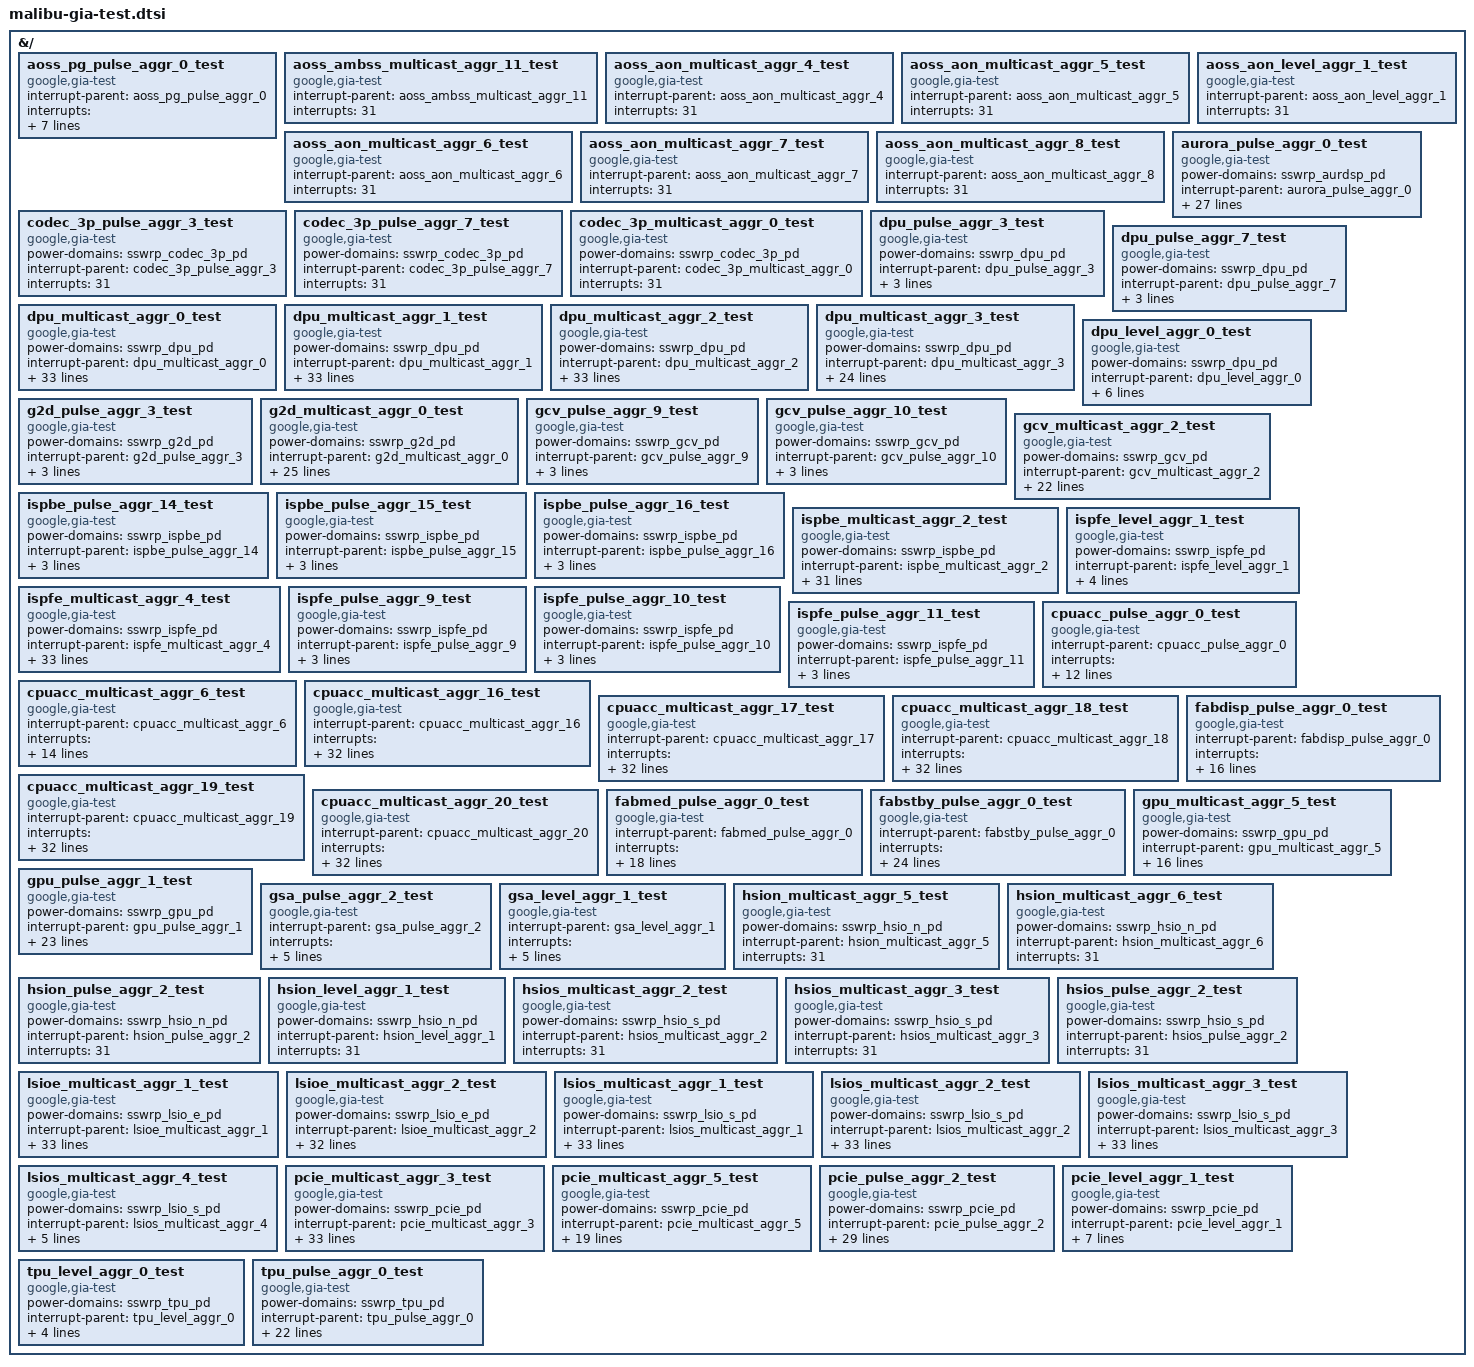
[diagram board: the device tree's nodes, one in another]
// SPDX-License-Identifier: GPL-2.0-only OR BSD-3-Clause
/*
 * !!!!!!!!!!!!!!!!!!!!!!!!!!!!!!!!!!!!!!!!!!!!!!!!!
 * !!!!! THIS IS A GENERATED FILE, DO NOT EDIT !!!!!
 * !!!!!!!!!!!!!!!!!!!!!!!!!!!!!!!!!!!!!!!!!!!!!!!!!
 *
 * This file provides test nodes for use with the GIA test driver
 * Generate using scripts/irqchip/gen-test-gia-dt-nodes.py
 *
 * Copyright 2024-2025 Google LLC
 */

#include <dt-bindings/interrupt-controller/mbu-gic.h>
#include <dt-bindings/interrupt-controller/irq-gia-google-mbu.h>

&{/} {
	aoss_pg_pulse_aggr_0_test: aoss_pg_pulse_aggr_0_test {
		compatible = "google,gia-test";
		interrupt-parent = <&aoss_pg_pulse_aggr_0>;
		interrupts =
			<AOSS_GIA_PULSE_AGGR_0_AUX_PARTITION_TBU_WRAPPER_TBU_RAS_FHI>,
			<AOSS_GIA_PULSE_AGGR_1_AUX_PARTITION_TBU_WRAPPER_TBU_RAS_ERI>,
			<AOSS_GIA_PULSE_AGGR_2_AUX_PARTITION_TBU_WRAPPER_TBU_RAS_CRI>,
			<AOSS_GIA_PULSE_AGGR_3_AUX_PARTITION_TBU_WRAPPER_TBU_PMU_IRPT>,
			<AOSS_GIA_PULSE_AGGR_4_AUX_GSPAN_AXI4_INIT_DNSTRM_ICD_ERR_DSCGT>,
			<AOSS_GIA_PULSE_AGGR_5_AUX_GSPAN_AXI4_INIT_PCIET_ICD_ERR_DSCGT>,
			<AOSS_GIA_PULSE_AGGR_6_AUX_GSPAN_ATB_INIT_INST_ICD_ERR_DSCGT>;
		interrupt-names =
			"AOSS_GIA_PULSE_AGGR_0_AUX_PARTITION_TBU_WRAPPER_TBU_RAS_FHI",
			"AOSS_GIA_PULSE_AGGR_1_AUX_PARTITION_TBU_WRAPPER_TBU_RAS_ERI",
			"AOSS_GIA_PULSE_AGGR_2_AUX_PARTITION_TBU_WRAPPER_TBU_RAS_CRI",
			"AOSS_GIA_PULSE_AGGR_3_AUX_PARTITION_TBU_WRAPPER_TBU_PMU_IRPT",
			"AOSS_GIA_PULSE_AGGR_4_AUX_GSPAN_AXI4_INIT_DNSTRM_ICD_ERR_DSCGT",
			"AOSS_GIA_PULSE_AGGR_5_AUX_GSPAN_AXI4_INIT_PCIET_ICD_ERR_DSCGT",
			"AOSS_GIA_PULSE_AGGR_6_AUX_GSPAN_ATB_INIT_INST_ICD_ERR_DSCGT";
	};

	aoss_ambss_multicast_aggr_11_test: aoss_ambss_multicast_aggr_11_test {
		compatible = "google,gia-test";
		interrupt-parent = <&aoss_ambss_multicast_aggr_11>;
		interrupts =
			<31>;
		interrupt-names =
			"TEST_LINE_31";
	};

	aoss_aon_multicast_aggr_4_test: aoss_aon_multicast_aggr_4_test {
		compatible = "google,gia-test";
		interrupt-parent = <&aoss_aon_multicast_aggr_4>;
		interrupts =
			<31>;
		interrupt-names =
			"TEST_LINE_31";
	};

	aoss_aon_multicast_aggr_5_test: aoss_aon_multicast_aggr_5_test {
		compatible = "google,gia-test";
		interrupt-parent = <&aoss_aon_multicast_aggr_5>;
		interrupts =
			<31>;
		interrupt-names =
			"TEST_LINE_31";
	};

	aoss_aon_multicast_aggr_6_test: aoss_aon_multicast_aggr_6_test {
		compatible = "google,gia-test";
		interrupt-parent = <&aoss_aon_multicast_aggr_6>;
		interrupts =
			<31>;
		interrupt-names =
			"TEST_LINE_31";
	};

	aoss_aon_multicast_aggr_7_test: aoss_aon_multicast_aggr_7_test {
		compatible = "google,gia-test";
		interrupt-parent = <&aoss_aon_multicast_aggr_7>;
		interrupts =
			<31>;
		interrupt-names =
			"TEST_LINE_31";
	};

	aoss_aon_multicast_aggr_8_test: aoss_aon_multicast_aggr_8_test {
		compatible = "google,gia-test";
		interrupt-parent = <&aoss_aon_multicast_aggr_8>;
		interrupts =
			<31>;
		interrupt-names =
			"TEST_LINE_31";
	};

	aoss_aon_level_aggr_1_test: aoss_aon_level_aggr_1_test {
		compatible = "google,gia-test";
		interrupt-parent = <&aoss_aon_level_aggr_1>;
		interrupts =
			<31>;
		interrupt-names =
			"TEST_LINE_31";
	};

	aurora_pulse_aggr_0_test: aurora_pulse_aggr_0_test {
		compatible = "google,gia-test";
		power-domains = <&sswrp_aurdsp_pd>;
		interrupt-parent = <&aurora_pulse_aggr_0>;
		interrupts =
			<AURORA_GIA_PULSE_AGGR_0_AUX_GSPAN_CORE_0_ICD_ERR_DSCGT>,
			<AURORA_GIA_PULSE_AGGR_0_AUX_GSPAN_CORE_1_ICD_ERR_DSCGT>,
			<AURORA_GIA_PULSE_AGGR_0_AUX_GSPAN_TCU_MCU_ICD_ERR_DSCGT>,
			<AURORA_GIA_PULSE_AGGR_0_AUX_GSPAN_ATB_ICD_ERR_DSCGT>,
			<AURORA_GIA_PULSE_AGGR_0_AUX_CTRL_NOC_XBA00_ERR_IRQ>,
			<AURORA_GIA_PULSE_AGGR_0_AUX_SMMU_TBU0_RAS_FHI>,
			<AURORA_GIA_PULSE_AGGR_0_AUX_SMMU_TBU0_RAS_ERI>,
			<AURORA_GIA_PULSE_AGGR_0_AUX_SMMU_TBU0_RAS_CRI>,
			<AURORA_GIA_PULSE_AGGR_0_AUX_SMMU_TBU0_PMU_IRPT>,
			<AURORA_GIA_PULSE_AGGR_0_AUX_SMMU_TBU1_RAS_FHI>,
			<AURORA_GIA_PULSE_AGGR_0_AUX_SMMU_TBU1_RAS_ERI>,
			<AURORA_GIA_PULSE_AGGR_0_AUX_SMMU_TBU1_RAS_CRI>,
			<AURORA_GIA_PULSE_AGGR_0_AUX_SMMU_TBU1_PMU_IRPT>,
			<AURORA_GIA_PULSE_AGGR_0_AUX_SMMU_TBU2_RAS_FHI>,
			<AURORA_GIA_PULSE_AGGR_0_AUX_SMMU_TBU2_RAS_ERI>,
			<AURORA_GIA_PULSE_AGGR_0_AUX_SMMU_TBU2_RAS_CRI>,
			<AURORA_GIA_PULSE_AGGR_0_AUX_SMMU_TBU2_PMU_IRPT>,
			<AURORA_GIA_PULSE_AGGR_0_AUX_SMMU_TCU_RAS_FHI>,
			<AURORA_GIA_PULSE_AGGR_0_AUX_SMMU_TCU_RAS_ERI>,
			<AURORA_GIA_PULSE_AGGR_0_AUX_SMMU_TCU_RAS_CRI>,
			<AURORA_GIA_PULSE_AGGR_0_AUX_SMMU_TCU_PMU_IRPT>,
			<AURORA_GIA_PULSE_AGGR_0_AUX_SMMU_TCU_PRI_Q_IRPT_NS>,
			<AURORA_GIA_PULSE_AGGR_0_AUX_SMMU_TCU_GLOBAL_IRPT_NS>,
			<AURORA_GIA_PULSE_AGGR_0_AUX_SMMU_TCU_CMD_SYNC_IRPT_NS>,
			<AURORA_GIA_PULSE_AGGR_0_AUX_SMMU_TCU_EVENT_Q_IRPT_NS>,
			<31>;
		interrupt-names =
			"AURORA_GIA_PULSE_AGGR_0_AUX_GSPAN_CORE_0_ICD_ERR_DSCGT",
			"AURORA_GIA_PULSE_AGGR_0_AUX_GSPAN_CORE_1_ICD_ERR_DSCGT",
			"AURORA_GIA_PULSE_AGGR_0_AUX_GSPAN_TCU_MCU_ICD_ERR_DSCGT",
			"AURORA_GIA_PULSE_AGGR_0_AUX_GSPAN_ATB_ICD_ERR_DSCGT",
			"AURORA_GIA_PULSE_AGGR_0_AUX_CTRL_NOC_XBA00_ERR_IRQ",
			"AURORA_GIA_PULSE_AGGR_0_AUX_SMMU_TBU0_RAS_FHI",
			"AURORA_GIA_PULSE_AGGR_0_AUX_SMMU_TBU0_RAS_ERI",
			"AURORA_GIA_PULSE_AGGR_0_AUX_SMMU_TBU0_RAS_CRI",
			"AURORA_GIA_PULSE_AGGR_0_AUX_SMMU_TBU0_PMU_IRPT",
			"AURORA_GIA_PULSE_AGGR_0_AUX_SMMU_TBU1_RAS_FHI",
			"AURORA_GIA_PULSE_AGGR_0_AUX_SMMU_TBU1_RAS_ERI",
			"AURORA_GIA_PULSE_AGGR_0_AUX_SMMU_TBU1_RAS_CRI",
			"AURORA_GIA_PULSE_AGGR_0_AUX_SMMU_TBU1_PMU_IRPT",
			"AURORA_GIA_PULSE_AGGR_0_AUX_SMMU_TBU2_RAS_FHI",
			"AURORA_GIA_PULSE_AGGR_0_AUX_SMMU_TBU2_RAS_ERI",
			"AURORA_GIA_PULSE_AGGR_0_AUX_SMMU_TBU2_RAS_CRI",
			"AURORA_GIA_PULSE_AGGR_0_AUX_SMMU_TBU2_PMU_IRPT",
			"AURORA_GIA_PULSE_AGGR_0_AUX_SMMU_TCU_RAS_FHI",
			"AURORA_GIA_PULSE_AGGR_0_AUX_SMMU_TCU_RAS_ERI",
			"AURORA_GIA_PULSE_AGGR_0_AUX_SMMU_TCU_RAS_CRI",
			"AURORA_GIA_PULSE_AGGR_0_AUX_SMMU_TCU_PMU_IRPT",
			"AURORA_GIA_PULSE_AGGR_0_AUX_SMMU_TCU_PRI_Q_IRPT_NS",
			"AURORA_GIA_PULSE_AGGR_0_AUX_SMMU_TCU_GLOBAL_IRPT_NS",
			"AURORA_GIA_PULSE_AGGR_0_AUX_SMMU_TCU_CMD_SYNC_IRPT_NS",
			"AURORA_GIA_PULSE_AGGR_0_AUX_SMMU_TCU_EVENT_Q_IRPT_NS",
			"TEST_LINE_31";
	};

	codec_3p_pulse_aggr_3_test: codec_3p_pulse_aggr_3_test {
		compatible = "google,gia-test";
		power-domains = <&sswrp_codec_3p_pd>;
		interrupt-parent = <&codec_3p_pulse_aggr_3>;
		interrupts =
			<31>;
		interrupt-names =
			"TEST_LINE_31";
	};

	codec_3p_pulse_aggr_7_test: codec_3p_pulse_aggr_7_test {
		compatible = "google,gia-test";
		power-domains = <&sswrp_codec_3p_pd>;
		interrupt-parent = <&codec_3p_pulse_aggr_7>;
		interrupts =
			<31>;
		interrupt-names =
			"TEST_LINE_31";
	};

	codec_3p_multicast_aggr_0_test: codec_3p_multicast_aggr_0_test {
		compatible = "google,gia-test";
		power-domains = <&sswrp_codec_3p_pd>;
		interrupt-parent = <&codec_3p_multicast_aggr_0>;
		interrupts =
			<31>;
		interrupt-names =
			"TEST_LINE_31";
	};

	dpu_pulse_aggr_3_test: dpu_pulse_aggr_3_test {
		compatible = "google,gia-test";
		power-domains = <&sswrp_dpu_pd>;
		interrupt-parent = <&dpu_pulse_aggr_3>;
		interrupts =
			<DPU_GIA_PULSE_AGGR_3_AUX_CORE_CORE_TBU_WRAPPER_0_TBU_PMU_IRPT>,
			<31>;
		interrupt-names =
			"DPU_GIA_PULSE_AGGR_3_AUX_CORE_CORE_TBU_WRAPPER_0_TBU_PMU_IRPT",
			"TEST_LINE_31";
	};

	dpu_pulse_aggr_7_test: dpu_pulse_aggr_7_test {
		compatible = "google,gia-test";
		power-domains = <&sswrp_dpu_pd>;
		interrupt-parent = <&dpu_pulse_aggr_7>;
		interrupts =
			<DPU_GIA_PULSE_AGGR_7_AUX_CORE_CORE_TBU_WRAPPER_1_TBU_PMU_IRPT>,
			<31>;
		interrupt-names =
			"DPU_GIA_PULSE_AGGR_7_AUX_CORE_CORE_TBU_WRAPPER_1_TBU_PMU_IRPT",
			"TEST_LINE_31";
	};

	dpu_multicast_aggr_0_test: dpu_multicast_aggr_0_test {
		compatible = "google,gia-test";
		power-domains = <&sswrp_dpu_pd>;
		interrupt-parent = <&dpu_multicast_aggr_0>;
		interrupts =
			<DPU_GIA_MULTICAST_AGGR_0_FE_0_IRQ_DPU_FE_PVRIC_DECODE_ERROR_0>,
			<DPU_GIA_MULTICAST_AGGR_0_FE_0_IRQ_DPU_FE_PVRIC_DECODE_ERROR_1>,
			<DPU_GIA_MULTICAST_AGGR_0_FE_0_IRQ_DPU_FE_PVRIC_DECODE_ERROR_2>,
			<DPU_GIA_MULTICAST_AGGR_0_FE_0_IRQ_DPU_FE_PVRIC_DECODE_ERROR_3>,
			<DPU_GIA_MULTICAST_AGGR_0_FE_0_IRQ_DPU_FE_PVRIC_DECODE_ERROR_4>,
			<DPU_GIA_MULTICAST_AGGR_0_FE_0_IRQ_DPU_FE_PVRIC_DECODE_ERROR_5>,
			<DPU_GIA_MULTICAST_AGGR_0_FE_0_IRQ_DPU_FE_LAYER_FRM_DONE_0>,
			<DPU_GIA_MULTICAST_AGGR_0_FE_0_IRQ_DPU_FE_LAYER_FRM_DONE_1>,
			<DPU_GIA_MULTICAST_AGGR_0_FE_0_IRQ_DPU_FE_LAYER_FRM_DONE_2>,
			<DPU_GIA_MULTICAST_AGGR_0_FE_0_IRQ_DPU_FE_LAYER_FRM_DONE_3>,
			<DPU_GIA_MULTICAST_AGGR_0_FE_0_IRQ_DPU_FE_LAYER_FRM_DONE_4>,
			<DPU_GIA_MULTICAST_AGGR_0_FE_0_IRQ_DPU_FE_LAYER_FRM_DONE_5>,
			<DPU_GIA_MULTICAST_AGGR_0_FE_0_IRQ_DPU_FE_AXI_HANG_0>,
			<DPU_GIA_MULTICAST_AGGR_0_FE_0_IRQ_DPU_FE_AXI_HANG_1>,
			<DPU_GIA_MULTICAST_AGGR_0_FE_0_IRQ_DPU_FE_AXI_BUS_ERROR_0>,
			<DPU_GIA_MULTICAST_AGGR_0_FE_0_IRQ_DPU_FE_AXI_BUS_ERROR_1>,
			<DPU_GIA_MULTICAST_AGGR_0_FE_0_IRQ_FE_APB_HANG>,
			<DPU_GIA_MULTICAST_AGGR_0_FE_0_IRQ_FE_SW_RST_DONE>,
			<DPU_GIA_MULTICAST_AGGR_0_FE_1_IRQ_DPU_FE_PVRIC_DECODE_ERROR_0>,
			<DPU_GIA_MULTICAST_AGGR_0_FE_1_IRQ_DPU_FE_PVRIC_DECODE_ERROR_1>,
			<DPU_GIA_MULTICAST_AGGR_0_FE_1_IRQ_DPU_FE_PVRIC_DECODE_ERROR_2>,
			<DPU_GIA_MULTICAST_AGGR_0_FE_1_IRQ_DPU_FE_PVRIC_DECODE_ERROR_3>,
			<DPU_GIA_MULTICAST_AGGR_0_FE_1_IRQ_DPU_FE_PVRIC_DECODE_ERROR_4>,
			<DPU_GIA_MULTICAST_AGGR_0_FE_1_IRQ_DPU_FE_PVRIC_DECODE_ERROR_5>,
			<DPU_GIA_MULTICAST_AGGR_0_FE_1_IRQ_DPU_FE_LAYER_FRM_DONE_0>,
			<DPU_GIA_MULTICAST_AGGR_0_FE_1_IRQ_DPU_FE_LAYER_FRM_DONE_1>,
			<DPU_GIA_MULTICAST_AGGR_0_FE_1_IRQ_DPU_FE_LAYER_FRM_DONE_2>,
			<DPU_GIA_MULTICAST_AGGR_0_FE_1_IRQ_DPU_FE_LAYER_FRM_DONE_3>,
			<DPU_GIA_MULTICAST_AGGR_0_FE_1_IRQ_DPU_FE_LAYER_FRM_DONE_4>,
			<DPU_GIA_MULTICAST_AGGR_0_FE_1_IRQ_DPU_FE_LAYER_FRM_DONE_5>,
			<DPU_GIA_MULTICAST_AGGR_0_FE_1_IRQ_DPU_FE_AXI_HANG_0>,
			<DPU_GIA_MULTICAST_AGGR_0_FE_1_IRQ_DPU_FE_AXI_HANG_1>;
		interrupt-names =
			"DPU_GIA_MULTICAST_AGGR_0_FE_0_IRQ_DPU_FE_PVRIC_DECODE_ERROR_0",
			"DPU_GIA_MULTICAST_AGGR_0_FE_0_IRQ_DPU_FE_PVRIC_DECODE_ERROR_1",
			"DPU_GIA_MULTICAST_AGGR_0_FE_0_IRQ_DPU_FE_PVRIC_DECODE_ERROR_2",
			"DPU_GIA_MULTICAST_AGGR_0_FE_0_IRQ_DPU_FE_PVRIC_DECODE_ERROR_3",
			"DPU_GIA_MULTICAST_AGGR_0_FE_0_IRQ_DPU_FE_PVRIC_DECODE_ERROR_4",
			"DPU_GIA_MULTICAST_AGGR_0_FE_0_IRQ_DPU_FE_PVRIC_DECODE_ERROR_5",
			"DPU_GIA_MULTICAST_AGGR_0_FE_0_IRQ_DPU_FE_LAYER_FRM_DONE_0",
			"DPU_GIA_MULTICAST_AGGR_0_FE_0_IRQ_DPU_FE_LAYER_FRM_DONE_1",
			"DPU_GIA_MULTICAST_AGGR_0_FE_0_IRQ_DPU_FE_LAYER_FRM_DONE_2",
			"DPU_GIA_MULTICAST_AGGR_0_FE_0_IRQ_DPU_FE_LAYER_FRM_DONE_3",
			"DPU_GIA_MULTICAST_AGGR_0_FE_0_IRQ_DPU_FE_LAYER_FRM_DONE_4",
			"DPU_GIA_MULTICAST_AGGR_0_FE_0_IRQ_DPU_FE_LAYER_FRM_DONE_5",
			"DPU_GIA_MULTICAST_AGGR_0_FE_0_IRQ_DPU_FE_AXI_HANG_0",
			"DPU_GIA_MULTICAST_AGGR_0_FE_0_IRQ_DPU_FE_AXI_HANG_1",
			"DPU_GIA_MULTICAST_AGGR_0_FE_0_IRQ_DPU_FE_AXI_BUS_ERROR_0",
			"DPU_GIA_MULTICAST_AGGR_0_FE_0_IRQ_DPU_FE_AXI_BUS_ERROR_1",
			"DPU_GIA_MULTICAST_AGGR_0_FE_0_IRQ_FE_APB_HANG",
			"DPU_GIA_MULTICAST_AGGR_0_FE_0_IRQ_FE_SW_RST_DONE",
			"DPU_GIA_MULTICAST_AGGR_0_FE_1_IRQ_DPU_FE_PVRIC_DECODE_ERROR_0",
			"DPU_GIA_MULTICAST_AGGR_0_FE_1_IRQ_DPU_FE_PVRIC_DECODE_ERROR_1",
			"DPU_GIA_MULTICAST_AGGR_0_FE_1_IRQ_DPU_FE_PVRIC_DECODE_ERROR_2",
			"DPU_GIA_MULTICAST_AGGR_0_FE_1_IRQ_DPU_FE_PVRIC_DECODE_ERROR_3",
			"DPU_GIA_MULTICAST_AGGR_0_FE_1_IRQ_DPU_FE_PVRIC_DECODE_ERROR_4",
			"DPU_GIA_MULTICAST_AGGR_0_FE_1_IRQ_DPU_FE_PVRIC_DECODE_ERROR_5",
			"DPU_GIA_MULTICAST_AGGR_0_FE_1_IRQ_DPU_FE_LAYER_FRM_DONE_0",
			"DPU_GIA_MULTICAST_AGGR_0_FE_1_IRQ_DPU_FE_LAYER_FRM_DONE_1",
			"DPU_GIA_MULTICAST_AGGR_0_FE_1_IRQ_DPU_FE_LAYER_FRM_DONE_2",
			"DPU_GIA_MULTICAST_AGGR_0_FE_1_IRQ_DPU_FE_LAYER_FRM_DONE_3",
			"DPU_GIA_MULTICAST_AGGR_0_FE_1_IRQ_DPU_FE_LAYER_FRM_DONE_4",
			"DPU_GIA_MULTICAST_AGGR_0_FE_1_IRQ_DPU_FE_LAYER_FRM_DONE_5",
			"DPU_GIA_MULTICAST_AGGR_0_FE_1_IRQ_DPU_FE_AXI_HANG_0",
			"DPU_GIA_MULTICAST_AGGR_0_FE_1_IRQ_DPU_FE_AXI_HANG_1";
	};

	dpu_multicast_aggr_1_test: dpu_multicast_aggr_1_test {
		compatible = "google,gia-test";
		power-domains = <&sswrp_dpu_pd>;
		interrupt-parent = <&dpu_multicast_aggr_1>;
		interrupts =
			<DPU_GIA_MULTICAST_AGGR_1_FE_1_IRQ_DPU_FE_AXI_BUS_ERROR_0>,
			<DPU_GIA_MULTICAST_AGGR_1_FE_1_IRQ_DPU_FE_AXI_BUS_ERROR_1>,
			<DPU_GIA_MULTICAST_AGGR_1_FE_1_IRQ_FE_APB_HANG>,
			<DPU_GIA_MULTICAST_AGGR_1_FE_1_IRQ_FE_SW_RST_DONE>,
			<DPU_GIA_MULTICAST_AGGR_1_BE_IRQ_BE_OUTPATH0_FRM_START>,
			<DPU_GIA_MULTICAST_AGGR_1_BE_IRQ_BE_OUTPATH0_FRM_DONE>,
			<DPU_GIA_MULTICAST_AGGR_1_BE_IRQ_BE_OUTPATH0_UNDERRUN>,
			<DPU_GIA_MULTICAST_AGGR_1_BE_IRQ_BE_OUTPATH0_INTRA_FRM_INT>,
			<DPU_GIA_MULTICAST_AGGR_1_BE_IRQ_BE_OUTPATH0_INTRA_FRM_EXT>,
			<DPU_GIA_MULTICAST_AGGR_1_BE_IRQ_BE_OUTPATH0_LTM_FRM_START>,
			<DPU_GIA_MULTICAST_AGGR_1_BE_IRQ_BE_OUTPATH0_LTM_FRM_DONE>,
			<DPU_GIA_MULTICAST_AGGR_1_BE_IRQ_BE_OUTPATH0_DSC_ENC0_INTR>,
			<DPU_GIA_MULTICAST_AGGR_1_BE_IRQ_BE_OUTPATH0_DSC_ENC1_INTR>,
			<DPU_GIA_MULTICAST_AGGR_1_BE_IRQ_BE_OUTPATH0_VDC_INTR>,
			<DPU_GIA_MULTICAST_AGGR_1_BE_IRQ_BE_OUTPATH0_HIST_WB_DONE>,
			<DPU_GIA_MULTICAST_AGGR_1_BE_IRQ_BE_OUTPATH0_HISTRGB_WB_DONE>,
			<DPU_GIA_MULTICAST_AGGR_1_BE_IRQ_BE_OUTPATH1_FRM_START>,
			<DPU_GIA_MULTICAST_AGGR_1_BE_IRQ_BE_OUTPATH1_FRM_DONE>,
			<DPU_GIA_MULTICAST_AGGR_1_BE_IRQ_BE_OUTPATH1_UNDERRUN>,
			<DPU_GIA_MULTICAST_AGGR_1_BE_IRQ_BE_OUTPATH1_INTRA_FRM_INT>,
			<DPU_GIA_MULTICAST_AGGR_1_BE_IRQ_BE_OUTPATH1_INTRA_FRM_EXT>,
			<DPU_GIA_MULTICAST_AGGR_1_BE_IRQ_BE_OUTPATH1_DSC_ENC0_INTR>,
			<DPU_GIA_MULTICAST_AGGR_1_BE_IRQ_BE_OUTPATH1_DSC_ENC1_INTR>,
			<DPU_GIA_MULTICAST_AGGR_1_BE_IRQ_BE_OUTPATH1_HIST_WB_DONE>,
			<DPU_GIA_MULTICAST_AGGR_1_BE_IRQ_BE_OUTPATH2_FRM_START>,
			<DPU_GIA_MULTICAST_AGGR_1_BE_IRQ_BE_OUTPATH2_FRM_DONE>,
			<DPU_GIA_MULTICAST_AGGR_1_BE_IRQ_BE_OUTPATH2_UNDERRUN>,
			<DPU_GIA_MULTICAST_AGGR_1_BE_IRQ_BE_OUTPATH2_INTRA_FRM_INT>,
			<DPU_GIA_MULTICAST_AGGR_1_BE_IRQ_BE_OUTPATH2_DSC_ENC0_INTR>,
			<DPU_GIA_MULTICAST_AGGR_1_BE_IRQ_BE_OUTPATH2_DSC_ENC1_INTR>,
			<DPU_GIA_MULTICAST_AGGR_1_BE_IRQ_BE_OUTPATH3_FRM_START>,
			<DPU_GIA_MULTICAST_AGGR_1_BE_IRQ_BE_OUTPATH3_FRM_DONE>;
		interrupt-names =
			"DPU_GIA_MULTICAST_AGGR_1_FE_1_IRQ_DPU_FE_AXI_BUS_ERROR_0",
			"DPU_GIA_MULTICAST_AGGR_1_FE_1_IRQ_DPU_FE_AXI_BUS_ERROR_1",
			"DPU_GIA_MULTICAST_AGGR_1_FE_1_IRQ_FE_APB_HANG",
			"DPU_GIA_MULTICAST_AGGR_1_FE_1_IRQ_FE_SW_RST_DONE",
			"DPU_GIA_MULTICAST_AGGR_1_BE_IRQ_BE_OUTPATH0_FRM_START",
			"DPU_GIA_MULTICAST_AGGR_1_BE_IRQ_BE_OUTPATH0_FRM_DONE",
			"DPU_GIA_MULTICAST_AGGR_1_BE_IRQ_BE_OUTPATH0_UNDERRUN",
			"DPU_GIA_MULTICAST_AGGR_1_BE_IRQ_BE_OUTPATH0_INTRA_FRM_INT",
			"DPU_GIA_MULTICAST_AGGR_1_BE_IRQ_BE_OUTPATH0_INTRA_FRM_EXT",
			"DPU_GIA_MULTICAST_AGGR_1_BE_IRQ_BE_OUTPATH0_LTM_FRM_START",
			"DPU_GIA_MULTICAST_AGGR_1_BE_IRQ_BE_OUTPATH0_LTM_FRM_DONE",
			"DPU_GIA_MULTICAST_AGGR_1_BE_IRQ_BE_OUTPATH0_DSC_ENC0_INTR",
			"DPU_GIA_MULTICAST_AGGR_1_BE_IRQ_BE_OUTPATH0_DSC_ENC1_INTR",
			"DPU_GIA_MULTICAST_AGGR_1_BE_IRQ_BE_OUTPATH0_VDC_INTR",
			"DPU_GIA_MULTICAST_AGGR_1_BE_IRQ_BE_OUTPATH0_HIST_WB_DONE",
			"DPU_GIA_MULTICAST_AGGR_1_BE_IRQ_BE_OUTPATH0_HISTRGB_WB_DONE",
			"DPU_GIA_MULTICAST_AGGR_1_BE_IRQ_BE_OUTPATH1_FRM_START",
			"DPU_GIA_MULTICAST_AGGR_1_BE_IRQ_BE_OUTPATH1_FRM_DONE",
			"DPU_GIA_MULTICAST_AGGR_1_BE_IRQ_BE_OUTPATH1_UNDERRUN",
			"DPU_GIA_MULTICAST_AGGR_1_BE_IRQ_BE_OUTPATH1_INTRA_FRM_INT",
			"DPU_GIA_MULTICAST_AGGR_1_BE_IRQ_BE_OUTPATH1_INTRA_FRM_EXT",
			"DPU_GIA_MULTICAST_AGGR_1_BE_IRQ_BE_OUTPATH1_DSC_ENC0_INTR",
			"DPU_GIA_MULTICAST_AGGR_1_BE_IRQ_BE_OUTPATH1_DSC_ENC1_INTR",
			"DPU_GIA_MULTICAST_AGGR_1_BE_IRQ_BE_OUTPATH1_HIST_WB_DONE",
			"DPU_GIA_MULTICAST_AGGR_1_BE_IRQ_BE_OUTPATH2_FRM_START",
			"DPU_GIA_MULTICAST_AGGR_1_BE_IRQ_BE_OUTPATH2_FRM_DONE",
			"DPU_GIA_MULTICAST_AGGR_1_BE_IRQ_BE_OUTPATH2_UNDERRUN",
			"DPU_GIA_MULTICAST_AGGR_1_BE_IRQ_BE_OUTPATH2_INTRA_FRM_INT",
			"DPU_GIA_MULTICAST_AGGR_1_BE_IRQ_BE_OUTPATH2_DSC_ENC0_INTR",
			"DPU_GIA_MULTICAST_AGGR_1_BE_IRQ_BE_OUTPATH2_DSC_ENC1_INTR",
			"DPU_GIA_MULTICAST_AGGR_1_BE_IRQ_BE_OUTPATH3_FRM_START",
			"DPU_GIA_MULTICAST_AGGR_1_BE_IRQ_BE_OUTPATH3_FRM_DONE";
	};

	dpu_multicast_aggr_2_test: dpu_multicast_aggr_2_test {
		compatible = "google,gia-test";
		power-domains = <&sswrp_dpu_pd>;
		interrupt-parent = <&dpu_multicast_aggr_2>;
		interrupts =
			<DPU_GIA_MULTICAST_AGGR_2_BE_IRQ_BE_OUTPATH3_UNDERRUN>,
			<DPU_GIA_MULTICAST_AGGR_2_BE_IRQ_BE_OUTPATH3_INTRA_FRM_INT>,
			<DPU_GIA_MULTICAST_AGGR_2_BE_IRQ_BE_BLD_WB_FRM_DONE>,
			<DPU_GIA_MULTICAST_AGGR_2_BE_IRQ_BE_POST_WB0_FRM_DONE>,
			<DPU_GIA_MULTICAST_AGGR_2_BE_IRQ_BE_POST_WB1_FRM_DONE>,
			<DPU_GIA_MULTICAST_AGGR_2_BE_IRQ_DPU_BE_PANEL_CTL_PROTECTION_0>,
			<DPU_GIA_MULTICAST_AGGR_2_BE_IRQ_DPU_BE_PANEL_CTL_PROTECTION_1>,
			<DPU_GIA_MULTICAST_AGGR_2_BE_IRQ_DPU_BE_PANEL_CTL_PROTECTION_2>,
			<DPU_GIA_MULTICAST_AGGR_2_BE_IRQ_DPU_BE_PANEL_CTL_PROTECTION_3>,
			<DPU_GIA_MULTICAST_AGGR_2_BE_IRQ_DPU_BE_PANEL_CTL_PROTECTION_4>,
			<DPU_GIA_MULTICAST_AGGR_2_BE_IRQ_BE_OUTPATH0_PVRIC_DECODE_INTR>,
			<DPU_GIA_MULTICAST_AGGR_2_BE_IRQ_BE_OUTPATH1_PVRIC_DECODE_INTR>,
			<DPU_GIA_MULTICAST_AGGR_2_BE_IRQ_BE_APB_HANG>,
			<DPU_GIA_MULTICAST_AGGR_2_BE_IRQ_BE_SW_RST_DONE>,
			<DPU_GIA_MULTICAST_AGGR_2_BE_IRQ_BE_AXI_BUS_ERROR>,
			<DPU_GIA_MULTICAST_AGGR_2_BE_IRQ_BE_AXI_RD_BUS_HANG>,
			<DPU_GIA_MULTICAST_AGGR_2_BE_IRQ_BE_AXI_WR_BUS_HANG>,
			<DPU_GIA_MULTICAST_AGGR_2_BE_IRQ_BE_WB0_DATALOST_INTR>,
			<DPU_GIA_MULTICAST_AGGR_2_BE_IRQ_BE_WB1_DATALOST_INTR>,
			<DPU_GIA_MULTICAST_AGGR_2_PDMA_NS_AP_IRQ_0>,
			<DPU_GIA_MULTICAST_AGGR_2_PDMA_NS_AP_IRQ_1>,
			<DPU_GIA_MULTICAST_AGGR_2_PDMA_NS_AP_IRQ_2>,
			<DPU_GIA_MULTICAST_AGGR_2_PDMA_NS_AP_IRQ_3>,
			<DPU_GIA_MULTICAST_AGGR_2_AUX_CORE_CORE_GEM_0_IRQ>,
			<DPU_GIA_MULTICAST_AGGR_2_AUX_CORE_CORE_GEM_1_IRQ>,
			<DPU_GIA_MULTICAST_AGGR_2_AUX_CORE_CORE_GEM_2_IRQ>,
			<DPU_GIA_MULTICAST_AGGR_2_AUX_CORE_CORE_GEM_3_IRQ>,
			<DPU_GIA_MULTICAST_AGGR_2_AUX_CORE_CORE_GEM_4_IRQ>,
			<DPU_GIA_MULTICAST_AGGR_2_AUX_CORE_IRQ_DUMMY_GIA_LEAF_WRAPPER_PULSE_AGGR_INTR_0>,
			<DPU_GIA_MULTICAST_AGGR_2_AUX_CORE_IRQ_DUMMY_GIA_LEAF_WRAPPER_PULSE_AGGR_INTR_1>,
			<DPU_GIA_MULTICAST_AGGR_2_AUX_CORE_IRQ_DUMMY_GIA_LEAF_WRAPPER_PULSE_AGGR_INTR_2>,
			<DPU_GIA_MULTICAST_AGGR_2_AUX_CORE_IRQ_DUMMY_GIA_LEAF_WRAPPER_PULSE_AGGR_INTR_3>;
		interrupt-names =
			"DPU_GIA_MULTICAST_AGGR_2_BE_IRQ_BE_OUTPATH3_UNDERRUN",
			"DPU_GIA_MULTICAST_AGGR_2_BE_IRQ_BE_OUTPATH3_INTRA_FRM_INT",
			"DPU_GIA_MULTICAST_AGGR_2_BE_IRQ_BE_BLD_WB_FRM_DONE",
			"DPU_GIA_MULTICAST_AGGR_2_BE_IRQ_BE_POST_WB0_FRM_DONE",
			"DPU_GIA_MULTICAST_AGGR_2_BE_IRQ_BE_POST_WB1_FRM_DONE",
			"DPU_GIA_MULTICAST_AGGR_2_BE_IRQ_DPU_BE_PANEL_CTL_PROTECTION_0",
			"DPU_GIA_MULTICAST_AGGR_2_BE_IRQ_DPU_BE_PANEL_CTL_PROTECTION_1",
			"DPU_GIA_MULTICAST_AGGR_2_BE_IRQ_DPU_BE_PANEL_CTL_PROTECTION_2",
			"DPU_GIA_MULTICAST_AGGR_2_BE_IRQ_DPU_BE_PANEL_CTL_PROTECTION_3",
			"DPU_GIA_MULTICAST_AGGR_2_BE_IRQ_DPU_BE_PANEL_CTL_PROTECTION_4",
			"DPU_GIA_MULTICAST_AGGR_2_BE_IRQ_BE_OUTPATH0_PVRIC_DECODE_INTR",
			"DPU_GIA_MULTICAST_AGGR_2_BE_IRQ_BE_OUTPATH1_PVRIC_DECODE_INTR",
			"DPU_GIA_MULTICAST_AGGR_2_BE_IRQ_BE_APB_HANG",
			"DPU_GIA_MULTICAST_AGGR_2_BE_IRQ_BE_SW_RST_DONE",
			"DPU_GIA_MULTICAST_AGGR_2_BE_IRQ_BE_AXI_BUS_ERROR",
			"DPU_GIA_MULTICAST_AGGR_2_BE_IRQ_BE_AXI_RD_BUS_HANG",
			"DPU_GIA_MULTICAST_AGGR_2_BE_IRQ_BE_AXI_WR_BUS_HANG",
			"DPU_GIA_MULTICAST_AGGR_2_BE_IRQ_BE_WB0_DATALOST_INTR",
			"DPU_GIA_MULTICAST_AGGR_2_BE_IRQ_BE_WB1_DATALOST_INTR",
			"DPU_GIA_MULTICAST_AGGR_2_PDMA_NS_AP_IRQ_0",
			"DPU_GIA_MULTICAST_AGGR_2_PDMA_NS_AP_IRQ_1",
			"DPU_GIA_MULTICAST_AGGR_2_PDMA_NS_AP_IRQ_2",
			"DPU_GIA_MULTICAST_AGGR_2_PDMA_NS_AP_IRQ_3",
			"DPU_GIA_MULTICAST_AGGR_2_AUX_CORE_CORE_GEM_0_IRQ",
			"DPU_GIA_MULTICAST_AGGR_2_AUX_CORE_CORE_GEM_1_IRQ",
			"DPU_GIA_MULTICAST_AGGR_2_AUX_CORE_CORE_GEM_2_IRQ",
			"DPU_GIA_MULTICAST_AGGR_2_AUX_CORE_CORE_GEM_3_IRQ",
			"DPU_GIA_MULTICAST_AGGR_2_AUX_CORE_CORE_GEM_4_IRQ",
			"DPU_GIA_MULTICAST_AGGR_2_AUX_CORE_IRQ_DUMMY_GIA_LEAF_WRAPPER_PULSE_AGGR_INTR_0",
			"DPU_GIA_MULTICAST_AGGR_2_AUX_CORE_IRQ_DUMMY_GIA_LEAF_WRAPPER_PULSE_AGGR_INTR_1",
			"DPU_GIA_MULTICAST_AGGR_2_AUX_CORE_IRQ_DUMMY_GIA_LEAF_WRAPPER_PULSE_AGGR_INTR_2",
			"DPU_GIA_MULTICAST_AGGR_2_AUX_CORE_IRQ_DUMMY_GIA_LEAF_WRAPPER_PULSE_AGGR_INTR_3";
	};

	dpu_multicast_aggr_3_test: dpu_multicast_aggr_3_test {
		compatible = "google,gia-test";
		power-domains = <&sswrp_dpu_pd>;
		interrupt-parent = <&dpu_multicast_aggr_3>;
		interrupts =
			<DPU_GIA_MULTICAST_AGGR_3_AUX_CORE_CORE_RA_0_NS_INTR>,
			<DPU_GIA_MULTICAST_AGGR_3_AUX_CORE_CORE_RA_1_NS_INTR>,
			<DPU_GIA_MULTICAST_AGGR_3_AUX_CORE_CORE_RA_2_NS_INTR>,
			<DPU_GIA_MULTICAST_AGGR_3_AUX_CORE_CORE_RA_3_NS_INTR>,
			<DPU_GIA_MULTICAST_AGGR_3_AUX_CORE_CORE_RA_4_NS_INTR>,
			<DPU_GIA_MULTICAST_AGGR_3_AUX_CORE_CFGFAB_CFGFAB_RFW_CFGBRG_XFW_NS_INTR>,
			<DPU_GIA_MULTICAST_AGGR_3_AUX_AON_AON_CORE_AON_CORE_RFW_APBMULTI_XFW_NS_INTR>,
			<DPU_GIA_MULTICAST_AGGR_3_AUX_AON_AON_CORE_AON_CORE_RFW_LPCM_XFW_NS_INTR>,
			<DPU_GIA_MULTICAST_AGGR_3_AUX_CORE_CORE_TBU_WRAPPER_0_MFW_NS_IRQ>,
			<DPU_GIA_MULTICAST_AGGR_3_AUX_CORE_CORE_TBU_WRAPPER_1_MFW_NS_IRQ>,
			<DPU_GIA_MULTICAST_AGGR_3_AUX_CORE_CPDISPDPU_IFABRIC_DISP_XBA00_ERR_IRQ>,
			<DPU_GIA_MULTICAST_AGGR_3_DSI_SS_TOP_DSI0_IRQ>,
			<DPU_GIA_MULTICAST_AGGR_3_DSI_SS_TOP_DSI1_IRQ>,
			<DPU_GIA_MULTICAST_AGGR_3_AUX_CORE_IRQ_DUMMY_GIA_LEAF_WRAPPER_PULSE_AGGR_INTR_4>,
			<DPU_GIA_MULTICAST_AGGR_3_AUX_CORE_IRQ_DUMMY_GIA_LEAF_WRAPPER_PULSE_AGGR_INTR_5>,
			<DPU_GIA_MULTICAST_AGGR_3_AUX_CORE_IRQ_DUMMY_GIA_LEAF_WRAPPER_PULSE_AGGR_INTR_6>,
			<DPU_GIA_MULTICAST_AGGR_3_AUX_CORE_IRQ_DUMMY_GIA_LEAF_WRAPPER_PULSE_AGGR_INTR_7>,
			<DPU_GIA_MULTICAST_AGGR_3_AUX_CORE_IRQ_DUMMY_GIA_LEAF_WRAPPER_PULSE_AGGR_INTR_8>,
			<DPU_GIA_MULTICAST_AGGR_3_AUX_CORE_IRQ_DUMMY_GIA_LEAF_WRAPPER_PULSE_AGGR_INTR_9>,
			<DPU_GIA_MULTICAST_AGGR_3_AUX_CORE_IRQ_DUMMY_GIA_LEAF_WRAPPER_PULSE_AGGR_INTR_10>,
			<DPU_GIA_MULTICAST_AGGR_3_AUX_CORE_IRQ_DUMMY_GIA_LEAF_WRAPPER_PULSE_AGGR_INTR_11>,
			<DPU_GIA_MULTICAST_AGGR_3_AUX_CORE_IRQ_DUMMY_GIA_LEAF_WRAPPER_PULSE_AGGR_INTR_12>,
			<31>;
		interrupt-names =
			"DPU_GIA_MULTICAST_AGGR_3_AUX_CORE_CORE_RA_0_NS_INTR",
			"DPU_GIA_MULTICAST_AGGR_3_AUX_CORE_CORE_RA_1_NS_INTR",
			"DPU_GIA_MULTICAST_AGGR_3_AUX_CORE_CORE_RA_2_NS_INTR",
			"DPU_GIA_MULTICAST_AGGR_3_AUX_CORE_CORE_RA_3_NS_INTR",
			"DPU_GIA_MULTICAST_AGGR_3_AUX_CORE_CORE_RA_4_NS_INTR",
			"DPU_GIA_MULTICAST_AGGR_3_AUX_CORE_CFGFAB_CFGFAB_RFW_CFGBRG_XFW_NS_INTR",
			"DPU_GIA_MULTICAST_AGGR_3_AUX_AON_AON_CORE_AON_CORE_RFW_APBMULTI_XFW_NS_INTR",
			"DPU_GIA_MULTICAST_AGGR_3_AUX_AON_AON_CORE_AON_CORE_RFW_LPCM_XFW_NS_INTR",
			"DPU_GIA_MULTICAST_AGGR_3_AUX_CORE_CORE_TBU_WRAPPER_0_MFW_NS_IRQ",
			"DPU_GIA_MULTICAST_AGGR_3_AUX_CORE_CORE_TBU_WRAPPER_1_MFW_NS_IRQ",
			"DPU_GIA_MULTICAST_AGGR_3_AUX_CORE_CPDISPDPU_IFABRIC_DISP_XBA00_ERR_IRQ",
			"DPU_GIA_MULTICAST_AGGR_3_DSI_SS_TOP_DSI0_IRQ",
			"DPU_GIA_MULTICAST_AGGR_3_DSI_SS_TOP_DSI1_IRQ",
			"DPU_GIA_MULTICAST_AGGR_3_AUX_CORE_IRQ_DUMMY_GIA_LEAF_WRAPPER_PULSE_AGGR_INTR_4",
			"DPU_GIA_MULTICAST_AGGR_3_AUX_CORE_IRQ_DUMMY_GIA_LEAF_WRAPPER_PULSE_AGGR_INTR_5",
			"DPU_GIA_MULTICAST_AGGR_3_AUX_CORE_IRQ_DUMMY_GIA_LEAF_WRAPPER_PULSE_AGGR_INTR_6",
			"DPU_GIA_MULTICAST_AGGR_3_AUX_CORE_IRQ_DUMMY_GIA_LEAF_WRAPPER_PULSE_AGGR_INTR_7",
			"DPU_GIA_MULTICAST_AGGR_3_AUX_CORE_IRQ_DUMMY_GIA_LEAF_WRAPPER_PULSE_AGGR_INTR_8",
			"DPU_GIA_MULTICAST_AGGR_3_AUX_CORE_IRQ_DUMMY_GIA_LEAF_WRAPPER_PULSE_AGGR_INTR_9",
			"DPU_GIA_MULTICAST_AGGR_3_AUX_CORE_IRQ_DUMMY_GIA_LEAF_WRAPPER_PULSE_AGGR_INTR_10",
			"DPU_GIA_MULTICAST_AGGR_3_AUX_CORE_IRQ_DUMMY_GIA_LEAF_WRAPPER_PULSE_AGGR_INTR_11",
			"DPU_GIA_MULTICAST_AGGR_3_AUX_CORE_IRQ_DUMMY_GIA_LEAF_WRAPPER_PULSE_AGGR_INTR_12",
			"TEST_LINE_31";
	};

	dpu_level_aggr_0_test: dpu_level_aggr_0_test {
		compatible = "google,gia-test";
		power-domains = <&sswrp_dpu_pd>;
		interrupt-parent = <&dpu_level_aggr_0>;
		interrupts =
			<DPU_GIA_LEVEL_AGGR_0_AUX_AON_GIA_GIA_GIA_MULTICAST_AGGR_INTR_0>,
			<DPU_GIA_LEVEL_AGGR_0_AUX_AON_GIA_GIA_GIA_MULTICAST_AGGR_INTR_1>,
			<DPU_GIA_LEVEL_AGGR_0_AUX_AON_GIA_GIA_GIA_MULTICAST_AGGR_INTR_2>,
			<DPU_GIA_LEVEL_AGGR_0_AUX_AON_GIA_GIA_GIA_MULTICAST_AGGR_INTR_3>,
			<31>;
		interrupt-names =
			"DPU_GIA_LEVEL_AGGR_0_AUX_AON_GIA_GIA_GIA_MULTICAST_AGGR_INTR_0",
			"DPU_GIA_LEVEL_AGGR_0_AUX_AON_GIA_GIA_GIA_MULTICAST_AGGR_INTR_1",
			"DPU_GIA_LEVEL_AGGR_0_AUX_AON_GIA_GIA_GIA_MULTICAST_AGGR_INTR_2",
			"DPU_GIA_LEVEL_AGGR_0_AUX_AON_GIA_GIA_GIA_MULTICAST_AGGR_INTR_3",
			"TEST_LINE_31";
	};

	g2d_pulse_aggr_3_test: g2d_pulse_aggr_3_test {
		compatible = "google,gia-test";
		power-domains = <&sswrp_g2d_pd>;
		interrupt-parent = <&g2d_pulse_aggr_3>;
		interrupts =
			<G2D_GIA_PULSE_AGGR_3_AUX_CORE_CORE_TBU_WRAPPER_TBU_PMU_IRPT>,
			<31>;
		interrupt-names =
			"G2D_GIA_PULSE_AGGR_3_AUX_CORE_CORE_TBU_WRAPPER_TBU_PMU_IRPT",
			"TEST_LINE_31";
	};

	g2d_multicast_aggr_0_test: g2d_multicast_aggr_0_test {
		compatible = "google,gia-test";
		power-domains = <&sswrp_g2d_pd>;
		interrupt-parent = <&g2d_multicast_aggr_0>;
		interrupts =
			<G2D_GIA_MULTICAST_AGGR_0_IP_IRQ_PIPE0_PVRIC_ENCODE_ERROR>,
			<G2D_GIA_MULTICAST_AGGR_0_IP_IRQ_PIPE0_PVRIC_DECODE_ERROR>,
			<G2D_GIA_MULTICAST_AGGR_0_IP_IRQ_AXI_BUS_ERROR>,
			<G2D_GIA_MULTICAST_AGGR_0_IP_IRQ_AXI_WR_BUS_HANG>,
			<G2D_GIA_MULTICAST_AGGR_0_IP_IRQ_AXI_RD_BUS_HANG>,
			<G2D_GIA_MULTICAST_AGGR_0_IP_IRQ_APB_HANG>,
			<G2D_GIA_MULTICAST_AGGR_0_IP_IRQ_PIPE0_FRAME_DONE>,
			<G2D_GIA_MULTICAST_AGGR_0_IP_IRQ_PIPE0_FRAME_START>,
			<G2D_GIA_MULTICAST_AGGR_0_IP_IRQ_SW_RST_DONE>,
			<G2D_GIA_MULTICAST_AGGR_0_AUX_CORE_CORE_PDMA_QCHWRAP_NS_AP_IRQ>,
			<G2D_GIA_MULTICAST_AGGR_0_AUX_CORE_CORE_GEM_IRQ>,
			<G2D_GIA_MULTICAST_AGGR_0_AUX_CORE_CORE_RA_NS_INTR>,
			<G2D_GIA_MULTICAST_AGGR_0_AUX_CORE_CORE_RFW_CFGBRG_XFW_NS_INTR>,
			<G2D_GIA_MULTICAST_AGGR_0_AUX_AON_AON_CORE_AON_CORE_RFW_LPCM_XFW_NS_INTR>,
			<G2D_GIA_MULTICAST_AGGR_0_AUX_AON_AON_CORE_AON_CORE_RFW_AON_XFW_NS_INTR>,
			<G2D_GIA_MULTICAST_AGGR_0_AUX_CORE_CORE_TBU_WRAPPER_MFW_NS_IRQ>,
			<G2D_GIA_MULTICAST_AGGR_0_AUX_CORE_CPDISPG2D_IFABRIC_DISP_XBA00_ERR_IRQ>,
			<G2D_GIA_MULTICAST_AGGR_0_AUX_CORE_IRQ_DUMMY_GIA_LEAF_WRAPPER_PULSE_AGGR_INTR_0>,
			<G2D_GIA_MULTICAST_AGGR_0_AUX_CORE_IRQ_DUMMY_GIA_LEAF_WRAPPER_PULSE_AGGR_INTR_1>,
			<G2D_GIA_MULTICAST_AGGR_0_AUX_CORE_IRQ_DUMMY_GIA_LEAF_WRAPPER_PULSE_AGGR_INTR_2>,
			<G2D_GIA_MULTICAST_AGGR_0_AUX_CORE_IRQ_DUMMY_GIA_LEAF_WRAPPER_PULSE_AGGR_INTR_3>,
			<G2D_GIA_MULTICAST_AGGR_0_AUX_CORE_IRQ_DUMMY_GIA_LEAF_WRAPPER_PULSE_AGGR_INTR_4>,
			<G2D_GIA_MULTICAST_AGGR_0_AUX_CORE_IRQ_DUMMY_GIA_LEAF_WRAPPER_PULSE_AGGR_INTR_5>,
			<31>;
		interrupt-names =
			"G2D_GIA_MULTICAST_AGGR_0_IP_IRQ_PIPE0_PVRIC_ENCODE_ERROR",
			"G2D_GIA_MULTICAST_AGGR_0_IP_IRQ_PIPE0_PVRIC_DECODE_ERROR",
			"G2D_GIA_MULTICAST_AGGR_0_IP_IRQ_AXI_BUS_ERROR",
			"G2D_GIA_MULTICAST_AGGR_0_IP_IRQ_AXI_WR_BUS_HANG",
			"G2D_GIA_MULTICAST_AGGR_0_IP_IRQ_AXI_RD_BUS_HANG",
			"G2D_GIA_MULTICAST_AGGR_0_IP_IRQ_APB_HANG",
			"G2D_GIA_MULTICAST_AGGR_0_IP_IRQ_PIPE0_FRAME_DONE",
			"G2D_GIA_MULTICAST_AGGR_0_IP_IRQ_PIPE0_FRAME_START",
			"G2D_GIA_MULTICAST_AGGR_0_IP_IRQ_SW_RST_DONE",
			"G2D_GIA_MULTICAST_AGGR_0_AUX_CORE_CORE_PDMA_QCHWRAP_NS_AP_IRQ",
			"G2D_GIA_MULTICAST_AGGR_0_AUX_CORE_CORE_GEM_IRQ",
			"G2D_GIA_MULTICAST_AGGR_0_AUX_CORE_CORE_RA_NS_INTR",
			"G2D_GIA_MULTICAST_AGGR_0_AUX_CORE_CORE_RFW_CFGBRG_XFW_NS_INTR",
			"G2D_GIA_MULTICAST_AGGR_0_AUX_AON_AON_CORE_AON_CORE_RFW_LPCM_XFW_NS_INTR",
			"G2D_GIA_MULTICAST_AGGR_0_AUX_AON_AON_CORE_AON_CORE_RFW_AON_XFW_NS_INTR",
			"G2D_GIA_MULTICAST_AGGR_0_AUX_CORE_CORE_TBU_WRAPPER_MFW_NS_IRQ",
			"G2D_GIA_MULTICAST_AGGR_0_AUX_CORE_CPDISPG2D_IFABRIC_DISP_XBA00_ERR_IRQ",
			"G2D_GIA_MULTICAST_AGGR_0_AUX_CORE_IRQ_DUMMY_GIA_LEAF_WRAPPER_PULSE_AGGR_INTR_0",
			"G2D_GIA_MULTICAST_AGGR_0_AUX_CORE_IRQ_DUMMY_GIA_LEAF_WRAPPER_PULSE_AGGR_INTR_1",
			"G2D_GIA_MULTICAST_AGGR_0_AUX_CORE_IRQ_DUMMY_GIA_LEAF_WRAPPER_PULSE_AGGR_INTR_2",
			"G2D_GIA_MULTICAST_AGGR_0_AUX_CORE_IRQ_DUMMY_GIA_LEAF_WRAPPER_PULSE_AGGR_INTR_3",
			"G2D_GIA_MULTICAST_AGGR_0_AUX_CORE_IRQ_DUMMY_GIA_LEAF_WRAPPER_PULSE_AGGR_INTR_4",
			"G2D_GIA_MULTICAST_AGGR_0_AUX_CORE_IRQ_DUMMY_GIA_LEAF_WRAPPER_PULSE_AGGR_INTR_5",
			"TEST_LINE_31";
	};

	gcv_pulse_aggr_9_test: gcv_pulse_aggr_9_test {
		compatible = "google,gia-test";
		power-domains = <&sswrp_gcv_pd>;
		interrupt-parent = <&gcv_pulse_aggr_9>;
		interrupts =
			<GCV_GIA_PULSE_AGGR_9_AUX_PD_AUX_QCHWRAP_RGCG_INTF_TBU0_TBU_WRAPPER_TBU_PMU_IRPT>,
			<31>;
		interrupt-names =
			"GCV_GIA_PULSE_AGGR_9_AUX_PD_AUX_QCHWRAP_RGCG_INTF_TBU0_TBU_WRAPPER_TBU_PMU_IRPT",
			"TEST_LINE_31";
	};

	gcv_pulse_aggr_10_test: gcv_pulse_aggr_10_test {
		compatible = "google,gia-test";
		power-domains = <&sswrp_gcv_pd>;
		interrupt-parent = <&gcv_pulse_aggr_10>;
		interrupts =
			<GCV_GIA_PULSE_AGGR_10_AUX_PD_AUX_QCHWRAP_RGCG_INTF_TBU1_TBU_WRAPPER_TBU_PMU_IRPT>,
			<31>;
		interrupt-names =
			"GCV_GIA_PULSE_AGGR_10_AUX_PD_AUX_QCHWRAP_RGCG_INTF_TBU1_TBU_WRAPPER_TBU_PMU_IRPT",
			"TEST_LINE_31";
	};

	gcv_multicast_aggr_2_test: gcv_multicast_aggr_2_test {
		compatible = "google,gia-test";
		power-domains = <&sswrp_gcv_pd>;
		interrupt-parent = <&gcv_multicast_aggr_2>;
		interrupts =
			<GCV_GIA_MULTICAST_AGGR_2_AUX_PD_AUX_QCHWRAP_XBA0_ERR_IRQ>,
			<GCV_GIA_MULTICAST_AGGR_2_AUX_PD_AUX_QCHWRAP_PG_GEM_IRQ_0>,
			<GCV_GIA_MULTICAST_AGGR_2_AUX_PD_AUX_QCHWRAP_PG_GEM_IRQ_1>,
			<GCV_GIA_MULTICAST_AGGR_2_AUX_PD_AUX_QCHWRAP_PG_NS_MFW_IRQ_0>,
			<GCV_GIA_MULTICAST_AGGR_2_AUX_PD_AUX_QCHWRAP_PG_NS_MFW_IRQ_1>,
			<GCV_GIA_MULTICAST_AGGR_2_AUX_PD_AUX_QCHWRAP_PG_NS_RA_IRQ_0>,
			<GCV_GIA_MULTICAST_AGGR_2_AUX_PD_AUX_QCHWRAP_PG_NS_RA_IRQ_1>,
			<GCV_GIA_MULTICAST_AGGR_2_AUX_PD_AUX_QCHWRAP_NS_RFW_IRQ>,
			<GCV_GIA_MULTICAST_AGGR_2_AUX_PD_AUX_AON_AON_RFW_NS_INTR>,
			<GCV_GIA_MULTICAST_AGGR_2_AUX_PD_AUX_QCHWRAP_DUMMY_GIA_LEAF_WRAPPER_PULSE_AGGR_INTR_0>,
			<GCV_GIA_MULTICAST_AGGR_2_AUX_PD_AUX_QCHWRAP_DUMMY_GIA_LEAF_WRAPPER_PULSE_AGGR_INTR_1>,
			<GCV_GIA_MULTICAST_AGGR_2_AUX_PD_AUX_QCHWRAP_DUMMY_GIA_LEAF_WRAPPER_PULSE_AGGR_INTR_2>,
			<GCV_GIA_MULTICAST_AGGR_2_AUX_PD_AUX_QCHWRAP_DUMMY_GIA_LEAF_WRAPPER_PULSE_AGGR_INTR_3>,
			<GCV_GIA_MULTICAST_AGGR_2_AUX_PD_AUX_QCHWRAP_DUMMY_GIA_LEAF_WRAPPER_PULSE_AGGR_INTR_4>,
			<GCV_GIA_MULTICAST_AGGR_2_AUX_PD_AUX_QCHWRAP_DUMMY_GIA_LEAF_WRAPPER_PULSE_AGGR_INTR_5>,
			<GCV_GIA_MULTICAST_AGGR_2_AUX_PD_AUX_QCHWRAP_DUMMY_GIA_LEAF_WRAPPER_PULSE_AGGR_INTR_6>,
			<GCV_GIA_MULTICAST_AGGR_2_AUX_PD_AUX_QCHWRAP_DUMMY_GIA_LEAF_WRAPPER_PULSE_AGGR_INTR_7>,
			<GCV_GIA_MULTICAST_AGGR_2_AUX_PD_AUX_QCHWRAP_DUMMY_GIA_LEAF_WRAPPER_PULSE_AGGR_INTR_8>,
			<GCV_GIA_MULTICAST_AGGR_2_AUX_PD_AUX_QCHWRAP_DUMMY_GIA_LEAF_WRAPPER_PULSE_AGGR_INTR_9>,
			<GCV_GIA_MULTICAST_AGGR_2_AUX_PD_AUX_QCHWRAP_DUMMY_GIA_LEAF_WRAPPER_PULSE_AGGR_INTR_10>,
			<31>;
		interrupt-names =
			"GCV_GIA_MULTICAST_AGGR_2_AUX_PD_AUX_QCHWRAP_XBA0_ERR_IRQ",
			"GCV_GIA_MULTICAST_AGGR_2_AUX_PD_AUX_QCHWRAP_PG_GEM_IRQ_0",
			"GCV_GIA_MULTICAST_AGGR_2_AUX_PD_AUX_QCHWRAP_PG_GEM_IRQ_1",
			"GCV_GIA_MULTICAST_AGGR_2_AUX_PD_AUX_QCHWRAP_PG_NS_MFW_IRQ_0",
			"GCV_GIA_MULTICAST_AGGR_2_AUX_PD_AUX_QCHWRAP_PG_NS_MFW_IRQ_1",
			"GCV_GIA_MULTICAST_AGGR_2_AUX_PD_AUX_QCHWRAP_PG_NS_RA_IRQ_0",
			"GCV_GIA_MULTICAST_AGGR_2_AUX_PD_AUX_QCHWRAP_PG_NS_RA_IRQ_1",
			"GCV_GIA_MULTICAST_AGGR_2_AUX_PD_AUX_QCHWRAP_NS_RFW_IRQ",
			"GCV_GIA_MULTICAST_AGGR_2_AUX_PD_AUX_AON_AON_RFW_NS_INTR",
			"GCV_GIA_MULTICAST_AGGR_2_AUX_PD_AUX_QCHWRAP_DUMMY_GIA_LEAF_WRAPPER_PULSE_AGGR_INTR_0",
			"GCV_GIA_MULTICAST_AGGR_2_AUX_PD_AUX_QCHWRAP_DUMMY_GIA_LEAF_WRAPPER_PULSE_AGGR_INTR_1",
			"GCV_GIA_MULTICAST_AGGR_2_AUX_PD_AUX_QCHWRAP_DUMMY_GIA_LEAF_WRAPPER_PULSE_AGGR_INTR_2",
			"GCV_GIA_MULTICAST_AGGR_2_AUX_PD_AUX_QCHWRAP_DUMMY_GIA_LEAF_WRAPPER_PULSE_AGGR_INTR_3",
			"GCV_GIA_MULTICAST_AGGR_2_AUX_PD_AUX_QCHWRAP_DUMMY_GIA_LEAF_WRAPPER_PULSE_AGGR_INTR_4",
			"GCV_GIA_MULTICAST_AGGR_2_AUX_PD_AUX_QCHWRAP_DUMMY_GIA_LEAF_WRAPPER_PULSE_AGGR_INTR_5",
			"GCV_GIA_MULTICAST_AGGR_2_AUX_PD_AUX_QCHWRAP_DUMMY_GIA_LEAF_WRAPPER_PULSE_AGGR_INTR_6",
			"GCV_GIA_MULTICAST_AGGR_2_AUX_PD_AUX_QCHWRAP_DUMMY_GIA_LEAF_WRAPPER_PULSE_AGGR_INTR_7",
			"GCV_GIA_MULTICAST_AGGR_2_AUX_PD_AUX_QCHWRAP_DUMMY_GIA_LEAF_WRAPPER_PULSE_AGGR_INTR_8",
			"GCV_GIA_MULTICAST_AGGR_2_AUX_PD_AUX_QCHWRAP_DUMMY_GIA_LEAF_WRAPPER_PULSE_AGGR_INTR_9",
			"GCV_GIA_MULTICAST_AGGR_2_AUX_PD_AUX_QCHWRAP_DUMMY_GIA_LEAF_WRAPPER_PULSE_AGGR_INTR_10",
			"TEST_LINE_31";
	};

	ispbe_pulse_aggr_14_test: ispbe_pulse_aggr_14_test {
		compatible = "google,gia-test";
		power-domains = <&sswrp_ispbe_pd>;
		interrupt-parent = <&ispbe_pulse_aggr_14>;
		interrupts =
			<ISPBE_GIA_PULSE_AGGR_14_AUX_PD_AUX_QCHWRAP_RGCG_INTF_DATA_PORT_0_TBU_WRAPPER_TBU_PMU_IRPT>,
			<31>;
		interrupt-names =
			"ISPBE_GIA_PULSE_AGGR_14_AUX_PD_AUX_QCHWRAP_RGCG_INTF_DATA_PORT_0_TBU_WRAPPER_TBU_PMU_IRPT",
			"TEST_LINE_31";
	};

	ispbe_pulse_aggr_15_test: ispbe_pulse_aggr_15_test {
		compatible = "google,gia-test";
		power-domains = <&sswrp_ispbe_pd>;
		interrupt-parent = <&ispbe_pulse_aggr_15>;
		interrupts =
			<ISPBE_GIA_PULSE_AGGR_15_AUX_PD_AUX_QCHWRAP_RGCG_INTF_DATA_PORT_1_TBU_WRAPPER_TBU_PMU_IRPT>,
			<31>;
		interrupt-names =
			"ISPBE_GIA_PULSE_AGGR_15_AUX_PD_AUX_QCHWRAP_RGCG_INTF_DATA_PORT_1_TBU_WRAPPER_TBU_PMU_IRPT",
			"TEST_LINE_31";
	};

	ispbe_pulse_aggr_16_test: ispbe_pulse_aggr_16_test {
		compatible = "google,gia-test";
		power-domains = <&sswrp_ispbe_pd>;
		interrupt-parent = <&ispbe_pulse_aggr_16>;
		interrupts =
			<ISPBE_GIA_PULSE_AGGR_16_AUX_PD_AUX_QCHWRAP_RGCG_INTF_DATA_PORT_2_TBU_WRAPPER_TBU_PMU_IRPT>,
			<31>;
		interrupt-names =
			"ISPBE_GIA_PULSE_AGGR_16_AUX_PD_AUX_QCHWRAP_RGCG_INTF_DATA_PORT_2_TBU_WRAPPER_TBU_PMU_IRPT",
			"TEST_LINE_31";
	};

	ispbe_multicast_aggr_2_test: ispbe_multicast_aggr_2_test {
		compatible = "google,gia-test";
		power-domains = <&sswrp_ispbe_pd>;
		interrupt-parent = <&ispbe_multicast_aggr_2>;
		interrupts =
			<ISPBE_GIA_MULTICAST_AGGR_2_AUX_PD_AUX_QCHWRAP_XBA0_ERR_IRQ>,
			<ISPBE_GIA_MULTICAST_AGGR_2_AUX_PD_AUX_QCHWRAP_PG_GEM_IRQ_0>,
			<ISPBE_GIA_MULTICAST_AGGR_2_AUX_PD_AUX_QCHWRAP_PG_GEM_IRQ_1>,
			<ISPBE_GIA_MULTICAST_AGGR_2_AUX_PD_AUX_QCHWRAP_PG_GEM_IRQ_2>,
			<ISPBE_GIA_MULTICAST_AGGR_2_AUX_PD_AUX_QCHWRAP_PG_NS_MFW_IRQ_0>,
			<ISPBE_GIA_MULTICAST_AGGR_2_AUX_PD_AUX_QCHWRAP_PG_NS_MFW_IRQ_1>,
			<ISPBE_GIA_MULTICAST_AGGR_2_AUX_PD_AUX_QCHWRAP_PG_NS_MFW_IRQ_2>,
			<ISPBE_GIA_MULTICAST_AGGR_2_AUX_PD_AUX_QCHWRAP_PG_NS_RA_IRQ_0>,
			<ISPBE_GIA_MULTICAST_AGGR_2_AUX_PD_AUX_QCHWRAP_PG_NS_RA_IRQ_1>,
			<ISPBE_GIA_MULTICAST_AGGR_2_AUX_PD_AUX_QCHWRAP_PG_NS_RA_IRQ_2>,
			<ISPBE_GIA_MULTICAST_AGGR_2_AUX_PD_AUX_QCHWRAP_NS_RFW_IRQ>,
			<ISPBE_GIA_MULTICAST_AGGR_2_AUX_PD_AUX_AON_AON_RFW_XFW_NS_INTR>,
			<ISPBE_GIA_MULTICAST_AGGR_2_AUX_PD_AUX_QCHWRAP_DUMMY_GIA_LEAF_WRAPPER_PULSE_AGGR_INTR_0>,
			<ISPBE_GIA_MULTICAST_AGGR_2_AUX_PD_AUX_QCHWRAP_DUMMY_GIA_LEAF_WRAPPER_PULSE_AGGR_INTR_1>,
			<ISPBE_GIA_MULTICAST_AGGR_2_AUX_PD_AUX_QCHWRAP_DUMMY_GIA_LEAF_WRAPPER_PULSE_AGGR_INTR_2>,
			<ISPBE_GIA_MULTICAST_AGGR_2_AUX_PD_AUX_QCHWRAP_DUMMY_GIA_LEAF_WRAPPER_PULSE_AGGR_INTR_3>,
			<ISPBE_GIA_MULTICAST_AGGR_2_AUX_PD_AUX_QCHWRAP_DUMMY_GIA_LEAF_WRAPPER_PULSE_AGGR_INTR_4>,
			<ISPBE_GIA_MULTICAST_AGGR_2_AUX_PD_AUX_QCHWRAP_DUMMY_GIA_LEAF_WRAPPER_PULSE_AGGR_INTR_5>,
			<ISPBE_GIA_MULTICAST_AGGR_2_AUX_PD_AUX_QCHWRAP_DUMMY_GIA_LEAF_WRAPPER_PULSE_AGGR_INTR_6>,
			<ISPBE_GIA_MULTICAST_AGGR_2_AUX_PD_AUX_QCHWRAP_DUMMY_GIA_LEAF_WRAPPER_PULSE_AGGR_INTR_7>,
			<ISPBE_GIA_MULTICAST_AGGR_2_AUX_PD_AUX_QCHWRAP_DUMMY_GIA_LEAF_WRAPPER_PULSE_AGGR_INTR_8>,
			<ISPBE_GIA_MULTICAST_AGGR_2_AUX_PD_AUX_QCHWRAP_DUMMY_GIA_LEAF_WRAPPER_PULSE_AGGR_INTR_9>,
			<ISPBE_GIA_MULTICAST_AGGR_2_AUX_PD_AUX_QCHWRAP_DUMMY_GIA_LEAF_WRAPPER_PULSE_AGGR_INTR_10>,
			<ISPBE_GIA_MULTICAST_AGGR_2_AUX_PD_AUX_QCHWRAP_DUMMY_GIA_LEAF_WRAPPER_PULSE_AGGR_INTR_11>,
			<ISPBE_GIA_MULTICAST_AGGR_2_AUX_PD_AUX_QCHWRAP_DUMMY_GIA_LEAF_WRAPPER_PULSE_AGGR_INTR_12>,
			<ISPBE_GIA_MULTICAST_AGGR_2_AUX_PD_AUX_QCHWRAP_DUMMY_GIA_LEAF_WRAPPER_PULSE_AGGR_INTR_13>,
			<ISPBE_GIA_MULTICAST_AGGR_2_AUX_PD_AUX_QCHWRAP_DUMMY_GIA_LEAF_WRAPPER_PULSE_AGGR_INTR_14>,
			<ISPBE_GIA_MULTICAST_AGGR_2_AUX_PD_AUX_QCHWRAP_DUMMY_GIA_LEAF_WRAPPER_PULSE_AGGR_INTR_15>,
			<ISPBE_GIA_MULTICAST_AGGR_2_AUX_PD_AUX_QCHWRAP_DUMMY_GIA_LEAF_WRAPPER_PULSE_AGGR_INTR_16>,
			<31>;
		interrupt-names =
			"ISPBE_GIA_MULTICAST_AGGR_2_AUX_PD_AUX_QCHWRAP_XBA0_ERR_IRQ",
			"ISPBE_GIA_MULTICAST_AGGR_2_AUX_PD_AUX_QCHWRAP_PG_GEM_IRQ_0",
			"ISPBE_GIA_MULTICAST_AGGR_2_AUX_PD_AUX_QCHWRAP_PG_GEM_IRQ_1",
			"ISPBE_GIA_MULTICAST_AGGR_2_AUX_PD_AUX_QCHWRAP_PG_GEM_IRQ_2",
			"ISPBE_GIA_MULTICAST_AGGR_2_AUX_PD_AUX_QCHWRAP_PG_NS_MFW_IRQ_0",
			"ISPBE_GIA_MULTICAST_AGGR_2_AUX_PD_AUX_QCHWRAP_PG_NS_MFW_IRQ_1",
			"ISPBE_GIA_MULTICAST_AGGR_2_AUX_PD_AUX_QCHWRAP_PG_NS_MFW_IRQ_2",
			"ISPBE_GIA_MULTICAST_AGGR_2_AUX_PD_AUX_QCHWRAP_PG_NS_RA_IRQ_0",
			"ISPBE_GIA_MULTICAST_AGGR_2_AUX_PD_AUX_QCHWRAP_PG_NS_RA_IRQ_1",
			"ISPBE_GIA_MULTICAST_AGGR_2_AUX_PD_AUX_QCHWRAP_PG_NS_RA_IRQ_2",
			"ISPBE_GIA_MULTICAST_AGGR_2_AUX_PD_AUX_QCHWRAP_NS_RFW_IRQ",
			"ISPBE_GIA_MULTICAST_AGGR_2_AUX_PD_AUX_AON_AON_RFW_XFW_NS_INTR",
			"ISPBE_GIA_MULTICAST_AGGR_2_AUX_PD_AUX_QCHWRAP_DUMMY_GIA_LEAF_WRAPPER_PULSE_AGGR_INTR_0",
			"ISPBE_GIA_MULTICAST_AGGR_2_AUX_PD_AUX_QCHWRAP_DUMMY_GIA_LEAF_WRAPPER_PULSE_AGGR_INTR_1",
			"ISPBE_GIA_MULTICAST_AGGR_2_AUX_PD_AUX_QCHWRAP_DUMMY_GIA_LEAF_WRAPPER_PULSE_AGGR_INTR_2",
			"ISPBE_GIA_MULTICAST_AGGR_2_AUX_PD_AUX_QCHWRAP_DUMMY_GIA_LEAF_WRAPPER_PULSE_AGGR_INTR_3",
			"ISPBE_GIA_MULTICAST_AGGR_2_AUX_PD_AUX_QCHWRAP_DUMMY_GIA_LEAF_WRAPPER_PULSE_AGGR_INTR_4",
			"ISPBE_GIA_MULTICAST_AGGR_2_AUX_PD_AUX_QCHWRAP_DUMMY_GIA_LEAF_WRAPPER_PULSE_AGGR_INTR_5",
			"ISPBE_GIA_MULTICAST_AGGR_2_AUX_PD_AUX_QCHWRAP_DUMMY_GIA_LEAF_WRAPPER_PULSE_AGGR_INTR_6",
			"ISPBE_GIA_MULTICAST_AGGR_2_AUX_PD_AUX_QCHWRAP_DUMMY_GIA_LEAF_WRAPPER_PULSE_AGGR_INTR_7",
			"ISPBE_GIA_MULTICAST_AGGR_2_AUX_PD_AUX_QCHWRAP_DUMMY_GIA_LEAF_WRAPPER_PULSE_AGGR_INTR_8",
			"ISPBE_GIA_MULTICAST_AGGR_2_AUX_PD_AUX_QCHWRAP_DUMMY_GIA_LEAF_WRAPPER_PULSE_AGGR_INTR_9",
			"ISPBE_GIA_MULTICAST_AGGR_2_AUX_PD_AUX_QCHWRAP_DUMMY_GIA_LEAF_WRAPPER_PULSE_AGGR_INTR_10",
			"ISPBE_GIA_MULTICAST_AGGR_2_AUX_PD_AUX_QCHWRAP_DUMMY_GIA_LEAF_WRAPPER_PULSE_AGGR_INTR_11",
			"ISPBE_GIA_MULTICAST_AGGR_2_AUX_PD_AUX_QCHWRAP_DUMMY_GIA_LEAF_WRAPPER_PULSE_AGGR_INTR_12",
			"ISPBE_GIA_MULTICAST_AGGR_2_AUX_PD_AUX_QCHWRAP_DUMMY_GIA_LEAF_WRAPPER_PULSE_AGGR_INTR_13",
			"ISPBE_GIA_MULTICAST_AGGR_2_AUX_PD_AUX_QCHWRAP_DUMMY_GIA_LEAF_WRAPPER_PULSE_AGGR_INTR_14",
			"ISPBE_GIA_MULTICAST_AGGR_2_AUX_PD_AUX_QCHWRAP_DUMMY_GIA_LEAF_WRAPPER_PULSE_AGGR_INTR_15",
			"ISPBE_GIA_MULTICAST_AGGR_2_AUX_PD_AUX_QCHWRAP_DUMMY_GIA_LEAF_WRAPPER_PULSE_AGGR_INTR_16",
			"TEST_LINE_31";
	};

	ispfe_level_aggr_1_test: ispfe_level_aggr_1_test {
		compatible = "google,gia-test";
		power-domains = <&sswrp_ispfe_pd>;
		interrupt-parent = <&ispfe_level_aggr_1>;
		interrupts =
			<ISPFE_GIA_LEVEL_AGGR_1_AUX_AON_AON_GIA_MULTICAST_AGGR_INTR_5>,
			<ISPFE_GIA_LEVEL_AGGR_1_AUX_AON_AON_GIA_MULTICAST_AGGR_INTR_4>,
			<31>;
		interrupt-names =
			"ISPFE_GIA_LEVEL_AGGR_1_AUX_AON_AON_GIA_MULTICAST_AGGR_INTR_5",
			"ISPFE_GIA_LEVEL_AGGR_1_AUX_AON_AON_GIA_MULTICAST_AGGR_INTR_4",
			"TEST_LINE_31";
	};

	ispfe_multicast_aggr_4_test: ispfe_multicast_aggr_4_test {
		compatible = "google,gia-test";
		power-domains = <&sswrp_ispfe_pd>;
		interrupt-parent = <&ispfe_multicast_aggr_4>;
		interrupts =
			<ISPFE_GIA_MULTICAST_AGGR_4_AUX_DATA_RA_TOP0_NS_INTR>,
			<ISPFE_GIA_MULTICAST_AGGR_4_AUX_DATA_RA_TOP1_NS_INTR>,
			<ISPFE_GIA_MULTICAST_AGGR_4_AUX_DATA_RA_TOP2_NS_INTR>,
			<ISPFE_GIA_MULTICAST_AGGR_4_AUX_TBU_WRAPPER_0_MFW_NS_IRQ>,
			<ISPFE_GIA_MULTICAST_AGGR_4_AUX_TBU_WRAPPER_1_MFW_NS_IRQ>,
			<ISPFE_GIA_MULTICAST_AGGR_4_AUX_TBU_WRAPPER_2_MFW_NS_IRQ>,
			<ISPFE_GIA_MULTICAST_AGGR_4_AUX_CFG_BRG_RFW_NS_INTR>,
			<ISPFE_GIA_MULTICAST_AGGR_4_AUX_CFG_BRG_MFW_NS_INTR>,
			<ISPFE_GIA_MULTICAST_AGGR_4_AUX_DUMMY_GIA_LEAF_WRAPPER_PULSE_AGGR_INTR_0>,
			<ISPFE_GIA_MULTICAST_AGGR_4_AUX_DUMMY_GIA_LEAF_WRAPPER_PULSE_AGGR_INTR_3>,
			<ISPFE_GIA_MULTICAST_AGGR_4_AUX_DUMMY_GIA_LEAF_WRAPPER_PULSE_AGGR_INTR_6>,
			<ISPFE_GIA_MULTICAST_AGGR_4_AUX_DUMMY_GIA_LEAF_WRAPPER_PULSE_AGGR_INTR_9>,
			<ISPFE_GIA_MULTICAST_AGGR_4_AUX_DUMMY_GIA_LEAF_WRAPPER_PULSE_AGGR_INTR_1>,
			<ISPFE_GIA_MULTICAST_AGGR_4_AUX_DUMMY_GIA_LEAF_WRAPPER_PULSE_AGGR_INTR_4>,
			<ISPFE_GIA_MULTICAST_AGGR_4_AUX_DUMMY_GIA_LEAF_WRAPPER_PULSE_AGGR_INTR_7>,
			<ISPFE_GIA_MULTICAST_AGGR_4_AUX_DUMMY_GIA_LEAF_WRAPPER_PULSE_AGGR_INTR_10>,
			<ISPFE_GIA_MULTICAST_AGGR_4_AUX_DUMMY_GIA_LEAF_WRAPPER_PULSE_AGGR_INTR_2>,
			<ISPFE_GIA_MULTICAST_AGGR_4_AUX_DUMMY_GIA_LEAF_WRAPPER_PULSE_AGGR_INTR_5>,
			<ISPFE_GIA_MULTICAST_AGGR_4_AUX_DUMMY_GIA_LEAF_WRAPPER_PULSE_AGGR_INTR_8>,
			<ISPFE_GIA_MULTICAST_AGGR_4_AUX_DUMMY_GIA_LEAF_WRAPPER_PULSE_AGGR_INTR_11>,
			<ISPFE_GIA_MULTICAST_AGGR_4_AUX_DATA_GEM_TOP0_IRQ>,
			<ISPFE_GIA_MULTICAST_AGGR_4_AUX_DATA_GEM_TOP1_IRQ>,
			<ISPFE_GIA_MULTICAST_AGGR_4_AUX_DATA_GEM_TOP2_IRQ>,
			<ISPFE_GIA_MULTICAST_AGGR_4_AUX_AON_AON_RFW_LPCM_NS_INTR>,
			<ISPFE_GIA_MULTICAST_AGGR_4_AUX_DUMMY_GIA_LEAF_WRAPPER_PULSE_AGGR_INTR_12>,
			<ISPFE_GIA_MULTICAST_AGGR_4_AUX_DUMMY_GIA_LEAF_WRAPPER_PULSE_AGGR_INTR_13>,
			<ISPFE_GIA_MULTICAST_AGGR_4_AUX_DUMMY_GIA_LEAF_WRAPPER_PULSE_AGGR_INTR_14>,
			<ISPFE_GIA_MULTICAST_AGGR_4_AUX_DUMMY_GIA_LEAF_WRAPPER_PULSE_AGGR_INTR_15>,
			<ISPFE_GIA_MULTICAST_AGGR_4_AUX_DUMMY_GIA_LEAF_WRAPPER_PULSE_AGGR_INTR_24>,
			<ISPFE_GIA_MULTICAST_AGGR_4_AUX_DUMMY_GIA_LEAF_WRAPPER_PULSE_AGGR_INTR_25>,
			<ISPFE_GIA_MULTICAST_AGGR_4_AUX_DUMMY_GIA_LEAF_WRAPPER_PULSE_AGGR_INTR_26>,
			<ISPFE_GIA_MULTICAST_AGGR_4_AUX_DUMMY_GIA_LEAF_WRAPPER_PULSE_AGGR_INTR_27>;
		interrupt-names =
			"ISPFE_GIA_MULTICAST_AGGR_4_AUX_DATA_RA_TOP0_NS_INTR",
			"ISPFE_GIA_MULTICAST_AGGR_4_AUX_DATA_RA_TOP1_NS_INTR",
			"ISPFE_GIA_MULTICAST_AGGR_4_AUX_DATA_RA_TOP2_NS_INTR",
			"ISPFE_GIA_MULTICAST_AGGR_4_AUX_TBU_WRAPPER_0_MFW_NS_IRQ",
			"ISPFE_GIA_MULTICAST_AGGR_4_AUX_TBU_WRAPPER_1_MFW_NS_IRQ",
			"ISPFE_GIA_MULTICAST_AGGR_4_AUX_TBU_WRAPPER_2_MFW_NS_IRQ",
			"ISPFE_GIA_MULTICAST_AGGR_4_AUX_CFG_BRG_RFW_NS_INTR",
			"ISPFE_GIA_MULTICAST_AGGR_4_AUX_CFG_BRG_MFW_NS_INTR",
			"ISPFE_GIA_MULTICAST_AGGR_4_AUX_DUMMY_GIA_LEAF_WRAPPER_PULSE_AGGR_INTR_0",
			"ISPFE_GIA_MULTICAST_AGGR_4_AUX_DUMMY_GIA_LEAF_WRAPPER_PULSE_AGGR_INTR_3",
			"ISPFE_GIA_MULTICAST_AGGR_4_AUX_DUMMY_GIA_LEAF_WRAPPER_PULSE_AGGR_INTR_6",
			"ISPFE_GIA_MULTICAST_AGGR_4_AUX_DUMMY_GIA_LEAF_WRAPPER_PULSE_AGGR_INTR_9",
			"ISPFE_GIA_MULTICAST_AGGR_4_AUX_DUMMY_GIA_LEAF_WRAPPER_PULSE_AGGR_INTR_1",
			"ISPFE_GIA_MULTICAST_AGGR_4_AUX_DUMMY_GIA_LEAF_WRAPPER_PULSE_AGGR_INTR_4",
			"ISPFE_GIA_MULTICAST_AGGR_4_AUX_DUMMY_GIA_LEAF_WRAPPER_PULSE_AGGR_INTR_7",
			"ISPFE_GIA_MULTICAST_AGGR_4_AUX_DUMMY_GIA_LEAF_WRAPPER_PULSE_AGGR_INTR_10",
			"ISPFE_GIA_MULTICAST_AGGR_4_AUX_DUMMY_GIA_LEAF_WRAPPER_PULSE_AGGR_INTR_2",
			"ISPFE_GIA_MULTICAST_AGGR_4_AUX_DUMMY_GIA_LEAF_WRAPPER_PULSE_AGGR_INTR_5",
			"ISPFE_GIA_MULTICAST_AGGR_4_AUX_DUMMY_GIA_LEAF_WRAPPER_PULSE_AGGR_INTR_8",
			"ISPFE_GIA_MULTICAST_AGGR_4_AUX_DUMMY_GIA_LEAF_WRAPPER_PULSE_AGGR_INTR_11",
			"ISPFE_GIA_MULTICAST_AGGR_4_AUX_DATA_GEM_TOP0_IRQ",
			"ISPFE_GIA_MULTICAST_AGGR_4_AUX_DATA_GEM_TOP1_IRQ",
			"ISPFE_GIA_MULTICAST_AGGR_4_AUX_DATA_GEM_TOP2_IRQ",
			"ISPFE_GIA_MULTICAST_AGGR_4_AUX_AON_AON_RFW_LPCM_NS_INTR",
			"ISPFE_GIA_MULTICAST_AGGR_4_AUX_DUMMY_GIA_LEAF_WRAPPER_PULSE_AGGR_INTR_12",
			"ISPFE_GIA_MULTICAST_AGGR_4_AUX_DUMMY_GIA_LEAF_WRAPPER_PULSE_AGGR_INTR_13",
			"ISPFE_GIA_MULTICAST_AGGR_4_AUX_DUMMY_GIA_LEAF_WRAPPER_PULSE_AGGR_INTR_14",
			"ISPFE_GIA_MULTICAST_AGGR_4_AUX_DUMMY_GIA_LEAF_WRAPPER_PULSE_AGGR_INTR_15",
			"ISPFE_GIA_MULTICAST_AGGR_4_AUX_DUMMY_GIA_LEAF_WRAPPER_PULSE_AGGR_INTR_24",
			"ISPFE_GIA_MULTICAST_AGGR_4_AUX_DUMMY_GIA_LEAF_WRAPPER_PULSE_AGGR_INTR_25",
			"ISPFE_GIA_MULTICAST_AGGR_4_AUX_DUMMY_GIA_LEAF_WRAPPER_PULSE_AGGR_INTR_26",
			"ISPFE_GIA_MULTICAST_AGGR_4_AUX_DUMMY_GIA_LEAF_WRAPPER_PULSE_AGGR_INTR_27";
	};

	ispfe_pulse_aggr_9_test: ispfe_pulse_aggr_9_test {
		compatible = "google,gia-test";
		power-domains = <&sswrp_ispfe_pd>;
		interrupt-parent = <&ispfe_pulse_aggr_9>;
		interrupts =
			<ISPFE_GIA_PULSE_AGGR_9_AUX_TBU_WRAPPER_0_TBU_PMU_IRPT>,
			<31>;
		interrupt-names =
			"ISPFE_GIA_PULSE_AGGR_9_AUX_TBU_WRAPPER_0_TBU_PMU_IRPT",
			"TEST_LINE_31";
	};

	ispfe_pulse_aggr_10_test: ispfe_pulse_aggr_10_test {
		compatible = "google,gia-test";
		power-domains = <&sswrp_ispfe_pd>;
		interrupt-parent = <&ispfe_pulse_aggr_10>;
		interrupts =
			<ISPFE_GIA_PULSE_AGGR_10_AUX_TBU_WRAPPER_1_TBU_PMU_IRPT>,
			<31>;
		interrupt-names =
			"ISPFE_GIA_PULSE_AGGR_10_AUX_TBU_WRAPPER_1_TBU_PMU_IRPT",
			"TEST_LINE_31";
	};

	ispfe_pulse_aggr_11_test: ispfe_pulse_aggr_11_test {
		compatible = "google,gia-test";
		power-domains = <&sswrp_ispfe_pd>;
		interrupt-parent = <&ispfe_pulse_aggr_11>;
		interrupts =
			<ISPFE_GIA_PULSE_AGGR_11_AUX_TBU_WRAPPER_2_TBU_PMU_IRPT>,
			<31>;
		interrupt-names =
			"ISPFE_GIA_PULSE_AGGR_11_AUX_TBU_WRAPPER_2_TBU_PMU_IRPT",
			"TEST_LINE_31";
	};

	cpuacc_pulse_aggr_0_test: cpuacc_pulse_aggr_0_test {
		compatible = "google,gia-test";
		interrupt-parent = <&cpuacc_pulse_aggr_0>;
		interrupts =
			<CPUACC_GIA_PULSE_AGGR_0_AUX_GIC_TOP_GSPAN_AXI_STREAM_INITIATOR_ICD_ERR_DSCGT>,
			<CPUACC_GIA_PULSE_AGGR_0_AUX_GIC_TOP_GSPAN_AXI_INITIATOR_GIC_ICD_ERR_DSCGT>,
			<CPUACC_GIA_PULSE_AGGR_0_AUX_GSPAN_AXI_INITIATOR_DMA_ICD_ERR_DSCGT>,
			<CPUACC_GIA_PULSE_AGGR_0_AUX_GSPAN_ATB_INITIATOR_ICD_ERR_DSCGT>,
			<CPUACC_GIA_PULSE_AGGR_0_AUX_GPDMA_TBU_SS_TBU_WRAPPER_TBU_RAS_FHI>,
			<CPUACC_GIA_PULSE_AGGR_0_AUX_GPDMA_TBU_SS_TBU_WRAPPER_TBU_RAS_ERI>,
			<CPUACC_GIA_PULSE_AGGR_0_AUX_GPDMA_TBU_SS_TBU_WRAPPER_TBU_RAS_CRI>,
			<CPUACC_GIA_PULSE_AGGR_0_AUX_GPDMA_TBU_SS_TBU_WRAPPER_TBU_PMU_IRPT>,
			<CPUACC_GIA_PULSE_AGGR_0_AUX_GIC_TOP_GIC700_ERR_INT>,
			<CPUACC_GIA_PULSE_AGGR_0_AUX_GIC_TOP_GIC700_FAULT_INT>,
			<CPUACC_GIA_PULSE_AGGR_0_AUX_GIC_TOP_GIC700_PMU_INT>,
			<31>;
		interrupt-names =
			"CPUACC_GIA_PULSE_AGGR_0_AUX_GIC_TOP_GSPAN_AXI_STREAM_INITIATOR_ICD_ERR_DSCGT",
			"CPUACC_GIA_PULSE_AGGR_0_AUX_GIC_TOP_GSPAN_AXI_INITIATOR_GIC_ICD_ERR_DSCGT",
			"CPUACC_GIA_PULSE_AGGR_0_AUX_GSPAN_AXI_INITIATOR_DMA_ICD_ERR_DSCGT",
			"CPUACC_GIA_PULSE_AGGR_0_AUX_GSPAN_ATB_INITIATOR_ICD_ERR_DSCGT",
			"CPUACC_GIA_PULSE_AGGR_0_AUX_GPDMA_TBU_SS_TBU_WRAPPER_TBU_RAS_FHI",
			"CPUACC_GIA_PULSE_AGGR_0_AUX_GPDMA_TBU_SS_TBU_WRAPPER_TBU_RAS_ERI",
			"CPUACC_GIA_PULSE_AGGR_0_AUX_GPDMA_TBU_SS_TBU_WRAPPER_TBU_RAS_CRI",
			"CPUACC_GIA_PULSE_AGGR_0_AUX_GPDMA_TBU_SS_TBU_WRAPPER_TBU_PMU_IRPT",
			"CPUACC_GIA_PULSE_AGGR_0_AUX_GIC_TOP_GIC700_ERR_INT",
			"CPUACC_GIA_PULSE_AGGR_0_AUX_GIC_TOP_GIC700_FAULT_INT",
			"CPUACC_GIA_PULSE_AGGR_0_AUX_GIC_TOP_GIC700_PMU_INT",
			"TEST_LINE_31";
	};

	cpuacc_multicast_aggr_6_test: cpuacc_multicast_aggr_6_test {
		compatible = "google,gia-test";
		interrupt-parent = <&cpuacc_multicast_aggr_6>;
		interrupts =
			<CPUACC_GIA_MULTICAST_AGGR_6_AUX_AON_LPCM_XFW_PWRAP_NS_INTR>,
			<CPUACC_GIA_MULTICAST_AGGR_6_AUX_NIC_XFW_AWRAP_NS_INTR>,
			<CPUACC_GIA_MULTICAST_AGGR_6_AUX_SSU_XFW_AWRAP_NS_INTR>,
			<CPUACC_GIA_MULTICAST_AGGR_6_AUX_GIC_TOP_GIC_GEM_TOP_IRQ>,
			<CPUACC_GIA_MULTICAST_AGGR_6_AUX_GPDMA_TBU_SS_GPDMA_GEM_TOP_IRQ>,
			<CPUACC_GIA_MULTICAST_AGGR_6_AUX_GPDMA_TBU_SS_RA_TOP_NS_INTR>,
			<CPUACC_GIA_MULTICAST_AGGR_6_AUX_GPDMA_TBU_SS_TBU_WRAPPER_MFW_NS_IRQ>,
			<CPUACC_GIA_MULTICAST_AGGR_6_AUX_CONTROL_PLANE_FABRIC_XBA00_ERR_IRQ>,
			<CPUACC_GIA_MULTICAST_AGGR_6_AUX_GPDMA_TOP_GPDMA0_IRQ_ABORT>,
			<CPUACC_GIA_MULTICAST_AGGR_6_AUX_GPDMA_TOP_GPDMA1_IRQ_ABORT>,
			<CPUACC_GIA_MULTICAST_AGGR_6_AUX_GPDMA_TOP_GPDMA2_IRQ_ABORT>,
			<CPUACC_GIA_MULTICAST_AGGR_6_AUX_GPDMA_TOP_GPDMA3_IRQ_ABORT>,
			<CPUACC_GIA_MULTICAST_AGGR_6_AUX_GPDMA_TOP_GPDMA4_IRQ_ABORT>,
			<31>;
		interrupt-names =
			"CPUACC_GIA_MULTICAST_AGGR_6_AUX_AON_LPCM_XFW_PWRAP_NS_INTR",
			"CPUACC_GIA_MULTICAST_AGGR_6_AUX_NIC_XFW_AWRAP_NS_INTR",
			"CPUACC_GIA_MULTICAST_AGGR_6_AUX_SSU_XFW_AWRAP_NS_INTR",
			"CPUACC_GIA_MULTICAST_AGGR_6_AUX_GIC_TOP_GIC_GEM_TOP_IRQ",
			"CPUACC_GIA_MULTICAST_AGGR_6_AUX_GPDMA_TBU_SS_GPDMA_GEM_TOP_IRQ",
			"CPUACC_GIA_MULTICAST_AGGR_6_AUX_GPDMA_TBU_SS_RA_TOP_NS_INTR",
			"CPUACC_GIA_MULTICAST_AGGR_6_AUX_GPDMA_TBU_SS_TBU_WRAPPER_MFW_NS_IRQ",
			"CPUACC_GIA_MULTICAST_AGGR_6_AUX_CONTROL_PLANE_FABRIC_XBA00_ERR_IRQ",
			"CPUACC_GIA_MULTICAST_AGGR_6_AUX_GPDMA_TOP_GPDMA0_IRQ_ABORT",
			"CPUACC_GIA_MULTICAST_AGGR_6_AUX_GPDMA_TOP_GPDMA1_IRQ_ABORT",
			"CPUACC_GIA_MULTICAST_AGGR_6_AUX_GPDMA_TOP_GPDMA2_IRQ_ABORT",
			"CPUACC_GIA_MULTICAST_AGGR_6_AUX_GPDMA_TOP_GPDMA3_IRQ_ABORT",
			"CPUACC_GIA_MULTICAST_AGGR_6_AUX_GPDMA_TOP_GPDMA4_IRQ_ABORT",
			"TEST_LINE_31";
	};

	cpuacc_multicast_aggr_16_test: cpuacc_multicast_aggr_16_test {
		compatible = "google,gia-test";
		interrupt-parent = <&cpuacc_multicast_aggr_16>;
		interrupts =
			<CPUACC_GIA_MULTICAST_AGGR_16_AUX_GPDMA_TOP_GPDMA0_IRQ_0>,
			<CPUACC_GIA_MULTICAST_AGGR_16_AUX_GPDMA_TOP_GPDMA0_IRQ_1>,
			<CPUACC_GIA_MULTICAST_AGGR_16_AUX_GPDMA_TOP_GPDMA0_IRQ_2>,
			<CPUACC_GIA_MULTICAST_AGGR_16_AUX_GPDMA_TOP_GPDMA0_IRQ_3>,
			<CPUACC_GIA_MULTICAST_AGGR_16_AUX_GPDMA_TOP_GPDMA0_IRQ_4>,
			<CPUACC_GIA_MULTICAST_AGGR_16_AUX_GPDMA_TOP_GPDMA0_IRQ_5>,
			<CPUACC_GIA_MULTICAST_AGGR_16_AUX_GPDMA_TOP_GPDMA0_IRQ_6>,
			<CPUACC_GIA_MULTICAST_AGGR_16_AUX_GPDMA_TOP_GPDMA0_IRQ_7>,
			<CPUACC_GIA_MULTICAST_AGGR_16_AUX_GPDMA_TOP_GPDMA0_IRQ_8>,
			<CPUACC_GIA_MULTICAST_AGGR_16_AUX_GPDMA_TOP_GPDMA0_IRQ_9>,
			<CPUACC_GIA_MULTICAST_AGGR_16_AUX_GPDMA_TOP_GPDMA0_IRQ_10>,
			<CPUACC_GIA_MULTICAST_AGGR_16_AUX_GPDMA_TOP_GPDMA0_IRQ_11>,
			<CPUACC_GIA_MULTICAST_AGGR_16_AUX_GPDMA_TOP_GPDMA0_IRQ_12>,
			<CPUACC_GIA_MULTICAST_AGGR_16_AUX_GPDMA_TOP_GPDMA0_IRQ_13>,
			<CPUACC_GIA_MULTICAST_AGGR_16_AUX_GPDMA_TOP_GPDMA0_IRQ_14>,
			<CPUACC_GIA_MULTICAST_AGGR_16_AUX_GPDMA_TOP_GPDMA0_IRQ_15>,
			<CPUACC_GIA_MULTICAST_AGGR_16_AUX_GPDMA_TOP_GPDMA0_IRQ_16>,
			<CPUACC_GIA_MULTICAST_AGGR_16_AUX_GPDMA_TOP_GPDMA0_IRQ_17>,
			<CPUACC_GIA_MULTICAST_AGGR_16_AUX_GPDMA_TOP_GPDMA0_IRQ_18>,
			<CPUACC_GIA_MULTICAST_AGGR_16_AUX_GPDMA_TOP_GPDMA0_IRQ_19>,
			<CPUACC_GIA_MULTICAST_AGGR_16_AUX_GPDMA_TOP_GPDMA0_IRQ_20>,
			<CPUACC_GIA_MULTICAST_AGGR_16_AUX_GPDMA_TOP_GPDMA0_IRQ_21>,
			<CPUACC_GIA_MULTICAST_AGGR_16_AUX_GPDMA_TOP_GPDMA0_IRQ_22>,
			<CPUACC_GIA_MULTICAST_AGGR_16_AUX_GPDMA_TOP_GPDMA0_IRQ_23>,
			<CPUACC_GIA_MULTICAST_AGGR_16_AUX_GPDMA_TOP_GPDMA0_IRQ_24>,
			<CPUACC_GIA_MULTICAST_AGGR_16_AUX_GPDMA_TOP_GPDMA0_IRQ_25>,
			<CPUACC_GIA_MULTICAST_AGGR_16_AUX_GPDMA_TOP_GPDMA0_IRQ_26>,
			<CPUACC_GIA_MULTICAST_AGGR_16_AUX_GPDMA_TOP_GPDMA0_IRQ_27>,
			<CPUACC_GIA_MULTICAST_AGGR_16_AUX_GPDMA_TOP_GPDMA0_IRQ_28>,
			<CPUACC_GIA_MULTICAST_AGGR_16_AUX_GPDMA_TOP_GPDMA0_IRQ_29>,
			<CPUACC_GIA_MULTICAST_AGGR_16_AUX_GPDMA_TOP_GPDMA0_IRQ_30>,
			<CPUACC_GIA_MULTICAST_AGGR_16_AUX_GPDMA_TOP_GPDMA0_IRQ_31>;
		interrupt-names =
			"CPUACC_GIA_MULTICAST_AGGR_16_AUX_GPDMA_TOP_GPDMA0_IRQ_0",
			"CPUACC_GIA_MULTICAST_AGGR_16_AUX_GPDMA_TOP_GPDMA0_IRQ_1",
			"CPUACC_GIA_MULTICAST_AGGR_16_AUX_GPDMA_TOP_GPDMA0_IRQ_2",
			"CPUACC_GIA_MULTICAST_AGGR_16_AUX_GPDMA_TOP_GPDMA0_IRQ_3",
			"CPUACC_GIA_MULTICAST_AGGR_16_AUX_GPDMA_TOP_GPDMA0_IRQ_4",
			"CPUACC_GIA_MULTICAST_AGGR_16_AUX_GPDMA_TOP_GPDMA0_IRQ_5",
			"CPUACC_GIA_MULTICAST_AGGR_16_AUX_GPDMA_TOP_GPDMA0_IRQ_6",
			"CPUACC_GIA_MULTICAST_AGGR_16_AUX_GPDMA_TOP_GPDMA0_IRQ_7",
			"CPUACC_GIA_MULTICAST_AGGR_16_AUX_GPDMA_TOP_GPDMA0_IRQ_8",
			"CPUACC_GIA_MULTICAST_AGGR_16_AUX_GPDMA_TOP_GPDMA0_IRQ_9",
			"CPUACC_GIA_MULTICAST_AGGR_16_AUX_GPDMA_TOP_GPDMA0_IRQ_10",
			"CPUACC_GIA_MULTICAST_AGGR_16_AUX_GPDMA_TOP_GPDMA0_IRQ_11",
			"CPUACC_GIA_MULTICAST_AGGR_16_AUX_GPDMA_TOP_GPDMA0_IRQ_12",
			"CPUACC_GIA_MULTICAST_AGGR_16_AUX_GPDMA_TOP_GPDMA0_IRQ_13",
			"CPUACC_GIA_MULTICAST_AGGR_16_AUX_GPDMA_TOP_GPDMA0_IRQ_14",
			"CPUACC_GIA_MULTICAST_AGGR_16_AUX_GPDMA_TOP_GPDMA0_IRQ_15",
			"CPUACC_GIA_MULTICAST_AGGR_16_AUX_GPDMA_TOP_GPDMA0_IRQ_16",
			"CPUACC_GIA_MULTICAST_AGGR_16_AUX_GPDMA_TOP_GPDMA0_IRQ_17",
			"CPUACC_GIA_MULTICAST_AGGR_16_AUX_GPDMA_TOP_GPDMA0_IRQ_18",
			"CPUACC_GIA_MULTICAST_AGGR_16_AUX_GPDMA_TOP_GPDMA0_IRQ_19",
			"CPUACC_GIA_MULTICAST_AGGR_16_AUX_GPDMA_TOP_GPDMA0_IRQ_20",
			"CPUACC_GIA_MULTICAST_AGGR_16_AUX_GPDMA_TOP_GPDMA0_IRQ_21",
			"CPUACC_GIA_MULTICAST_AGGR_16_AUX_GPDMA_TOP_GPDMA0_IRQ_22",
			"CPUACC_GIA_MULTICAST_AGGR_16_AUX_GPDMA_TOP_GPDMA0_IRQ_23",
			"CPUACC_GIA_MULTICAST_AGGR_16_AUX_GPDMA_TOP_GPDMA0_IRQ_24",
			"CPUACC_GIA_MULTICAST_AGGR_16_AUX_GPDMA_TOP_GPDMA0_IRQ_25",
			"CPUACC_GIA_MULTICAST_AGGR_16_AUX_GPDMA_TOP_GPDMA0_IRQ_26",
			"CPUACC_GIA_MULTICAST_AGGR_16_AUX_GPDMA_TOP_GPDMA0_IRQ_27",
			"CPUACC_GIA_MULTICAST_AGGR_16_AUX_GPDMA_TOP_GPDMA0_IRQ_28",
			"CPUACC_GIA_MULTICAST_AGGR_16_AUX_GPDMA_TOP_GPDMA0_IRQ_29",
			"CPUACC_GIA_MULTICAST_AGGR_16_AUX_GPDMA_TOP_GPDMA0_IRQ_30",
			"CPUACC_GIA_MULTICAST_AGGR_16_AUX_GPDMA_TOP_GPDMA0_IRQ_31";
	};

	cpuacc_multicast_aggr_17_test: cpuacc_multicast_aggr_17_test {
		compatible = "google,gia-test";
		interrupt-parent = <&cpuacc_multicast_aggr_17>;
		interrupts =
			<CPUACC_GIA_MULTICAST_AGGR_17_AUX_GPDMA_TOP_GPDMA1_IRQ_0>,
			<CPUACC_GIA_MULTICAST_AGGR_17_AUX_GPDMA_TOP_GPDMA1_IRQ_1>,
			<CPUACC_GIA_MULTICAST_AGGR_17_AUX_GPDMA_TOP_GPDMA1_IRQ_2>,
			<CPUACC_GIA_MULTICAST_AGGR_17_AUX_GPDMA_TOP_GPDMA1_IRQ_3>,
			<CPUACC_GIA_MULTICAST_AGGR_17_AUX_GPDMA_TOP_GPDMA1_IRQ_4>,
			<CPUACC_GIA_MULTICAST_AGGR_17_AUX_GPDMA_TOP_GPDMA1_IRQ_5>,
			<CPUACC_GIA_MULTICAST_AGGR_17_AUX_GPDMA_TOP_GPDMA1_IRQ_6>,
			<CPUACC_GIA_MULTICAST_AGGR_17_AUX_GPDMA_TOP_GPDMA1_IRQ_7>,
			<CPUACC_GIA_MULTICAST_AGGR_17_AUX_GPDMA_TOP_GPDMA1_IRQ_8>,
			<CPUACC_GIA_MULTICAST_AGGR_17_AUX_GPDMA_TOP_GPDMA1_IRQ_9>,
			<CPUACC_GIA_MULTICAST_AGGR_17_AUX_GPDMA_TOP_GPDMA1_IRQ_10>,
			<CPUACC_GIA_MULTICAST_AGGR_17_AUX_GPDMA_TOP_GPDMA1_IRQ_11>,
			<CPUACC_GIA_MULTICAST_AGGR_17_AUX_GPDMA_TOP_GPDMA1_IRQ_12>,
			<CPUACC_GIA_MULTICAST_AGGR_17_AUX_GPDMA_TOP_GPDMA1_IRQ_13>,
			<CPUACC_GIA_MULTICAST_AGGR_17_AUX_GPDMA_TOP_GPDMA1_IRQ_14>,
			<CPUACC_GIA_MULTICAST_AGGR_17_AUX_GPDMA_TOP_GPDMA1_IRQ_15>,
			<CPUACC_GIA_MULTICAST_AGGR_17_AUX_GPDMA_TOP_GPDMA1_IRQ_16>,
			<CPUACC_GIA_MULTICAST_AGGR_17_AUX_GPDMA_TOP_GPDMA1_IRQ_17>,
			<CPUACC_GIA_MULTICAST_AGGR_17_AUX_GPDMA_TOP_GPDMA1_IRQ_18>,
			<CPUACC_GIA_MULTICAST_AGGR_17_AUX_GPDMA_TOP_GPDMA1_IRQ_19>,
			<CPUACC_GIA_MULTICAST_AGGR_17_AUX_GPDMA_TOP_GPDMA1_IRQ_20>,
			<CPUACC_GIA_MULTICAST_AGGR_17_AUX_GPDMA_TOP_GPDMA1_IRQ_21>,
			<CPUACC_GIA_MULTICAST_AGGR_17_AUX_GPDMA_TOP_GPDMA1_IRQ_22>,
			<CPUACC_GIA_MULTICAST_AGGR_17_AUX_GPDMA_TOP_GPDMA1_IRQ_23>,
			<CPUACC_GIA_MULTICAST_AGGR_17_AUX_GPDMA_TOP_GPDMA1_IRQ_24>,
			<CPUACC_GIA_MULTICAST_AGGR_17_AUX_GPDMA_TOP_GPDMA1_IRQ_25>,
			<CPUACC_GIA_MULTICAST_AGGR_17_AUX_GPDMA_TOP_GPDMA1_IRQ_26>,
			<CPUACC_GIA_MULTICAST_AGGR_17_AUX_GPDMA_TOP_GPDMA1_IRQ_27>,
			<CPUACC_GIA_MULTICAST_AGGR_17_AUX_GPDMA_TOP_GPDMA1_IRQ_28>,
			<CPUACC_GIA_MULTICAST_AGGR_17_AUX_GPDMA_TOP_GPDMA1_IRQ_29>,
			<CPUACC_GIA_MULTICAST_AGGR_17_AUX_GPDMA_TOP_GPDMA1_IRQ_30>,
			<CPUACC_GIA_MULTICAST_AGGR_17_AUX_GPDMA_TOP_GPDMA1_IRQ_31>;
		interrupt-names =
			"CPUACC_GIA_MULTICAST_AGGR_17_AUX_GPDMA_TOP_GPDMA1_IRQ_0",
			"CPUACC_GIA_MULTICAST_AGGR_17_AUX_GPDMA_TOP_GPDMA1_IRQ_1",
			"CPUACC_GIA_MULTICAST_AGGR_17_AUX_GPDMA_TOP_GPDMA1_IRQ_2",
			"CPUACC_GIA_MULTICAST_AGGR_17_AUX_GPDMA_TOP_GPDMA1_IRQ_3",
			"CPUACC_GIA_MULTICAST_AGGR_17_AUX_GPDMA_TOP_GPDMA1_IRQ_4",
			"CPUACC_GIA_MULTICAST_AGGR_17_AUX_GPDMA_TOP_GPDMA1_IRQ_5",
			"CPUACC_GIA_MULTICAST_AGGR_17_AUX_GPDMA_TOP_GPDMA1_IRQ_6",
			"CPUACC_GIA_MULTICAST_AGGR_17_AUX_GPDMA_TOP_GPDMA1_IRQ_7",
			"CPUACC_GIA_MULTICAST_AGGR_17_AUX_GPDMA_TOP_GPDMA1_IRQ_8",
			"CPUACC_GIA_MULTICAST_AGGR_17_AUX_GPDMA_TOP_GPDMA1_IRQ_9",
			"CPUACC_GIA_MULTICAST_AGGR_17_AUX_GPDMA_TOP_GPDMA1_IRQ_10",
			"CPUACC_GIA_MULTICAST_AGGR_17_AUX_GPDMA_TOP_GPDMA1_IRQ_11",
			"CPUACC_GIA_MULTICAST_AGGR_17_AUX_GPDMA_TOP_GPDMA1_IRQ_12",
			"CPUACC_GIA_MULTICAST_AGGR_17_AUX_GPDMA_TOP_GPDMA1_IRQ_13",
			"CPUACC_GIA_MULTICAST_AGGR_17_AUX_GPDMA_TOP_GPDMA1_IRQ_14",
			"CPUACC_GIA_MULTICAST_AGGR_17_AUX_GPDMA_TOP_GPDMA1_IRQ_15",
			"CPUACC_GIA_MULTICAST_AGGR_17_AUX_GPDMA_TOP_GPDMA1_IRQ_16",
			"CPUACC_GIA_MULTICAST_AGGR_17_AUX_GPDMA_TOP_GPDMA1_IRQ_17",
			"CPUACC_GIA_MULTICAST_AGGR_17_AUX_GPDMA_TOP_GPDMA1_IRQ_18",
			"CPUACC_GIA_MULTICAST_AGGR_17_AUX_GPDMA_TOP_GPDMA1_IRQ_19",
			"CPUACC_GIA_MULTICAST_AGGR_17_AUX_GPDMA_TOP_GPDMA1_IRQ_20",
			"CPUACC_GIA_MULTICAST_AGGR_17_AUX_GPDMA_TOP_GPDMA1_IRQ_21",
			"CPUACC_GIA_MULTICAST_AGGR_17_AUX_GPDMA_TOP_GPDMA1_IRQ_22",
			"CPUACC_GIA_MULTICAST_AGGR_17_AUX_GPDMA_TOP_GPDMA1_IRQ_23",
			"CPUACC_GIA_MULTICAST_AGGR_17_AUX_GPDMA_TOP_GPDMA1_IRQ_24",
			"CPUACC_GIA_MULTICAST_AGGR_17_AUX_GPDMA_TOP_GPDMA1_IRQ_25",
			"CPUACC_GIA_MULTICAST_AGGR_17_AUX_GPDMA_TOP_GPDMA1_IRQ_26",
			"CPUACC_GIA_MULTICAST_AGGR_17_AUX_GPDMA_TOP_GPDMA1_IRQ_27",
			"CPUACC_GIA_MULTICAST_AGGR_17_AUX_GPDMA_TOP_GPDMA1_IRQ_28",
			"CPUACC_GIA_MULTICAST_AGGR_17_AUX_GPDMA_TOP_GPDMA1_IRQ_29",
			"CPUACC_GIA_MULTICAST_AGGR_17_AUX_GPDMA_TOP_GPDMA1_IRQ_30",
			"CPUACC_GIA_MULTICAST_AGGR_17_AUX_GPDMA_TOP_GPDMA1_IRQ_31";
	};

	cpuacc_multicast_aggr_18_test: cpuacc_multicast_aggr_18_test {
		compatible = "google,gia-test";
		interrupt-parent = <&cpuacc_multicast_aggr_18>;
		interrupts =
			<CPUACC_GIA_MULTICAST_AGGR_18_AUX_GPDMA_TOP_GPDMA2_IRQ_0>,
			<CPUACC_GIA_MULTICAST_AGGR_18_AUX_GPDMA_TOP_GPDMA2_IRQ_1>,
			<CPUACC_GIA_MULTICAST_AGGR_18_AUX_GPDMA_TOP_GPDMA2_IRQ_2>,
			<CPUACC_GIA_MULTICAST_AGGR_18_AUX_GPDMA_TOP_GPDMA2_IRQ_3>,
			<CPUACC_GIA_MULTICAST_AGGR_18_AUX_GPDMA_TOP_GPDMA2_IRQ_4>,
			<CPUACC_GIA_MULTICAST_AGGR_18_AUX_GPDMA_TOP_GPDMA2_IRQ_5>,
			<CPUACC_GIA_MULTICAST_AGGR_18_AUX_GPDMA_TOP_GPDMA2_IRQ_6>,
			<CPUACC_GIA_MULTICAST_AGGR_18_AUX_GPDMA_TOP_GPDMA2_IRQ_7>,
			<CPUACC_GIA_MULTICAST_AGGR_18_AUX_GPDMA_TOP_GPDMA2_IRQ_8>,
			<CPUACC_GIA_MULTICAST_AGGR_18_AUX_GPDMA_TOP_GPDMA2_IRQ_9>,
			<CPUACC_GIA_MULTICAST_AGGR_18_AUX_GPDMA_TOP_GPDMA2_IRQ_10>,
			<CPUACC_GIA_MULTICAST_AGGR_18_AUX_GPDMA_TOP_GPDMA2_IRQ_11>,
			<CPUACC_GIA_MULTICAST_AGGR_18_AUX_GPDMA_TOP_GPDMA2_IRQ_12>,
			<CPUACC_GIA_MULTICAST_AGGR_18_AUX_GPDMA_TOP_GPDMA2_IRQ_13>,
			<CPUACC_GIA_MULTICAST_AGGR_18_AUX_GPDMA_TOP_GPDMA2_IRQ_14>,
			<CPUACC_GIA_MULTICAST_AGGR_18_AUX_GPDMA_TOP_GPDMA2_IRQ_15>,
			<CPUACC_GIA_MULTICAST_AGGR_18_AUX_GPDMA_TOP_GPDMA2_IRQ_16>,
			<CPUACC_GIA_MULTICAST_AGGR_18_AUX_GPDMA_TOP_GPDMA2_IRQ_17>,
			<CPUACC_GIA_MULTICAST_AGGR_18_AUX_GPDMA_TOP_GPDMA2_IRQ_18>,
			<CPUACC_GIA_MULTICAST_AGGR_18_AUX_GPDMA_TOP_GPDMA2_IRQ_19>,
			<CPUACC_GIA_MULTICAST_AGGR_18_AUX_GPDMA_TOP_GPDMA2_IRQ_20>,
			<CPUACC_GIA_MULTICAST_AGGR_18_AUX_GPDMA_TOP_GPDMA2_IRQ_21>,
			<CPUACC_GIA_MULTICAST_AGGR_18_AUX_GPDMA_TOP_GPDMA2_IRQ_22>,
			<CPUACC_GIA_MULTICAST_AGGR_18_AUX_GPDMA_TOP_GPDMA2_IRQ_23>,
			<CPUACC_GIA_MULTICAST_AGGR_18_AUX_GPDMA_TOP_GPDMA2_IRQ_24>,
			<CPUACC_GIA_MULTICAST_AGGR_18_AUX_GPDMA_TOP_GPDMA2_IRQ_25>,
			<CPUACC_GIA_MULTICAST_AGGR_18_AUX_GPDMA_TOP_GPDMA2_IRQ_26>,
			<CPUACC_GIA_MULTICAST_AGGR_18_AUX_GPDMA_TOP_GPDMA2_IRQ_27>,
			<CPUACC_GIA_MULTICAST_AGGR_18_AUX_GPDMA_TOP_GPDMA2_IRQ_28>,
			<CPUACC_GIA_MULTICAST_AGGR_18_AUX_GPDMA_TOP_GPDMA2_IRQ_29>,
			<CPUACC_GIA_MULTICAST_AGGR_18_AUX_GPDMA_TOP_GPDMA2_IRQ_30>,
			<CPUACC_GIA_MULTICAST_AGGR_18_AUX_GPDMA_TOP_GPDMA2_IRQ_31>;
		interrupt-names =
			"CPUACC_GIA_MULTICAST_AGGR_18_AUX_GPDMA_TOP_GPDMA2_IRQ_0",
			"CPUACC_GIA_MULTICAST_AGGR_18_AUX_GPDMA_TOP_GPDMA2_IRQ_1",
			"CPUACC_GIA_MULTICAST_AGGR_18_AUX_GPDMA_TOP_GPDMA2_IRQ_2",
			"CPUACC_GIA_MULTICAST_AGGR_18_AUX_GPDMA_TOP_GPDMA2_IRQ_3",
			"CPUACC_GIA_MULTICAST_AGGR_18_AUX_GPDMA_TOP_GPDMA2_IRQ_4",
			"CPUACC_GIA_MULTICAST_AGGR_18_AUX_GPDMA_TOP_GPDMA2_IRQ_5",
			"CPUACC_GIA_MULTICAST_AGGR_18_AUX_GPDMA_TOP_GPDMA2_IRQ_6",
			"CPUACC_GIA_MULTICAST_AGGR_18_AUX_GPDMA_TOP_GPDMA2_IRQ_7",
			"CPUACC_GIA_MULTICAST_AGGR_18_AUX_GPDMA_TOP_GPDMA2_IRQ_8",
			"CPUACC_GIA_MULTICAST_AGGR_18_AUX_GPDMA_TOP_GPDMA2_IRQ_9",
			"CPUACC_GIA_MULTICAST_AGGR_18_AUX_GPDMA_TOP_GPDMA2_IRQ_10",
			"CPUACC_GIA_MULTICAST_AGGR_18_AUX_GPDMA_TOP_GPDMA2_IRQ_11",
			"CPUACC_GIA_MULTICAST_AGGR_18_AUX_GPDMA_TOP_GPDMA2_IRQ_12",
			"CPUACC_GIA_MULTICAST_AGGR_18_AUX_GPDMA_TOP_GPDMA2_IRQ_13",
			"CPUACC_GIA_MULTICAST_AGGR_18_AUX_GPDMA_TOP_GPDMA2_IRQ_14",
			"CPUACC_GIA_MULTICAST_AGGR_18_AUX_GPDMA_TOP_GPDMA2_IRQ_15",
			"CPUACC_GIA_MULTICAST_AGGR_18_AUX_GPDMA_TOP_GPDMA2_IRQ_16",
			"CPUACC_GIA_MULTICAST_AGGR_18_AUX_GPDMA_TOP_GPDMA2_IRQ_17",
			"CPUACC_GIA_MULTICAST_AGGR_18_AUX_GPDMA_TOP_GPDMA2_IRQ_18",
			"CPUACC_GIA_MULTICAST_AGGR_18_AUX_GPDMA_TOP_GPDMA2_IRQ_19",
			"CPUACC_GIA_MULTICAST_AGGR_18_AUX_GPDMA_TOP_GPDMA2_IRQ_20",
			"CPUACC_GIA_MULTICAST_AGGR_18_AUX_GPDMA_TOP_GPDMA2_IRQ_21",
			"CPUACC_GIA_MULTICAST_AGGR_18_AUX_GPDMA_TOP_GPDMA2_IRQ_22",
			"CPUACC_GIA_MULTICAST_AGGR_18_AUX_GPDMA_TOP_GPDMA2_IRQ_23",
			"CPUACC_GIA_MULTICAST_AGGR_18_AUX_GPDMA_TOP_GPDMA2_IRQ_24",
			"CPUACC_GIA_MULTICAST_AGGR_18_AUX_GPDMA_TOP_GPDMA2_IRQ_25",
			"CPUACC_GIA_MULTICAST_AGGR_18_AUX_GPDMA_TOP_GPDMA2_IRQ_26",
			"CPUACC_GIA_MULTICAST_AGGR_18_AUX_GPDMA_TOP_GPDMA2_IRQ_27",
			"CPUACC_GIA_MULTICAST_AGGR_18_AUX_GPDMA_TOP_GPDMA2_IRQ_28",
			"CPUACC_GIA_MULTICAST_AGGR_18_AUX_GPDMA_TOP_GPDMA2_IRQ_29",
			"CPUACC_GIA_MULTICAST_AGGR_18_AUX_GPDMA_TOP_GPDMA2_IRQ_30",
			"CPUACC_GIA_MULTICAST_AGGR_18_AUX_GPDMA_TOP_GPDMA2_IRQ_31";
	};

	cpuacc_multicast_aggr_19_test: cpuacc_multicast_aggr_19_test {
		compatible = "google,gia-test";
		interrupt-parent = <&cpuacc_multicast_aggr_19>;
		interrupts =
			<CPUACC_GIA_MULTICAST_AGGR_19_AUX_GPDMA_TOP_GPDMA3_IRQ_0>,
			<CPUACC_GIA_MULTICAST_AGGR_19_AUX_GPDMA_TOP_GPDMA3_IRQ_1>,
			<CPUACC_GIA_MULTICAST_AGGR_19_AUX_GPDMA_TOP_GPDMA3_IRQ_2>,
			<CPUACC_GIA_MULTICAST_AGGR_19_AUX_GPDMA_TOP_GPDMA3_IRQ_3>,
			<CPUACC_GIA_MULTICAST_AGGR_19_AUX_GPDMA_TOP_GPDMA3_IRQ_4>,
			<CPUACC_GIA_MULTICAST_AGGR_19_AUX_GPDMA_TOP_GPDMA3_IRQ_5>,
			<CPUACC_GIA_MULTICAST_AGGR_19_AUX_GPDMA_TOP_GPDMA3_IRQ_6>,
			<CPUACC_GIA_MULTICAST_AGGR_19_AUX_GPDMA_TOP_GPDMA3_IRQ_7>,
			<CPUACC_GIA_MULTICAST_AGGR_19_AUX_GPDMA_TOP_GPDMA3_IRQ_8>,
			<CPUACC_GIA_MULTICAST_AGGR_19_AUX_GPDMA_TOP_GPDMA3_IRQ_9>,
			<CPUACC_GIA_MULTICAST_AGGR_19_AUX_GPDMA_TOP_GPDMA3_IRQ_10>,
			<CPUACC_GIA_MULTICAST_AGGR_19_AUX_GPDMA_TOP_GPDMA3_IRQ_11>,
			<CPUACC_GIA_MULTICAST_AGGR_19_AUX_GPDMA_TOP_GPDMA3_IRQ_12>,
			<CPUACC_GIA_MULTICAST_AGGR_19_AUX_GPDMA_TOP_GPDMA3_IRQ_13>,
			<CPUACC_GIA_MULTICAST_AGGR_19_AUX_GPDMA_TOP_GPDMA3_IRQ_14>,
			<CPUACC_GIA_MULTICAST_AGGR_19_AUX_GPDMA_TOP_GPDMA3_IRQ_15>,
			<CPUACC_GIA_MULTICAST_AGGR_19_AUX_GPDMA_TOP_GPDMA3_IRQ_16>,
			<CPUACC_GIA_MULTICAST_AGGR_19_AUX_GPDMA_TOP_GPDMA3_IRQ_17>,
			<CPUACC_GIA_MULTICAST_AGGR_19_AUX_GPDMA_TOP_GPDMA3_IRQ_18>,
			<CPUACC_GIA_MULTICAST_AGGR_19_AUX_GPDMA_TOP_GPDMA3_IRQ_19>,
			<CPUACC_GIA_MULTICAST_AGGR_19_AUX_GPDMA_TOP_GPDMA3_IRQ_20>,
			<CPUACC_GIA_MULTICAST_AGGR_19_AUX_GPDMA_TOP_GPDMA3_IRQ_21>,
			<CPUACC_GIA_MULTICAST_AGGR_19_AUX_GPDMA_TOP_GPDMA3_IRQ_22>,
			<CPUACC_GIA_MULTICAST_AGGR_19_AUX_GPDMA_TOP_GPDMA3_IRQ_23>,
			<CPUACC_GIA_MULTICAST_AGGR_19_AUX_GPDMA_TOP_GPDMA3_IRQ_24>,
			<CPUACC_GIA_MULTICAST_AGGR_19_AUX_GPDMA_TOP_GPDMA3_IRQ_25>,
			<CPUACC_GIA_MULTICAST_AGGR_19_AUX_GPDMA_TOP_GPDMA3_IRQ_26>,
			<CPUACC_GIA_MULTICAST_AGGR_19_AUX_GPDMA_TOP_GPDMA3_IRQ_27>,
			<CPUACC_GIA_MULTICAST_AGGR_19_AUX_GPDMA_TOP_GPDMA3_IRQ_28>,
			<CPUACC_GIA_MULTICAST_AGGR_19_AUX_GPDMA_TOP_GPDMA3_IRQ_29>,
			<CPUACC_GIA_MULTICAST_AGGR_19_AUX_GPDMA_TOP_GPDMA3_IRQ_30>,
			<CPUACC_GIA_MULTICAST_AGGR_19_AUX_GPDMA_TOP_GPDMA3_IRQ_31>;
		interrupt-names =
			"CPUACC_GIA_MULTICAST_AGGR_19_AUX_GPDMA_TOP_GPDMA3_IRQ_0",
			"CPUACC_GIA_MULTICAST_AGGR_19_AUX_GPDMA_TOP_GPDMA3_IRQ_1",
			"CPUACC_GIA_MULTICAST_AGGR_19_AUX_GPDMA_TOP_GPDMA3_IRQ_2",
			"CPUACC_GIA_MULTICAST_AGGR_19_AUX_GPDMA_TOP_GPDMA3_IRQ_3",
			"CPUACC_GIA_MULTICAST_AGGR_19_AUX_GPDMA_TOP_GPDMA3_IRQ_4",
			"CPUACC_GIA_MULTICAST_AGGR_19_AUX_GPDMA_TOP_GPDMA3_IRQ_5",
			"CPUACC_GIA_MULTICAST_AGGR_19_AUX_GPDMA_TOP_GPDMA3_IRQ_6",
			"CPUACC_GIA_MULTICAST_AGGR_19_AUX_GPDMA_TOP_GPDMA3_IRQ_7",
			"CPUACC_GIA_MULTICAST_AGGR_19_AUX_GPDMA_TOP_GPDMA3_IRQ_8",
			"CPUACC_GIA_MULTICAST_AGGR_19_AUX_GPDMA_TOP_GPDMA3_IRQ_9",
			"CPUACC_GIA_MULTICAST_AGGR_19_AUX_GPDMA_TOP_GPDMA3_IRQ_10",
			"CPUACC_GIA_MULTICAST_AGGR_19_AUX_GPDMA_TOP_GPDMA3_IRQ_11",
			"CPUACC_GIA_MULTICAST_AGGR_19_AUX_GPDMA_TOP_GPDMA3_IRQ_12",
			"CPUACC_GIA_MULTICAST_AGGR_19_AUX_GPDMA_TOP_GPDMA3_IRQ_13",
			"CPUACC_GIA_MULTICAST_AGGR_19_AUX_GPDMA_TOP_GPDMA3_IRQ_14",
			"CPUACC_GIA_MULTICAST_AGGR_19_AUX_GPDMA_TOP_GPDMA3_IRQ_15",
			"CPUACC_GIA_MULTICAST_AGGR_19_AUX_GPDMA_TOP_GPDMA3_IRQ_16",
			"CPUACC_GIA_MULTICAST_AGGR_19_AUX_GPDMA_TOP_GPDMA3_IRQ_17",
			"CPUACC_GIA_MULTICAST_AGGR_19_AUX_GPDMA_TOP_GPDMA3_IRQ_18",
			"CPUACC_GIA_MULTICAST_AGGR_19_AUX_GPDMA_TOP_GPDMA3_IRQ_19",
			"CPUACC_GIA_MULTICAST_AGGR_19_AUX_GPDMA_TOP_GPDMA3_IRQ_20",
			"CPUACC_GIA_MULTICAST_AGGR_19_AUX_GPDMA_TOP_GPDMA3_IRQ_21",
			"CPUACC_GIA_MULTICAST_AGGR_19_AUX_GPDMA_TOP_GPDMA3_IRQ_22",
			"CPUACC_GIA_MULTICAST_AGGR_19_AUX_GPDMA_TOP_GPDMA3_IRQ_23",
			"CPUACC_GIA_MULTICAST_AGGR_19_AUX_GPDMA_TOP_GPDMA3_IRQ_24",
			"CPUACC_GIA_MULTICAST_AGGR_19_AUX_GPDMA_TOP_GPDMA3_IRQ_25",
			"CPUACC_GIA_MULTICAST_AGGR_19_AUX_GPDMA_TOP_GPDMA3_IRQ_26",
			"CPUACC_GIA_MULTICAST_AGGR_19_AUX_GPDMA_TOP_GPDMA3_IRQ_27",
			"CPUACC_GIA_MULTICAST_AGGR_19_AUX_GPDMA_TOP_GPDMA3_IRQ_28",
			"CPUACC_GIA_MULTICAST_AGGR_19_AUX_GPDMA_TOP_GPDMA3_IRQ_29",
			"CPUACC_GIA_MULTICAST_AGGR_19_AUX_GPDMA_TOP_GPDMA3_IRQ_30",
			"CPUACC_GIA_MULTICAST_AGGR_19_AUX_GPDMA_TOP_GPDMA3_IRQ_31";
	};

	cpuacc_multicast_aggr_20_test: cpuacc_multicast_aggr_20_test {
		compatible = "google,gia-test";
		interrupt-parent = <&cpuacc_multicast_aggr_20>;
		interrupts =
			<CPUACC_GIA_MULTICAST_AGGR_20_AUX_GPDMA_TOP_GPDMA4_IRQ_0>,
			<CPUACC_GIA_MULTICAST_AGGR_20_AUX_GPDMA_TOP_GPDMA4_IRQ_1>,
			<CPUACC_GIA_MULTICAST_AGGR_20_AUX_GPDMA_TOP_GPDMA4_IRQ_2>,
			<CPUACC_GIA_MULTICAST_AGGR_20_AUX_GPDMA_TOP_GPDMA4_IRQ_3>,
			<CPUACC_GIA_MULTICAST_AGGR_20_AUX_GPDMA_TOP_GPDMA4_IRQ_4>,
			<CPUACC_GIA_MULTICAST_AGGR_20_AUX_GPDMA_TOP_GPDMA4_IRQ_5>,
			<CPUACC_GIA_MULTICAST_AGGR_20_AUX_GPDMA_TOP_GPDMA4_IRQ_6>,
			<CPUACC_GIA_MULTICAST_AGGR_20_AUX_GPDMA_TOP_GPDMA4_IRQ_7>,
			<CPUACC_GIA_MULTICAST_AGGR_20_AUX_GPDMA_TOP_GPDMA4_IRQ_8>,
			<CPUACC_GIA_MULTICAST_AGGR_20_AUX_GPDMA_TOP_GPDMA4_IRQ_9>,
			<CPUACC_GIA_MULTICAST_AGGR_20_AUX_GPDMA_TOP_GPDMA4_IRQ_10>,
			<CPUACC_GIA_MULTICAST_AGGR_20_AUX_GPDMA_TOP_GPDMA4_IRQ_11>,
			<CPUACC_GIA_MULTICAST_AGGR_20_AUX_GPDMA_TOP_GPDMA4_IRQ_12>,
			<CPUACC_GIA_MULTICAST_AGGR_20_AUX_GPDMA_TOP_GPDMA4_IRQ_13>,
			<CPUACC_GIA_MULTICAST_AGGR_20_AUX_GPDMA_TOP_GPDMA4_IRQ_14>,
			<CPUACC_GIA_MULTICAST_AGGR_20_AUX_GPDMA_TOP_GPDMA4_IRQ_15>,
			<CPUACC_GIA_MULTICAST_AGGR_20_AUX_GPDMA_TOP_GPDMA4_IRQ_16>,
			<CPUACC_GIA_MULTICAST_AGGR_20_AUX_GPDMA_TOP_GPDMA4_IRQ_17>,
			<CPUACC_GIA_MULTICAST_AGGR_20_AUX_GPDMA_TOP_GPDMA4_IRQ_18>,
			<CPUACC_GIA_MULTICAST_AGGR_20_AUX_GPDMA_TOP_GPDMA4_IRQ_19>,
			<CPUACC_GIA_MULTICAST_AGGR_20_AUX_GPDMA_TOP_GPDMA4_IRQ_20>,
			<CPUACC_GIA_MULTICAST_AGGR_20_AUX_GPDMA_TOP_GPDMA4_IRQ_21>,
			<CPUACC_GIA_MULTICAST_AGGR_20_AUX_GPDMA_TOP_GPDMA4_IRQ_22>,
			<CPUACC_GIA_MULTICAST_AGGR_20_AUX_GPDMA_TOP_GPDMA4_IRQ_23>,
			<CPUACC_GIA_MULTICAST_AGGR_20_AUX_GPDMA_TOP_GPDMA4_IRQ_24>,
			<CPUACC_GIA_MULTICAST_AGGR_20_AUX_GPDMA_TOP_GPDMA4_IRQ_25>,
			<CPUACC_GIA_MULTICAST_AGGR_20_AUX_GPDMA_TOP_GPDMA4_IRQ_26>,
			<CPUACC_GIA_MULTICAST_AGGR_20_AUX_GPDMA_TOP_GPDMA4_IRQ_27>,
			<CPUACC_GIA_MULTICAST_AGGR_20_AUX_GPDMA_TOP_GPDMA4_IRQ_28>,
			<CPUACC_GIA_MULTICAST_AGGR_20_AUX_GPDMA_TOP_GPDMA4_IRQ_29>,
			<CPUACC_GIA_MULTICAST_AGGR_20_AUX_GPDMA_TOP_GPDMA4_IRQ_30>,
			<CPUACC_GIA_MULTICAST_AGGR_20_AUX_GPDMA_TOP_GPDMA4_IRQ_31>;
		interrupt-names =
			"CPUACC_GIA_MULTICAST_AGGR_20_AUX_GPDMA_TOP_GPDMA4_IRQ_0",
			"CPUACC_GIA_MULTICAST_AGGR_20_AUX_GPDMA_TOP_GPDMA4_IRQ_1",
			"CPUACC_GIA_MULTICAST_AGGR_20_AUX_GPDMA_TOP_GPDMA4_IRQ_2",
			"CPUACC_GIA_MULTICAST_AGGR_20_AUX_GPDMA_TOP_GPDMA4_IRQ_3",
			"CPUACC_GIA_MULTICAST_AGGR_20_AUX_GPDMA_TOP_GPDMA4_IRQ_4",
			"CPUACC_GIA_MULTICAST_AGGR_20_AUX_GPDMA_TOP_GPDMA4_IRQ_5",
			"CPUACC_GIA_MULTICAST_AGGR_20_AUX_GPDMA_TOP_GPDMA4_IRQ_6",
			"CPUACC_GIA_MULTICAST_AGGR_20_AUX_GPDMA_TOP_GPDMA4_IRQ_7",
			"CPUACC_GIA_MULTICAST_AGGR_20_AUX_GPDMA_TOP_GPDMA4_IRQ_8",
			"CPUACC_GIA_MULTICAST_AGGR_20_AUX_GPDMA_TOP_GPDMA4_IRQ_9",
			"CPUACC_GIA_MULTICAST_AGGR_20_AUX_GPDMA_TOP_GPDMA4_IRQ_10",
			"CPUACC_GIA_MULTICAST_AGGR_20_AUX_GPDMA_TOP_GPDMA4_IRQ_11",
			"CPUACC_GIA_MULTICAST_AGGR_20_AUX_GPDMA_TOP_GPDMA4_IRQ_12",
			"CPUACC_GIA_MULTICAST_AGGR_20_AUX_GPDMA_TOP_GPDMA4_IRQ_13",
			"CPUACC_GIA_MULTICAST_AGGR_20_AUX_GPDMA_TOP_GPDMA4_IRQ_14",
			"CPUACC_GIA_MULTICAST_AGGR_20_AUX_GPDMA_TOP_GPDMA4_IRQ_15",
			"CPUACC_GIA_MULTICAST_AGGR_20_AUX_GPDMA_TOP_GPDMA4_IRQ_16",
			"CPUACC_GIA_MULTICAST_AGGR_20_AUX_GPDMA_TOP_GPDMA4_IRQ_17",
			"CPUACC_GIA_MULTICAST_AGGR_20_AUX_GPDMA_TOP_GPDMA4_IRQ_18",
			"CPUACC_GIA_MULTICAST_AGGR_20_AUX_GPDMA_TOP_GPDMA4_IRQ_19",
			"CPUACC_GIA_MULTICAST_AGGR_20_AUX_GPDMA_TOP_GPDMA4_IRQ_20",
			"CPUACC_GIA_MULTICAST_AGGR_20_AUX_GPDMA_TOP_GPDMA4_IRQ_21",
			"CPUACC_GIA_MULTICAST_AGGR_20_AUX_GPDMA_TOP_GPDMA4_IRQ_22",
			"CPUACC_GIA_MULTICAST_AGGR_20_AUX_GPDMA_TOP_GPDMA4_IRQ_23",
			"CPUACC_GIA_MULTICAST_AGGR_20_AUX_GPDMA_TOP_GPDMA4_IRQ_24",
			"CPUACC_GIA_MULTICAST_AGGR_20_AUX_GPDMA_TOP_GPDMA4_IRQ_25",
			"CPUACC_GIA_MULTICAST_AGGR_20_AUX_GPDMA_TOP_GPDMA4_IRQ_26",
			"CPUACC_GIA_MULTICAST_AGGR_20_AUX_GPDMA_TOP_GPDMA4_IRQ_27",
			"CPUACC_GIA_MULTICAST_AGGR_20_AUX_GPDMA_TOP_GPDMA4_IRQ_28",
			"CPUACC_GIA_MULTICAST_AGGR_20_AUX_GPDMA_TOP_GPDMA4_IRQ_29",
			"CPUACC_GIA_MULTICAST_AGGR_20_AUX_GPDMA_TOP_GPDMA4_IRQ_30",
			"CPUACC_GIA_MULTICAST_AGGR_20_AUX_GPDMA_TOP_GPDMA4_IRQ_31";
	};

	fabdisp_pulse_aggr_0_test: fabdisp_pulse_aggr_0_test {
		compatible = "google,gia-test";
		interrupt-parent = <&fabdisp_pulse_aggr_0>;
		interrupts =
			<FABDISP_GIA_PULSE_AGGR_0_AUX_AON_GSPAN_ATB_INITIATOR_MEMSS_ATB_ICD_ERR_DSCGT>,
			<FABDISP_GIA_PULSE_AGGR_0_AUX_GSPAN_AXI_INITIATOR_G2D_CFG_ICD_ERR_DSCGT>,
			<FABDISP_GIA_PULSE_AGGR_0_AUX_GSPAN_AXI_INITIATOR_DPU_CFG_ICD_ERR_DSCGT>,
			<FABDISP_GIA_PULSE_AGGR_0_IP_IP_AON_TCU_ACEL_ICD_RQST_ERR_DSCGT>,
			<FABDISP_GIA_PULSE_AGGR_0_IP_IP_AON_TCU_DTI_ICD_ERR_DSCGT>,
			<FABDISP_GIA_PULSE_AGGR_0_IP_IP_AON_QBOX_ICD_ERR_DSCGT>,
			<FABDISP_GIA_PULSE_AGGR_0_AUX_AON_LPCM_ICD_ERR_DSCGT>,
			<FABDISP_GIA_PULSE_AGGR_0_IP_IP_AON_TCU_WRAPPER_EVENT_Q_IRPT_NS>,
			<FABDISP_GIA_PULSE_AGGR_0_IP_IP_AON_TCU_WRAPPER_CMD_SYNC_IRPT_NS>,
			<FABDISP_GIA_PULSE_AGGR_0_IP_IP_AON_TCU_WRAPPER_GLOBAL_IRPT_NS>,
			<FABDISP_GIA_PULSE_AGGR_0_IP_IP_AON_TCU_WRAPPER_RAS_FHI>,
			<FABDISP_GIA_PULSE_AGGR_0_IP_IP_AON_TCU_WRAPPER_RAS_ERI>,
			<FABDISP_GIA_PULSE_AGGR_0_IP_IP_AON_TCU_WRAPPER_RAS_CRI>,
			<FABDISP_GIA_PULSE_AGGR_0_IP_IP_AON_TCU_WRAPPER_PMU_IRPT>,
			<FABDISP_GIA_PULSE_AGGR_0_IP_IP_AON_TCU_WRAPPER_PRI_Q_IRPT_NS>,
			<31>;
		interrupt-names =
			"FABDISP_GIA_PULSE_AGGR_0_AUX_AON_GSPAN_ATB_INITIATOR_MEMSS_ATB_ICD_ERR_DSCGT",
			"FABDISP_GIA_PULSE_AGGR_0_AUX_GSPAN_AXI_INITIATOR_G2D_CFG_ICD_ERR_DSCGT",
			"FABDISP_GIA_PULSE_AGGR_0_AUX_GSPAN_AXI_INITIATOR_DPU_CFG_ICD_ERR_DSCGT",
			"FABDISP_GIA_PULSE_AGGR_0_IP_IP_AON_TCU_ACEL_ICD_RQST_ERR_DSCGT",
			"FABDISP_GIA_PULSE_AGGR_0_IP_IP_AON_TCU_DTI_ICD_ERR_DSCGT",
			"FABDISP_GIA_PULSE_AGGR_0_IP_IP_AON_QBOX_ICD_ERR_DSCGT",
			"FABDISP_GIA_PULSE_AGGR_0_AUX_AON_LPCM_ICD_ERR_DSCGT",
			"FABDISP_GIA_PULSE_AGGR_0_IP_IP_AON_TCU_WRAPPER_EVENT_Q_IRPT_NS",
			"FABDISP_GIA_PULSE_AGGR_0_IP_IP_AON_TCU_WRAPPER_CMD_SYNC_IRPT_NS",
			"FABDISP_GIA_PULSE_AGGR_0_IP_IP_AON_TCU_WRAPPER_GLOBAL_IRPT_NS",
			"FABDISP_GIA_PULSE_AGGR_0_IP_IP_AON_TCU_WRAPPER_RAS_FHI",
			"FABDISP_GIA_PULSE_AGGR_0_IP_IP_AON_TCU_WRAPPER_RAS_ERI",
			"FABDISP_GIA_PULSE_AGGR_0_IP_IP_AON_TCU_WRAPPER_RAS_CRI",
			"FABDISP_GIA_PULSE_AGGR_0_IP_IP_AON_TCU_WRAPPER_PMU_IRPT",
			"FABDISP_GIA_PULSE_AGGR_0_IP_IP_AON_TCU_WRAPPER_PRI_Q_IRPT_NS",
			"TEST_LINE_31";
	};

	fabmed_pulse_aggr_0_test: fabmed_pulse_aggr_0_test {
		compatible = "google,gia-test";
		interrupt-parent = <&fabmed_pulse_aggr_0>;
		interrupts =
			<FABMED_GIA_PULSE_AGGR_0_AUX_AON_LPCM_ICD_ERR_DSCGT>,
			<FABMED_GIA_PULSE_AGGR_0_AUX_GSPAN_AXI_INITIATOR_ISPFE_CFG_ICD_ERR_DSCGT>,
			<FABMED_GIA_PULSE_AGGR_0_AUX_GSPAN_AXI_INITIATOR_ISPBE_CFG_ICD_ERR_DSCGT>,
			<FABMED_GIA_PULSE_AGGR_0_AUX_GSPAN_AXI_INITIATOR_GCVE_CFG_ICD_ERR_DSCGT>,
			<FABMED_GIA_PULSE_AGGR_0_AUX_AON_GSPAN_ATB_INITIATOR_FABHBW_ATB_ICD_ERR_DSCGT>,
			<FABMED_GIA_PULSE_AGGR_0_AUX_GSPAN_AXI_INITIATOR_CODEC_3P_CFG_ICD_ERR_DSCGT>,
			<FABMED_GIA_PULSE_AGGR_0_IP_IP_AON_TCU_ACEL_ICD_RQST_ERR_DSCGT>,
			<FABMED_GIA_PULSE_AGGR_0_IP_IP_AON_TCU_DTI_ICD_ERR_DSCGT>,
			<FABMED_GIA_PULSE_AGGR_0_IP_IP_AON_QBOX_ICD_ERR_DSCGT>,
			<FABMED_GIA_PULSE_AGGR_0_IP_IP_AON_TCU_WRAPPER_EVENT_Q_IRPT_NS>,
			<FABMED_GIA_PULSE_AGGR_0_IP_IP_AON_TCU_WRAPPER_CMD_SYNC_IRPT_NS>,
			<FABMED_GIA_PULSE_AGGR_0_IP_IP_AON_TCU_WRAPPER_GLOBAL_IRPT_NS>,
			<FABMED_GIA_PULSE_AGGR_0_IP_IP_AON_TCU_WRAPPER_RAS_FHI>,
			<FABMED_GIA_PULSE_AGGR_0_IP_IP_AON_TCU_WRAPPER_RAS_ERI>,
			<FABMED_GIA_PULSE_AGGR_0_IP_IP_AON_TCU_WRAPPER_RAS_CRI>,
			<FABMED_GIA_PULSE_AGGR_0_IP_IP_AON_TCU_WRAPPER_PMU_IRPT>,
			<FABMED_GIA_PULSE_AGGR_0_IP_IP_AON_TCU_WRAPPER_PRI_Q_IRPT_NS>,
			<31>;
		interrupt-names =
			"FABMED_GIA_PULSE_AGGR_0_AUX_AON_LPCM_ICD_ERR_DSCGT",
			"FABMED_GIA_PULSE_AGGR_0_AUX_GSPAN_AXI_INITIATOR_ISPFE_CFG_ICD_ERR_DSCGT",
			"FABMED_GIA_PULSE_AGGR_0_AUX_GSPAN_AXI_INITIATOR_ISPBE_CFG_ICD_ERR_DSCGT",
			"FABMED_GIA_PULSE_AGGR_0_AUX_GSPAN_AXI_INITIATOR_GCVE_CFG_ICD_ERR_DSCGT",
			"FABMED_GIA_PULSE_AGGR_0_AUX_AON_GSPAN_ATB_INITIATOR_FABHBW_ATB_ICD_ERR_DSCGT",
			"FABMED_GIA_PULSE_AGGR_0_AUX_GSPAN_AXI_INITIATOR_CODEC_3P_CFG_ICD_ERR_DSCGT",
			"FABMED_GIA_PULSE_AGGR_0_IP_IP_AON_TCU_ACEL_ICD_RQST_ERR_DSCGT",
			"FABMED_GIA_PULSE_AGGR_0_IP_IP_AON_TCU_DTI_ICD_ERR_DSCGT",
			"FABMED_GIA_PULSE_AGGR_0_IP_IP_AON_QBOX_ICD_ERR_DSCGT",
			"FABMED_GIA_PULSE_AGGR_0_IP_IP_AON_TCU_WRAPPER_EVENT_Q_IRPT_NS",
			"FABMED_GIA_PULSE_AGGR_0_IP_IP_AON_TCU_WRAPPER_CMD_SYNC_IRPT_NS",
			"FABMED_GIA_PULSE_AGGR_0_IP_IP_AON_TCU_WRAPPER_GLOBAL_IRPT_NS",
			"FABMED_GIA_PULSE_AGGR_0_IP_IP_AON_TCU_WRAPPER_RAS_FHI",
			"FABMED_GIA_PULSE_AGGR_0_IP_IP_AON_TCU_WRAPPER_RAS_ERI",
			"FABMED_GIA_PULSE_AGGR_0_IP_IP_AON_TCU_WRAPPER_RAS_CRI",
			"FABMED_GIA_PULSE_AGGR_0_IP_IP_AON_TCU_WRAPPER_PMU_IRPT",
			"FABMED_GIA_PULSE_AGGR_0_IP_IP_AON_TCU_WRAPPER_PRI_Q_IRPT_NS",
			"TEST_LINE_31";
	};

	fabstby_pulse_aggr_0_test: fabstby_pulse_aggr_0_test {
		compatible = "google,gia-test";
		interrupt-parent = <&fabstby_pulse_aggr_0>;
		interrupts =
			<FABSTBY_GIA_PULSE_AGGR_0_AUX_GSPAN_AXI_INITIATOR_AOSS_CFG_GSPAN_AXI_INITIATOR_ICD_AXI4_ICD_AXI4_ERR_DSCGT_NEXT>,
			<FABSTBY_GIA_PULSE_AGGR_0_AUX_GSPAN_AXI_INITIATOR_AOSS_GSM_CFG_GSPAN_AXI_INITIATOR_ICD_AXI4_ICD_AXI4_ERR_DSCGT_NEXT>,
			<FABSTBY_GIA_PULSE_AGGR_0_AUX_GSPAN_AXI_INITIATOR_BMSM_CFG_ICD_ERR_DSCGT>,
			<FABSTBY_GIA_PULSE_AGGR_0_AUX_GSPAN_AXI_INITIATOR_CPUACC_CFG_ICD_ERR_DSCGT>,
			<FABSTBY_GIA_PULSE_AGGR_0_AUX_AON_GSPAN_ATB_INITIATOR_GDMC_ATB_ICD_ERR_DSCGT>,
			<FABSTBY_GIA_PULSE_AGGR_0_AUX_GSPAN_AXI_INITIATOR_GDMC_CFG_ICD_ERR_DSCGT>,
			<FABSTBY_GIA_PULSE_AGGR_0_AUX_GSPAN_AXI_INITIATOR_GPCA_CFG_ICD_ERR_DSCGT>,
			<FABSTBY_GIA_PULSE_AGGR_0_AUX_GSPAN_AXI_INITIATOR_GSA_CFG_ICD_ERR_DSCGT>,
			<FABSTBY_GIA_PULSE_AGGR_0_AUX_GSPAN_AXI_INITIATOR_HSIO_N_CFG_ICD_ERR_DSCGT>,
			<FABSTBY_GIA_PULSE_AGGR_0_AUX_GSPAN_AXI_INITIATOR_PCIE_PCIE_TGT_GSPAN_AXI_INITIATOR_ICD_AXI4_ICD_AXI4_ERR_DSCGT_NEXT>,
			<FABSTBY_GIA_PULSE_AGGR_0_AUX_GSPAN_AXI_INITIATOR_PCIE_CFG_GSPAN_AXI_INITIATOR_ICD_AXI4_ICD_AXI4_ERR_DSCGT_NEXT>,
			<FABSTBY_GIA_PULSE_AGGR_0_IP_IP_AON_TCU_ACEL_ICD_RQST_ERR_DSCGT>,
			<FABSTBY_GIA_PULSE_AGGR_0_IP_IP_AON_TCU_DTI_ICD_ERR_DSCGT>,
			<FABSTBY_GIA_PULSE_AGGR_0_IP_IP_AON_QBOX_ICD_ERR_DSCGT>,
			<FABSTBY_GIA_PULSE_AGGR_0_AUX_AON_LPCM_ICD_ERR_DSCGT>,
			<FABSTBY_GIA_PULSE_AGGR_0_IP_IP_AON_TCU_WRAPPER_EVENT_Q_IRPT_NS>,
			<FABSTBY_GIA_PULSE_AGGR_0_IP_IP_AON_TCU_WRAPPER_CMD_SYNC_IRPT_NS>,
			<FABSTBY_GIA_PULSE_AGGR_0_IP_IP_AON_TCU_WRAPPER_GLOBAL_IRPT_NS>,
			<FABSTBY_GIA_PULSE_AGGR_0_IP_IP_AON_TCU_WRAPPER_RAS_FHI>,
			<FABSTBY_GIA_PULSE_AGGR_0_IP_IP_AON_TCU_WRAPPER_RAS_ERI>,
			<FABSTBY_GIA_PULSE_AGGR_0_IP_IP_AON_TCU_WRAPPER_RAS_CRI>,
			<FABSTBY_GIA_PULSE_AGGR_0_IP_IP_AON_TCU_WRAPPER_PMU_IRPT>,
			<FABSTBY_GIA_PULSE_AGGR_0_IP_IP_AON_TCU_WRAPPER_PRI_Q_IRPT_NS>,
			<31>;
		interrupt-names =
			"FABSTBY_GIA_PULSE_AGGR_0_AUX_GSPAN_AXI_INITIATOR_AOSS_CFG_GSPAN_AXI_INITIATOR_ICD_AXI4_ICD_AXI4_ERR_DSCGT_NEXT",
			"FABSTBY_GIA_PULSE_AGGR_0_AUX_GSPAN_AXI_INITIATOR_AOSS_GSM_CFG_GSPAN_AXI_INITIATOR_ICD_AXI4_ICD_AXI4_ERR_DSCGT_NEXT",
			"FABSTBY_GIA_PULSE_AGGR_0_AUX_GSPAN_AXI_INITIATOR_BMSM_CFG_ICD_ERR_DSCGT",
			"FABSTBY_GIA_PULSE_AGGR_0_AUX_GSPAN_AXI_INITIATOR_CPUACC_CFG_ICD_ERR_DSCGT",
			"FABSTBY_GIA_PULSE_AGGR_0_AUX_AON_GSPAN_ATB_INITIATOR_GDMC_ATB_ICD_ERR_DSCGT",
			"FABSTBY_GIA_PULSE_AGGR_0_AUX_GSPAN_AXI_INITIATOR_GDMC_CFG_ICD_ERR_DSCGT",
			"FABSTBY_GIA_PULSE_AGGR_0_AUX_GSPAN_AXI_INITIATOR_GPCA_CFG_ICD_ERR_DSCGT",
			"FABSTBY_GIA_PULSE_AGGR_0_AUX_GSPAN_AXI_INITIATOR_GSA_CFG_ICD_ERR_DSCGT",
			"FABSTBY_GIA_PULSE_AGGR_0_AUX_GSPAN_AXI_INITIATOR_HSIO_N_CFG_ICD_ERR_DSCGT",
			"FABSTBY_GIA_PULSE_AGGR_0_AUX_GSPAN_AXI_INITIATOR_PCIE_PCIE_TGT_GSPAN_AXI_INITIATOR_ICD_AXI4_ICD_AXI4_ERR_DSCGT_NEXT",
			"FABSTBY_GIA_PULSE_AGGR_0_AUX_GSPAN_AXI_INITIATOR_PCIE_CFG_GSPAN_AXI_INITIATOR_ICD_AXI4_ICD_AXI4_ERR_DSCGT_NEXT",
			"FABSTBY_GIA_PULSE_AGGR_0_IP_IP_AON_TCU_ACEL_ICD_RQST_ERR_DSCGT",
			"FABSTBY_GIA_PULSE_AGGR_0_IP_IP_AON_TCU_DTI_ICD_ERR_DSCGT",
			"FABSTBY_GIA_PULSE_AGGR_0_IP_IP_AON_QBOX_ICD_ERR_DSCGT",
			"FABSTBY_GIA_PULSE_AGGR_0_AUX_AON_LPCM_ICD_ERR_DSCGT",
			"FABSTBY_GIA_PULSE_AGGR_0_IP_IP_AON_TCU_WRAPPER_EVENT_Q_IRPT_NS",
			"FABSTBY_GIA_PULSE_AGGR_0_IP_IP_AON_TCU_WRAPPER_CMD_SYNC_IRPT_NS",
			"FABSTBY_GIA_PULSE_AGGR_0_IP_IP_AON_TCU_WRAPPER_GLOBAL_IRPT_NS",
			"FABSTBY_GIA_PULSE_AGGR_0_IP_IP_AON_TCU_WRAPPER_RAS_FHI",
			"FABSTBY_GIA_PULSE_AGGR_0_IP_IP_AON_TCU_WRAPPER_RAS_ERI",
			"FABSTBY_GIA_PULSE_AGGR_0_IP_IP_AON_TCU_WRAPPER_RAS_CRI",
			"FABSTBY_GIA_PULSE_AGGR_0_IP_IP_AON_TCU_WRAPPER_PMU_IRPT",
			"FABSTBY_GIA_PULSE_AGGR_0_IP_IP_AON_TCU_WRAPPER_PRI_Q_IRPT_NS",
			"TEST_LINE_31";
	};

	gpu_multicast_aggr_5_test: gpu_multicast_aggr_5_test {
		compatible = "google,gia-test";
		power-domains = <&sswrp_gpu_pd>;
		interrupt-parent = <&gpu_multicast_aggr_5>;
		interrupts =
			<GPU_GIA_MULTICAST_AGGR_5_AUX_AON_LPCM_PWRAP_RFW_G0R128_NS_INTR>,
			<GPU_GIA_MULTICAST_AGGR_5_AUX_AON_AON_PWRAP_RFW_G0R32_NS_INTR>,
			<GPU_GIA_MULTICAST_AGGR_5_AUX_APB2MAPB_PWRAP_RFW_G0R1280_NS_INTR>,
			<GPU_GIA_MULTICAST_AGGR_5_AUX_TOP_AWRAP_RFW_G0R512_NS_INTR>,
			<GPU_GIA_MULTICAST_AGGR_5_AUX_DS_INST_RA_TOP_0_NS_INTR>,
			<GPU_GIA_MULTICAST_AGGR_5_AUX_DS_INST_RA_TOP_1_NS_INTR>,
			<GPU_GIA_MULTICAST_AGGR_5_AUX_DS_INST_RA_TOP_2_NS_INTR>,
			<GPU_GIA_MULTICAST_AGGR_5_AUX_DS_INST_GEM_TOP_TBU_MST0_INST_IRQ>,
			<GPU_GIA_MULTICAST_AGGR_5_AUX_DS_INST_GEM_TOP_TBU_MST1_INST_IRQ>,
			<GPU_GIA_MULTICAST_AGGR_5_AUX_DS_INST_GEM_TOP_TBU_MST2_INST_IRQ>,
			<GPU_GIA_MULTICAST_AGGR_5_AUX_DS_INST_GEM_TOP_TCU_INST_IRQ>,
			<GPU_GIA_MULTICAST_AGGR_5_AUX_DS_INST_IFABRIC_FABWRPGPU_IXBAR0_XBA0_ERR_IRQ>,
			<GPU_GIA_MULTICAST_AGGR_5_AUX_DS_INST_CPHBWGPU_IFABRIC_HBW_XBA00_ERR_IRQ>,
			<GPU_GIA_MULTICAST_AGGR_5_AUX_AON_AON_GIA_PULSE_AGGR_INTR_1>,
			<31>;
		interrupt-names =
			"GPU_GIA_MULTICAST_AGGR_5_AUX_AON_LPCM_PWRAP_RFW_G0R128_NS_INTR",
			"GPU_GIA_MULTICAST_AGGR_5_AUX_AON_AON_PWRAP_RFW_G0R32_NS_INTR",
			"GPU_GIA_MULTICAST_AGGR_5_AUX_APB2MAPB_PWRAP_RFW_G0R1280_NS_INTR",
			"GPU_GIA_MULTICAST_AGGR_5_AUX_TOP_AWRAP_RFW_G0R512_NS_INTR",
			"GPU_GIA_MULTICAST_AGGR_5_AUX_DS_INST_RA_TOP_0_NS_INTR",
			"GPU_GIA_MULTICAST_AGGR_5_AUX_DS_INST_RA_TOP_1_NS_INTR",
			"GPU_GIA_MULTICAST_AGGR_5_AUX_DS_INST_RA_TOP_2_NS_INTR",
			"GPU_GIA_MULTICAST_AGGR_5_AUX_DS_INST_GEM_TOP_TBU_MST0_INST_IRQ",
			"GPU_GIA_MULTICAST_AGGR_5_AUX_DS_INST_GEM_TOP_TBU_MST1_INST_IRQ",
			"GPU_GIA_MULTICAST_AGGR_5_AUX_DS_INST_GEM_TOP_TBU_MST2_INST_IRQ",
			"GPU_GIA_MULTICAST_AGGR_5_AUX_DS_INST_GEM_TOP_TCU_INST_IRQ",
			"GPU_GIA_MULTICAST_AGGR_5_AUX_DS_INST_IFABRIC_FABWRPGPU_IXBAR0_XBA0_ERR_IRQ",
			"GPU_GIA_MULTICAST_AGGR_5_AUX_DS_INST_CPHBWGPU_IFABRIC_HBW_XBA00_ERR_IRQ",
			"GPU_GIA_MULTICAST_AGGR_5_AUX_AON_AON_GIA_PULSE_AGGR_INTR_1",
			"TEST_LINE_31";
	};

	gpu_pulse_aggr_1_test: gpu_pulse_aggr_1_test {
		compatible = "google,gia-test";
		power-domains = <&sswrp_gpu_pd>;
		interrupt-parent = <&gpu_pulse_aggr_1>;
		interrupts =
			<GPU_GIA_PULSE_AGGR_1_AUX_DS_INST_SMMU_TBU0_RAS_FHI>,
			<GPU_GIA_PULSE_AGGR_1_AUX_DS_INST_SMMU_TBU0_RAS_ERI>,
			<GPU_GIA_PULSE_AGGR_1_AUX_DS_INST_SMMU_TBU0_RAS_CRI>,
			<GPU_GIA_PULSE_AGGR_1_AUX_DS_INST_SMMU_TBU0_PMU_IRPT>,
			<GPU_GIA_PULSE_AGGR_1_AUX_DS_INST_SMMU_TBU1_RAS_FHI>,
			<GPU_GIA_PULSE_AGGR_1_AUX_DS_INST_SMMU_TBU1_RAS_ERI>,
			<GPU_GIA_PULSE_AGGR_1_AUX_DS_INST_SMMU_TBU1_RAS_CRI>,
			<GPU_GIA_PULSE_AGGR_1_AUX_DS_INST_SMMU_TBU1_PMU_IRPT>,
			<GPU_GIA_PULSE_AGGR_1_AUX_DS_INST_SMMU_TBU2_RAS_FHI>,
			<GPU_GIA_PULSE_AGGR_1_AUX_DS_INST_SMMU_TBU2_RAS_ERI>,
			<GPU_GIA_PULSE_AGGR_1_AUX_DS_INST_SMMU_TBU2_RAS_CRI>,
			<GPU_GIA_PULSE_AGGR_1_AUX_DS_INST_SMMU_TBU2_PMU_IRPT>,
			<GPU_GIA_PULSE_AGGR_1_AUX_DS_INST_SMMU_TCU_RAS_FHI>,
			<GPU_GIA_PULSE_AGGR_1_AUX_DS_INST_SMMU_TCU_RAS_ERI>,
			<GPU_GIA_PULSE_AGGR_1_AUX_DS_INST_SMMU_TCU_RAS_CRI>,
			<GPU_GIA_PULSE_AGGR_1_AUX_DS_INST_SMMU_TCU_PMU_IRPT>,
			<GPU_GIA_PULSE_AGGR_1_AUX_DS_INST_SMMU_TCU_PRI_Q_IRPT_NS>,
			<GPU_GIA_PULSE_AGGR_1_AUX_DS_INST_SMMU_TCU_GLOBAL_IRPT_NS>,
			<GPU_GIA_PULSE_AGGR_1_AUX_DS_INST_SMMU_TCU_CMD_SYNC_IRPT_NS>,
			<GPU_GIA_PULSE_AGGR_1_AUX_DS_INST_SMMU_TCU_EVENT_Q_IRPT_NS>,
			<GPU_GIA_PULSE_AGGR_1_AUX_DS_INST_GSPAN_ATB_INIT_INST_ICD_ERR_DSCGT>,
			<31>;
		interrupt-names =
			"GPU_GIA_PULSE_AGGR_1_AUX_DS_INST_SMMU_TBU0_RAS_FHI",
			"GPU_GIA_PULSE_AGGR_1_AUX_DS_INST_SMMU_TBU0_RAS_ERI",
			"GPU_GIA_PULSE_AGGR_1_AUX_DS_INST_SMMU_TBU0_RAS_CRI",
			"GPU_GIA_PULSE_AGGR_1_AUX_DS_INST_SMMU_TBU0_PMU_IRPT",
			"GPU_GIA_PULSE_AGGR_1_AUX_DS_INST_SMMU_TBU1_RAS_FHI",
			"GPU_GIA_PULSE_AGGR_1_AUX_DS_INST_SMMU_TBU1_RAS_ERI",
			"GPU_GIA_PULSE_AGGR_1_AUX_DS_INST_SMMU_TBU1_RAS_CRI",
			"GPU_GIA_PULSE_AGGR_1_AUX_DS_INST_SMMU_TBU1_PMU_IRPT",
			"GPU_GIA_PULSE_AGGR_1_AUX_DS_INST_SMMU_TBU2_RAS_FHI",
			"GPU_GIA_PULSE_AGGR_1_AUX_DS_INST_SMMU_TBU2_RAS_ERI",
			"GPU_GIA_PULSE_AGGR_1_AUX_DS_INST_SMMU_TBU2_RAS_CRI",
			"GPU_GIA_PULSE_AGGR_1_AUX_DS_INST_SMMU_TBU2_PMU_IRPT",
			"GPU_GIA_PULSE_AGGR_1_AUX_DS_INST_SMMU_TCU_RAS_FHI",
			"GPU_GIA_PULSE_AGGR_1_AUX_DS_INST_SMMU_TCU_RAS_ERI",
			"GPU_GIA_PULSE_AGGR_1_AUX_DS_INST_SMMU_TCU_RAS_CRI",
			"GPU_GIA_PULSE_AGGR_1_AUX_DS_INST_SMMU_TCU_PMU_IRPT",
			"GPU_GIA_PULSE_AGGR_1_AUX_DS_INST_SMMU_TCU_PRI_Q_IRPT_NS",
			"GPU_GIA_PULSE_AGGR_1_AUX_DS_INST_SMMU_TCU_GLOBAL_IRPT_NS",
			"GPU_GIA_PULSE_AGGR_1_AUX_DS_INST_SMMU_TCU_CMD_SYNC_IRPT_NS",
			"GPU_GIA_PULSE_AGGR_1_AUX_DS_INST_SMMU_TCU_EVENT_Q_IRPT_NS",
			"GPU_GIA_PULSE_AGGR_1_AUX_DS_INST_GSPAN_ATB_INIT_INST_ICD_ERR_DSCGT",
			"TEST_LINE_31";
	};

	gsa_pulse_aggr_2_test: gsa_pulse_aggr_2_test {
		compatible = "google,gia-test";
		interrupt-parent = <&gsa_pulse_aggr_2>;
		interrupts =
			<GSA_GIA_PULSE_AGGR_2_AUX_TBU_WRAPPER_TBU_PMU_IRPT>,
			<GSA_GIA_PULSE_AGGR_2_AUX_TBU_WRAPPER_TBU_RAS_FHI>,
			<GSA_GIA_PULSE_AGGR_2_AUX_TBU_WRAPPER_TBU_RAS_ERI>,
			<GSA_GIA_PULSE_AGGR_2_AUX_TBU_WRAPPER_TBU_RAS_CRI>,
			<31>;
		interrupt-names =
			"GSA_GIA_PULSE_AGGR_2_AUX_TBU_WRAPPER_TBU_PMU_IRPT",
			"GSA_GIA_PULSE_AGGR_2_AUX_TBU_WRAPPER_TBU_RAS_FHI",
			"GSA_GIA_PULSE_AGGR_2_AUX_TBU_WRAPPER_TBU_RAS_ERI",
			"GSA_GIA_PULSE_AGGR_2_AUX_TBU_WRAPPER_TBU_RAS_CRI",
			"TEST_LINE_31";
	};

	gsa_level_aggr_1_test: gsa_level_aggr_1_test {
		compatible = "google,gia-test";
		interrupt-parent = <&gsa_level_aggr_1>;
		interrupts =
			<GSA_GIA_LEVEL_AGGR_1_AUX_AON_AON_GIA_GIA_PULSE_AGGR_INTR_2>,
			<GSA_GIA_LEVEL_AGGR_1_AUX_AON_AON_GIA_GIA_MULTICAST_AGGR_INTR_1>,
			<GSA_GIA_LEVEL_AGGR_1_GSA_GIA_MULTICAST_AGGR_INTR_1>,
			<GSA_GIA_LEVEL_AGGR_1_GSA_GIA_PULSE_AGGR_INTR_2>,
			<31>;
		interrupt-names =
			"GSA_GIA_LEVEL_AGGR_1_AUX_AON_AON_GIA_GIA_PULSE_AGGR_INTR_2",
			"GSA_GIA_LEVEL_AGGR_1_AUX_AON_AON_GIA_GIA_MULTICAST_AGGR_INTR_1",
			"GSA_GIA_LEVEL_AGGR_1_GSA_GIA_MULTICAST_AGGR_INTR_1",
			"GSA_GIA_LEVEL_AGGR_1_GSA_GIA_PULSE_AGGR_INTR_2",
			"TEST_LINE_31";
	};

	hsion_multicast_aggr_5_test: hsion_multicast_aggr_5_test {
		compatible = "google,gia-test";
		power-domains = <&sswrp_hsio_n_pd>;
		interrupt-parent = <&hsion_multicast_aggr_5>;
		interrupts =
			<31>;
		interrupt-names =
			"TEST_LINE_31";
	};

	hsion_multicast_aggr_6_test: hsion_multicast_aggr_6_test {
		compatible = "google,gia-test";
		power-domains = <&sswrp_hsio_n_pd>;
		interrupt-parent = <&hsion_multicast_aggr_6>;
		interrupts =
			<31>;
		interrupt-names =
			"TEST_LINE_31";
	};

	hsion_pulse_aggr_2_test: hsion_pulse_aggr_2_test {
		compatible = "google,gia-test";
		power-domains = <&sswrp_hsio_n_pd>;
		interrupt-parent = <&hsion_pulse_aggr_2>;
		interrupts =
			<31>;
		interrupt-names =
			"TEST_LINE_31";
	};

	hsion_level_aggr_1_test: hsion_level_aggr_1_test {
		compatible = "google,gia-test";
		power-domains = <&sswrp_hsio_n_pd>;
		interrupt-parent = <&hsion_level_aggr_1>;
		interrupts =
			<31>;
		interrupt-names =
			"TEST_LINE_31";
	};

	hsios_multicast_aggr_2_test: hsios_multicast_aggr_2_test {
		compatible = "google,gia-test";
		power-domains = <&sswrp_hsio_s_pd>;
		interrupt-parent = <&hsios_multicast_aggr_2>;
		interrupts =
			<31>;
		interrupt-names =
			"TEST_LINE_31";
	};

	hsios_multicast_aggr_3_test: hsios_multicast_aggr_3_test {
		compatible = "google,gia-test";
		power-domains = <&sswrp_hsio_s_pd>;
		interrupt-parent = <&hsios_multicast_aggr_3>;
		interrupts =
			<31>;
		interrupt-names =
			"TEST_LINE_31";
	};

	hsios_pulse_aggr_2_test: hsios_pulse_aggr_2_test {
		compatible = "google,gia-test";
		power-domains = <&sswrp_hsio_s_pd>;
		interrupt-parent = <&hsios_pulse_aggr_2>;
		interrupts =
			<31>;
		interrupt-names =
			"TEST_LINE_31";
	};

	lsioe_multicast_aggr_1_test: lsioe_multicast_aggr_1_test {
		compatible = "google,gia-test";
		power-domains = <&sswrp_lsio_e_pd>;
		interrupt-parent = <&lsioe_multicast_aggr_1>;
		interrupts =
			<LSIOE_GIA_MULTICAST_AGGR_1_AUX_AON_RFW0_NS_INTR>,
			<LSIOE_GIA_MULTICAST_AGGR_1_AUX_AON_RFW1_NS_INTR>,
			<LSIOE_GIA_MULTICAST_AGGR_1_AUX_GEM0_IRQ>,
			<LSIOE_GIA_MULTICAST_AGGR_1_AUX_AON_GP_CSR_RESERVED0_RES0_R_0>,
			<LSIOE_GIA_MULTICAST_AGGR_1_AUX_AON_GP_CSR_RESERVED0_RES0_R_1>,
			<LSIOE_GIA_MULTICAST_AGGR_1_AUX_AON_GP_CSR_RESERVED0_RES0_R_2>,
			<LSIOE_GIA_MULTICAST_AGGR_1_AUX_AON_GP_CSR_RESERVED0_RES0_R_3>,
			<LSIOE_GIA_MULTICAST_AGGR_1_AUX_AON_GP_CSR_RESERVED0_RES0_R_4>,
			<LSIOE_GIA_MULTICAST_AGGR_1_AUX_AON_GP_CSR_RESERVED0_RES0_R_5>,
			<LSIOE_GIA_MULTICAST_AGGR_1_AUX_AON_GP_CSR_RESERVED0_RES0_R_6>,
			<LSIOE_GIA_MULTICAST_AGGR_1_AUX_AON_GP_CSR_RESERVED0_RES0_R_7>,
			<LSIOE_GIA_MULTICAST_AGGR_1_IP_TOP_SPI_0_SSI_INTR>,
			<LSIOE_GIA_MULTICAST_AGGR_1_IP_TOP_SPI_1_SSI_INTR>,
			<LSIOE_GIA_MULTICAST_AGGR_1_IP_TOP_UART_0_INTR>,
			<LSIOE_GIA_MULTICAST_AGGR_1_IP_TOP_UART_1_INTR>,
			<LSIOE_GIA_MULTICAST_AGGR_1_IP_TOP_I3C_0_IC_INTR>,
			<LSIOE_GIA_MULTICAST_AGGR_1_IP_TOP_I3C_1_IC_INTR>,
			<LSIOE_GIA_MULTICAST_AGGR_1_IP_TOP_I3C_2_IC_INTR>,
			<LSIOE_GIA_MULTICAST_AGGR_1_IP_TOP_I3C_3_IC_INTR>,
			<LSIOE_GIA_MULTICAST_AGGR_1_IP_TOP_I3C_4_IC_INTR>,
			<LSIOE_GIA_MULTICAST_AGGR_1_IP_TOP_I2C_0_IC_INTR>,
			<LSIOE_GIA_MULTICAST_AGGR_1_IP_TOP_I2C_1_IC_INTR>,
			<LSIOE_GIA_MULTICAST_AGGR_1_IP_TOP_I2C_2_IC_INTR>,
			<LSIOE_GIA_MULTICAST_AGGR_1_IP_TOP_I2C_3_IC_INTR>,
			<LSIOE_GIA_MULTICAST_AGGR_1_IP_TOP_I2C_4_IC_INTR>,
			<LSIOE_GIA_MULTICAST_AGGR_1_AUX_AON_IOBANK_XLSIOE_I23C5_SCL_IRQ>,
			<LSIOE_GIA_MULTICAST_AGGR_1_AUX_AON_IOBANK_XLSIOE_I23C5_SDA_IRQ>,
			<LSIOE_GIA_MULTICAST_AGGR_1_AUX_AON_IOBANK_XLSIOE_I23C6_SCL_IRQ>,
			<LSIOE_GIA_MULTICAST_AGGR_1_AUX_AON_IOBANK_XLSIOE_I23C6_SDA_IRQ>,
			<LSIOE_GIA_MULTICAST_AGGR_1_AUX_AON_IOBANK_XLSIOE_SPIU4_SCLK_RTSN_IRQ>,
			<LSIOE_GIA_MULTICAST_AGGR_1_AUX_AON_IOBANK_XLSIOE_SPIU4_MOSI_TXD_IRQ>,
			<LSIOE_GIA_MULTICAST_AGGR_1_AUX_AON_IOBANK_XLSIOE_SPIU4_MISO_RXD_IRQ>;
		interrupt-names =
			"LSIOE_GIA_MULTICAST_AGGR_1_AUX_AON_RFW0_NS_INTR",
			"LSIOE_GIA_MULTICAST_AGGR_1_AUX_AON_RFW1_NS_INTR",
			"LSIOE_GIA_MULTICAST_AGGR_1_AUX_GEM0_IRQ",
			"LSIOE_GIA_MULTICAST_AGGR_1_AUX_AON_GP_CSR_RESERVED0_RES0_R_0",
			"LSIOE_GIA_MULTICAST_AGGR_1_AUX_AON_GP_CSR_RESERVED0_RES0_R_1",
			"LSIOE_GIA_MULTICAST_AGGR_1_AUX_AON_GP_CSR_RESERVED0_RES0_R_2",
			"LSIOE_GIA_MULTICAST_AGGR_1_AUX_AON_GP_CSR_RESERVED0_RES0_R_3",
			"LSIOE_GIA_MULTICAST_AGGR_1_AUX_AON_GP_CSR_RESERVED0_RES0_R_4",
			"LSIOE_GIA_MULTICAST_AGGR_1_AUX_AON_GP_CSR_RESERVED0_RES0_R_5",
			"LSIOE_GIA_MULTICAST_AGGR_1_AUX_AON_GP_CSR_RESERVED0_RES0_R_6",
			"LSIOE_GIA_MULTICAST_AGGR_1_AUX_AON_GP_CSR_RESERVED0_RES0_R_7",
			"LSIOE_GIA_MULTICAST_AGGR_1_IP_TOP_SPI_0_SSI_INTR",
			"LSIOE_GIA_MULTICAST_AGGR_1_IP_TOP_SPI_1_SSI_INTR",
			"LSIOE_GIA_MULTICAST_AGGR_1_IP_TOP_UART_0_INTR",
			"LSIOE_GIA_MULTICAST_AGGR_1_IP_TOP_UART_1_INTR",
			"LSIOE_GIA_MULTICAST_AGGR_1_IP_TOP_I3C_0_IC_INTR",
			"LSIOE_GIA_MULTICAST_AGGR_1_IP_TOP_I3C_1_IC_INTR",
			"LSIOE_GIA_MULTICAST_AGGR_1_IP_TOP_I3C_2_IC_INTR",
			"LSIOE_GIA_MULTICAST_AGGR_1_IP_TOP_I3C_3_IC_INTR",
			"LSIOE_GIA_MULTICAST_AGGR_1_IP_TOP_I3C_4_IC_INTR",
			"LSIOE_GIA_MULTICAST_AGGR_1_IP_TOP_I2C_0_IC_INTR",
			"LSIOE_GIA_MULTICAST_AGGR_1_IP_TOP_I2C_1_IC_INTR",
			"LSIOE_GIA_MULTICAST_AGGR_1_IP_TOP_I2C_2_IC_INTR",
			"LSIOE_GIA_MULTICAST_AGGR_1_IP_TOP_I2C_3_IC_INTR",
			"LSIOE_GIA_MULTICAST_AGGR_1_IP_TOP_I2C_4_IC_INTR",
			"LSIOE_GIA_MULTICAST_AGGR_1_AUX_AON_IOBANK_XLSIOE_I23C5_SCL_IRQ",
			"LSIOE_GIA_MULTICAST_AGGR_1_AUX_AON_IOBANK_XLSIOE_I23C5_SDA_IRQ",
			"LSIOE_GIA_MULTICAST_AGGR_1_AUX_AON_IOBANK_XLSIOE_I23C6_SCL_IRQ",
			"LSIOE_GIA_MULTICAST_AGGR_1_AUX_AON_IOBANK_XLSIOE_I23C6_SDA_IRQ",
			"LSIOE_GIA_MULTICAST_AGGR_1_AUX_AON_IOBANK_XLSIOE_SPIU4_SCLK_RTSN_IRQ",
			"LSIOE_GIA_MULTICAST_AGGR_1_AUX_AON_IOBANK_XLSIOE_SPIU4_MOSI_TXD_IRQ",
			"LSIOE_GIA_MULTICAST_AGGR_1_AUX_AON_IOBANK_XLSIOE_SPIU4_MISO_RXD_IRQ";
	};

	lsioe_multicast_aggr_2_test: lsioe_multicast_aggr_2_test {
		compatible = "google,gia-test";
		power-domains = <&sswrp_lsio_e_pd>;
		interrupt-parent = <&lsioe_multicast_aggr_2>;
		interrupts =
			<LSIOE_GIA_MULTICAST_AGGR_2_AUX_AON_IOBANK_XLSIOE_SPIU4_CSN_CTSN_IRQ>,
			<LSIOE_GIA_MULTICAST_AGGR_2_AUX_AON_IOBANK_XLSIOE_I23C7_SCL_IRQ>,
			<LSIOE_GIA_MULTICAST_AGGR_2_AUX_AON_IOBANK_XLSIOE_I23C7_SDA_IRQ>,
			<LSIOE_GIA_MULTICAST_AGGR_2_AUX_AON_IOBANK_XLSIOE_GPIO19_IRQ>,
			<LSIOE_GIA_MULTICAST_AGGR_2_AUX_AON_IOBANK_XLSIOE_GPIO20_IRQ>,
			<LSIOE_GIA_MULTICAST_AGGR_2_AUX_AON_IOBANK_XLSIOE_GPIO21_IRQ>,
			<LSIOE_GIA_MULTICAST_AGGR_2_AUX_AON_IOBANK_XLSIOE_GPIO22_IRQ>,
			<LSIOE_GIA_MULTICAST_AGGR_2_AUX_AON_IOBANK_XLSIOE_GPIO23_IRQ>,
			<LSIOE_GIA_MULTICAST_AGGR_2_AUX_AON_IOBANK_XLSIOE_GPIO24_IRQ>,
			<LSIOE_GIA_MULTICAST_AGGR_2_AUX_AON_IOBANK_XLSIOE_GPIO25_IRQ>,
			<LSIOE_GIA_MULTICAST_AGGR_2_AUX_AON_IOBANK_XLSIOE_GPIO26_IRQ>,
			<LSIOE_GIA_MULTICAST_AGGR_2_AUX_AON_IOBANK_XLSIOE_GPIO27_IRQ>,
			<LSIOE_GIA_MULTICAST_AGGR_2_AUX_AON_IOBANK_XLSIOE_GPIO28_IRQ>,
			<LSIOE_GIA_MULTICAST_AGGR_2_AUX_AON_IOBANK_XLSIOE_GPIO29_IRQ>,
			<LSIOE_GIA_MULTICAST_AGGR_2_AUX_AON_IOBANK_XLSIOE_GPIO30_IRQ>,
			<LSIOE_GIA_MULTICAST_AGGR_2_AUX_AON_IOBANK_XLSIOE_GPIO31_IRQ>,
			<LSIOE_GIA_MULTICAST_AGGR_2_AUX_AON_IOBANK_XLSIOE_GPIO32_IRQ>,
			<LSIOE_GIA_MULTICAST_AGGR_2_AUX_AON_IOBANK_XLSIOE_GPIO33_IRQ>,
			<LSIOE_GIA_MULTICAST_AGGR_2_AUX_AON_IOBANK_XLSIOE_I23C8_SCL_IRQ>,
			<LSIOE_GIA_MULTICAST_AGGR_2_AUX_AON_IOBANK_XLSIOE_I23C8_SDA_IRQ>,
			<LSIOE_GIA_MULTICAST_AGGR_2_AUX_AON_IOBANK_XLSIOE_GPIO34_IRQ>,
			<LSIOE_GIA_MULTICAST_AGGR_2_AUX_AON_IOBANK_XLSIOE_I23C9_SCL_IRQ>,
			<LSIOE_GIA_MULTICAST_AGGR_2_AUX_AON_IOBANK_XLSIOE_I23C9_SDA_IRQ>,
			<LSIOE_GIA_MULTICAST_AGGR_2_AUX_AON_IOBANK_XLSIOE_SPIU5_SCLK_RTSN_IRQ>,
			<LSIOE_GIA_MULTICAST_AGGR_2_AUX_AON_IOBANK_XLSIOE_SPIU5_MOSI_TXD_IRQ>,
			<LSIOE_GIA_MULTICAST_AGGR_2_AUX_AON_IOBANK_XLSIOE_SPIU5_MISO_RXD_IRQ>,
			<LSIOE_GIA_MULTICAST_AGGR_2_AUX_AON_IOBANK_XLSIOE_SPIU5_CSN_CTSN_IRQ>,
			<LSIOE_GIA_MULTICAST_AGGR_2_AUX_AON_IOBANK_XLSIOE_GPIO35_IRQ>,
			<LSIOE_GIA_MULTICAST_AGGR_2_AUX_AON_IOBANK_XLSIOE_GPIO36_IRQ>,
			<LSIOE_GIA_MULTICAST_AGGR_2_AUX_AON_IOBANK_XLSIOE_GPIO37_IRQ>,
			<31>;
		interrupt-names =
			"LSIOE_GIA_MULTICAST_AGGR_2_AUX_AON_IOBANK_XLSIOE_SPIU4_CSN_CTSN_IRQ",
			"LSIOE_GIA_MULTICAST_AGGR_2_AUX_AON_IOBANK_XLSIOE_I23C7_SCL_IRQ",
			"LSIOE_GIA_MULTICAST_AGGR_2_AUX_AON_IOBANK_XLSIOE_I23C7_SDA_IRQ",
			"LSIOE_GIA_MULTICAST_AGGR_2_AUX_AON_IOBANK_XLSIOE_GPIO19_IRQ",
			"LSIOE_GIA_MULTICAST_AGGR_2_AUX_AON_IOBANK_XLSIOE_GPIO20_IRQ",
			"LSIOE_GIA_MULTICAST_AGGR_2_AUX_AON_IOBANK_XLSIOE_GPIO21_IRQ",
			"LSIOE_GIA_MULTICAST_AGGR_2_AUX_AON_IOBANK_XLSIOE_GPIO22_IRQ",
			"LSIOE_GIA_MULTICAST_AGGR_2_AUX_AON_IOBANK_XLSIOE_GPIO23_IRQ",
			"LSIOE_GIA_MULTICAST_AGGR_2_AUX_AON_IOBANK_XLSIOE_GPIO24_IRQ",
			"LSIOE_GIA_MULTICAST_AGGR_2_AUX_AON_IOBANK_XLSIOE_GPIO25_IRQ",
			"LSIOE_GIA_MULTICAST_AGGR_2_AUX_AON_IOBANK_XLSIOE_GPIO26_IRQ",
			"LSIOE_GIA_MULTICAST_AGGR_2_AUX_AON_IOBANK_XLSIOE_GPIO27_IRQ",
			"LSIOE_GIA_MULTICAST_AGGR_2_AUX_AON_IOBANK_XLSIOE_GPIO28_IRQ",
			"LSIOE_GIA_MULTICAST_AGGR_2_AUX_AON_IOBANK_XLSIOE_GPIO29_IRQ",
			"LSIOE_GIA_MULTICAST_AGGR_2_AUX_AON_IOBANK_XLSIOE_GPIO30_IRQ",
			"LSIOE_GIA_MULTICAST_AGGR_2_AUX_AON_IOBANK_XLSIOE_GPIO31_IRQ",
			"LSIOE_GIA_MULTICAST_AGGR_2_AUX_AON_IOBANK_XLSIOE_GPIO32_IRQ",
			"LSIOE_GIA_MULTICAST_AGGR_2_AUX_AON_IOBANK_XLSIOE_GPIO33_IRQ",
			"LSIOE_GIA_MULTICAST_AGGR_2_AUX_AON_IOBANK_XLSIOE_I23C8_SCL_IRQ",
			"LSIOE_GIA_MULTICAST_AGGR_2_AUX_AON_IOBANK_XLSIOE_I23C8_SDA_IRQ",
			"LSIOE_GIA_MULTICAST_AGGR_2_AUX_AON_IOBANK_XLSIOE_GPIO34_IRQ",
			"LSIOE_GIA_MULTICAST_AGGR_2_AUX_AON_IOBANK_XLSIOE_I23C9_SCL_IRQ",
			"LSIOE_GIA_MULTICAST_AGGR_2_AUX_AON_IOBANK_XLSIOE_I23C9_SDA_IRQ",
			"LSIOE_GIA_MULTICAST_AGGR_2_AUX_AON_IOBANK_XLSIOE_SPIU5_SCLK_RTSN_IRQ",
			"LSIOE_GIA_MULTICAST_AGGR_2_AUX_AON_IOBANK_XLSIOE_SPIU5_MOSI_TXD_IRQ",
			"LSIOE_GIA_MULTICAST_AGGR_2_AUX_AON_IOBANK_XLSIOE_SPIU5_MISO_RXD_IRQ",
			"LSIOE_GIA_MULTICAST_AGGR_2_AUX_AON_IOBANK_XLSIOE_SPIU5_CSN_CTSN_IRQ",
			"LSIOE_GIA_MULTICAST_AGGR_2_AUX_AON_IOBANK_XLSIOE_GPIO35_IRQ",
			"LSIOE_GIA_MULTICAST_AGGR_2_AUX_AON_IOBANK_XLSIOE_GPIO36_IRQ",
			"LSIOE_GIA_MULTICAST_AGGR_2_AUX_AON_IOBANK_XLSIOE_GPIO37_IRQ",
			"TEST_LINE_31";
	};

	lsios_multicast_aggr_1_test: lsios_multicast_aggr_1_test {
		compatible = "google,gia-test";
		power-domains = <&sswrp_lsio_s_pd>;
		interrupt-parent = <&lsios_multicast_aggr_1>;
		interrupts =
			<LSIOS_GIA_MULTICAST_AGGR_1_AUX_AON_RFW0_NS_INTR>,
			<LSIOS_GIA_MULTICAST_AGGR_1_AUX_AON_RFW1_NS_INTR>,
			<LSIOS_GIA_MULTICAST_AGGR_1_AUX_GEM0_IRQ>,
			<LSIOS_GIA_MULTICAST_AGGR_1_AUX_AON_GP_CSR_RESERVED0_RES0_R_0>,
			<LSIOS_GIA_MULTICAST_AGGR_1_AUX_AON_GP_CSR_RESERVED0_RES0_R_1>,
			<LSIOS_GIA_MULTICAST_AGGR_1_AUX_AON_GP_CSR_RESERVED0_RES0_R_2>,
			<LSIOS_GIA_MULTICAST_AGGR_1_AUX_AON_GP_CSR_RESERVED0_RES0_R_3>,
			<LSIOS_GIA_MULTICAST_AGGR_1_AUX_AON_GP_CSR_RESERVED0_RES0_R_4>,
			<LSIOS_GIA_MULTICAST_AGGR_1_AUX_AON_GP_CSR_RESERVED0_RES0_R_5>,
			<LSIOS_GIA_MULTICAST_AGGR_1_AUX_AON_GP_CSR_RESERVED0_RES0_R_6>,
			<LSIOS_GIA_MULTICAST_AGGR_1_AUX_AON_GP_CSR_RESERVED0_RES0_R_7>,
			<LSIOS_GIA_MULTICAST_AGGR_1_AUX_AON_IOBANK_XLSIOS_PRE_OCP_GPU_IRQ>,
			<LSIOS_GIA_MULTICAST_AGGR_1_AUX_AON_IOBANK_XLSIOS_SOFT_PRE_OCP_GPU_IRQ>,
			<LSIOS_GIA_MULTICAST_AGGR_1_IP_TOP_SPI_0_SSI_INTR>,
			<LSIOS_GIA_MULTICAST_AGGR_1_IP_TOP_SPI_1_SSI_INTR>,
			<LSIOS_GIA_MULTICAST_AGGR_1_IP_TOP_SPI_2_SSI_INTR>,
			<LSIOS_GIA_MULTICAST_AGGR_1_IP_TOP_SPI_3_SSI_INTR>,
			<LSIOS_GIA_MULTICAST_AGGR_1_IP_TOP_UART_0_INTR>,
			<LSIOS_GIA_MULTICAST_AGGR_1_IP_TOP_UART_1_INTR>,
			<LSIOS_GIA_MULTICAST_AGGR_1_IP_TOP_UART_2_INTR>,
			<LSIOS_GIA_MULTICAST_AGGR_1_IP_TOP_I3C_0_IC_INTR>,
			<LSIOS_GIA_MULTICAST_AGGR_1_IP_TOP_I3C_1_IC_INTR>,
			<LSIOS_GIA_MULTICAST_AGGR_1_IP_TOP_I3C_2_IC_INTR>,
			<LSIOS_GIA_MULTICAST_AGGR_1_IP_TOP_I3C_3_IC_INTR>,
			<LSIOS_GIA_MULTICAST_AGGR_1_IP_TOP_I3C_4_IC_INTR>,
			<LSIOS_GIA_MULTICAST_AGGR_1_IP_TOP_I2C_0_IC_INTR>,
			<LSIOS_GIA_MULTICAST_AGGR_1_IP_TOP_I2C_1_IC_INTR>,
			<LSIOS_GIA_MULTICAST_AGGR_1_IP_TOP_I2C_2_IC_INTR>,
			<LSIOS_GIA_MULTICAST_AGGR_1_IP_TOP_I2C_3_IC_INTR>,
			<LSIOS_GIA_MULTICAST_AGGR_1_IP_TOP_I2C_4_IC_INTR>,
			<LSIOS_GIA_MULTICAST_AGGR_1_IP_TOP_QSPI_SSI_INTR>,
			<LSIOS_GIA_MULTICAST_AGGR_1_AUX_AON_IOBANK_XLSIOS_MCLK1_IRQ>;
		interrupt-names =
			"LSIOS_GIA_MULTICAST_AGGR_1_AUX_AON_RFW0_NS_INTR",
			"LSIOS_GIA_MULTICAST_AGGR_1_AUX_AON_RFW1_NS_INTR",
			"LSIOS_GIA_MULTICAST_AGGR_1_AUX_GEM0_IRQ",
			"LSIOS_GIA_MULTICAST_AGGR_1_AUX_AON_GP_CSR_RESERVED0_RES0_R_0",
			"LSIOS_GIA_MULTICAST_AGGR_1_AUX_AON_GP_CSR_RESERVED0_RES0_R_1",
			"LSIOS_GIA_MULTICAST_AGGR_1_AUX_AON_GP_CSR_RESERVED0_RES0_R_2",
			"LSIOS_GIA_MULTICAST_AGGR_1_AUX_AON_GP_CSR_RESERVED0_RES0_R_3",
			"LSIOS_GIA_MULTICAST_AGGR_1_AUX_AON_GP_CSR_RESERVED0_RES0_R_4",
			"LSIOS_GIA_MULTICAST_AGGR_1_AUX_AON_GP_CSR_RESERVED0_RES0_R_5",
			"LSIOS_GIA_MULTICAST_AGGR_1_AUX_AON_GP_CSR_RESERVED0_RES0_R_6",
			"LSIOS_GIA_MULTICAST_AGGR_1_AUX_AON_GP_CSR_RESERVED0_RES0_R_7",
			"LSIOS_GIA_MULTICAST_AGGR_1_AUX_AON_IOBANK_XLSIOS_PRE_OCP_GPU_IRQ",
			"LSIOS_GIA_MULTICAST_AGGR_1_AUX_AON_IOBANK_XLSIOS_SOFT_PRE_OCP_GPU_IRQ",
			"LSIOS_GIA_MULTICAST_AGGR_1_IP_TOP_SPI_0_SSI_INTR",
			"LSIOS_GIA_MULTICAST_AGGR_1_IP_TOP_SPI_1_SSI_INTR",
			"LSIOS_GIA_MULTICAST_AGGR_1_IP_TOP_SPI_2_SSI_INTR",
			"LSIOS_GIA_MULTICAST_AGGR_1_IP_TOP_SPI_3_SSI_INTR",
			"LSIOS_GIA_MULTICAST_AGGR_1_IP_TOP_UART_0_INTR",
			"LSIOS_GIA_MULTICAST_AGGR_1_IP_TOP_UART_1_INTR",
			"LSIOS_GIA_MULTICAST_AGGR_1_IP_TOP_UART_2_INTR",
			"LSIOS_GIA_MULTICAST_AGGR_1_IP_TOP_I3C_0_IC_INTR",
			"LSIOS_GIA_MULTICAST_AGGR_1_IP_TOP_I3C_1_IC_INTR",
			"LSIOS_GIA_MULTICAST_AGGR_1_IP_TOP_I3C_2_IC_INTR",
			"LSIOS_GIA_MULTICAST_AGGR_1_IP_TOP_I3C_3_IC_INTR",
			"LSIOS_GIA_MULTICAST_AGGR_1_IP_TOP_I3C_4_IC_INTR",
			"LSIOS_GIA_MULTICAST_AGGR_1_IP_TOP_I2C_0_IC_INTR",
			"LSIOS_GIA_MULTICAST_AGGR_1_IP_TOP_I2C_1_IC_INTR",
			"LSIOS_GIA_MULTICAST_AGGR_1_IP_TOP_I2C_2_IC_INTR",
			"LSIOS_GIA_MULTICAST_AGGR_1_IP_TOP_I2C_3_IC_INTR",
			"LSIOS_GIA_MULTICAST_AGGR_1_IP_TOP_I2C_4_IC_INTR",
			"LSIOS_GIA_MULTICAST_AGGR_1_IP_TOP_QSPI_SSI_INTR",
			"LSIOS_GIA_MULTICAST_AGGR_1_AUX_AON_IOBANK_XLSIOS_MCLK1_IRQ";
	};

	lsios_multicast_aggr_2_test: lsios_multicast_aggr_2_test {
		compatible = "google,gia-test";
		power-domains = <&sswrp_lsio_s_pd>;
		interrupt-parent = <&lsios_multicast_aggr_2>;
		interrupts =
			<LSIOS_GIA_MULTICAST_AGGR_2_IP_TOP_PWM_TMR_INTR>,
			<LSIOS_GIA_MULTICAST_AGGR_2_IP_TOP_PWM_TMR1_INTR>,
			<LSIOS_GIA_MULTICAST_AGGR_2_IP_TOP_PWM_TMR2_INTR>,
			<LSIOS_GIA_MULTICAST_AGGR_2_IP_TOP_PWM_TMR3_INTR>,
			<LSIOS_GIA_MULTICAST_AGGR_2_IP_TOP_PWM_TMR4_INTR>,
			<LSIOS_GIA_MULTICAST_AGGR_2_AUX_AON_IOBANK_XLSIOS_MCLK2_IRQ>,
			<LSIOS_GIA_MULTICAST_AGGR_2_AUX_AON_IOBANK_XLSIOS_MCLK3_IRQ>,
			<LSIOS_GIA_MULTICAST_AGGR_2_AUX_AON_IOBANK_XLSIOS_MCLK4_IRQ>,
			<LSIOS_GIA_MULTICAST_AGGR_2_AUX_AON_IOBANK_XLSIOS_MCLK5_IRQ>,
			<LSIOS_GIA_MULTICAST_AGGR_2_AUX_AON_IOBANK_XLSIOS_MCLK6_IRQ>,
			<LSIOS_GIA_MULTICAST_AGGR_2_AUX_AON_IOBANK_XLSIOS_MCLK7_IRQ>,
			<LSIOS_GIA_MULTICAST_AGGR_2_AUX_AON_IOBANK_XLSIOS_I23C0_SCL_IRQ>,
			<LSIOS_GIA_MULTICAST_AGGR_2_AUX_AON_IOBANK_XLSIOS_I23C0_SDA_IRQ>,
			<LSIOS_GIA_MULTICAST_AGGR_2_AUX_AON_IOBANK_XLSIOS_I23C1_SCL_IRQ>,
			<LSIOS_GIA_MULTICAST_AGGR_2_AUX_AON_IOBANK_XLSIOS_I23C1_SDA_IRQ>,
			<LSIOS_GIA_MULTICAST_AGGR_2_AUX_AON_IOBANK_XLSIOS_I23C2_SCL_IRQ>,
			<LSIOS_GIA_MULTICAST_AGGR_2_AUX_AON_IOBANK_XLSIOS_I23C2_SDA_IRQ>,
			<LSIOS_GIA_MULTICAST_AGGR_2_AUX_AON_IOBANK_XLSIOS_GPIO0_IRQ>,
			<LSIOS_GIA_MULTICAST_AGGR_2_AUX_AON_IOBANK_XLSIOS_GPIO1_IRQ>,
			<LSIOS_GIA_MULTICAST_AGGR_2_AUX_AON_IOBANK_XLSIOS_SPIU0_SCLK_RTSN_IRQ>,
			<LSIOS_GIA_MULTICAST_AGGR_2_AUX_AON_IOBANK_XLSIOS_SPIU0_MOSI_TXD_IRQ>,
			<LSIOS_GIA_MULTICAST_AGGR_2_AUX_AON_IOBANK_XLSIOS_SPIU0_MISO_RXD_IRQ>,
			<LSIOS_GIA_MULTICAST_AGGR_2_AUX_AON_IOBANK_XLSIOS_SPIU0_CSN_CTSN_IRQ>,
			<LSIOS_GIA_MULTICAST_AGGR_2_AUX_AON_IOBANK_XLSIOS_I23C3_SCL_IRQ>,
			<LSIOS_GIA_MULTICAST_AGGR_2_AUX_AON_IOBANK_XLSIOS_I23C3_SDA_IRQ>,
			<LSIOS_GIA_MULTICAST_AGGR_2_AUX_AON_IOBANK_XLSIOS_GPIO2_IRQ>,
			<LSIOS_GIA_MULTICAST_AGGR_2_AUX_AON_IOBANK_XLSIOS_GPIO3_IRQ>,
			<LSIOS_GIA_MULTICAST_AGGR_2_AUX_AON_IOBANK_XLSIOS_PWM_0_IRQ>,
			<LSIOS_GIA_MULTICAST_AGGR_2_AUX_AON_IOBANK_XLSIOS_PWM_1_IRQ>,
			<LSIOS_GIA_MULTICAST_AGGR_2_AUX_AON_IOBANK_XLSIOS_VSYNC1_IRQ>,
			<LSIOS_GIA_MULTICAST_AGGR_2_AUX_AON_IOBANK_XLSIOS_VSYNC2_IRQ>,
			<LSIOS_GIA_MULTICAST_AGGR_2_AUX_AON_IOBANK_XLSIOS_VSYNC3_IRQ>;
		interrupt-names =
			"LSIOS_GIA_MULTICAST_AGGR_2_IP_TOP_PWM_TMR_INTR",
			"LSIOS_GIA_MULTICAST_AGGR_2_IP_TOP_PWM_TMR1_INTR",
			"LSIOS_GIA_MULTICAST_AGGR_2_IP_TOP_PWM_TMR2_INTR",
			"LSIOS_GIA_MULTICAST_AGGR_2_IP_TOP_PWM_TMR3_INTR",
			"LSIOS_GIA_MULTICAST_AGGR_2_IP_TOP_PWM_TMR4_INTR",
			"LSIOS_GIA_MULTICAST_AGGR_2_AUX_AON_IOBANK_XLSIOS_MCLK2_IRQ",
			"LSIOS_GIA_MULTICAST_AGGR_2_AUX_AON_IOBANK_XLSIOS_MCLK3_IRQ",
			"LSIOS_GIA_MULTICAST_AGGR_2_AUX_AON_IOBANK_XLSIOS_MCLK4_IRQ",
			"LSIOS_GIA_MULTICAST_AGGR_2_AUX_AON_IOBANK_XLSIOS_MCLK5_IRQ",
			"LSIOS_GIA_MULTICAST_AGGR_2_AUX_AON_IOBANK_XLSIOS_MCLK6_IRQ",
			"LSIOS_GIA_MULTICAST_AGGR_2_AUX_AON_IOBANK_XLSIOS_MCLK7_IRQ",
			"LSIOS_GIA_MULTICAST_AGGR_2_AUX_AON_IOBANK_XLSIOS_I23C0_SCL_IRQ",
			"LSIOS_GIA_MULTICAST_AGGR_2_AUX_AON_IOBANK_XLSIOS_I23C0_SDA_IRQ",
			"LSIOS_GIA_MULTICAST_AGGR_2_AUX_AON_IOBANK_XLSIOS_I23C1_SCL_IRQ",
			"LSIOS_GIA_MULTICAST_AGGR_2_AUX_AON_IOBANK_XLSIOS_I23C1_SDA_IRQ",
			"LSIOS_GIA_MULTICAST_AGGR_2_AUX_AON_IOBANK_XLSIOS_I23C2_SCL_IRQ",
			"LSIOS_GIA_MULTICAST_AGGR_2_AUX_AON_IOBANK_XLSIOS_I23C2_SDA_IRQ",
			"LSIOS_GIA_MULTICAST_AGGR_2_AUX_AON_IOBANK_XLSIOS_GPIO0_IRQ",
			"LSIOS_GIA_MULTICAST_AGGR_2_AUX_AON_IOBANK_XLSIOS_GPIO1_IRQ",
			"LSIOS_GIA_MULTICAST_AGGR_2_AUX_AON_IOBANK_XLSIOS_SPIU0_SCLK_RTSN_IRQ",
			"LSIOS_GIA_MULTICAST_AGGR_2_AUX_AON_IOBANK_XLSIOS_SPIU0_MOSI_TXD_IRQ",
			"LSIOS_GIA_MULTICAST_AGGR_2_AUX_AON_IOBANK_XLSIOS_SPIU0_MISO_RXD_IRQ",
			"LSIOS_GIA_MULTICAST_AGGR_2_AUX_AON_IOBANK_XLSIOS_SPIU0_CSN_CTSN_IRQ",
			"LSIOS_GIA_MULTICAST_AGGR_2_AUX_AON_IOBANK_XLSIOS_I23C3_SCL_IRQ",
			"LSIOS_GIA_MULTICAST_AGGR_2_AUX_AON_IOBANK_XLSIOS_I23C3_SDA_IRQ",
			"LSIOS_GIA_MULTICAST_AGGR_2_AUX_AON_IOBANK_XLSIOS_GPIO2_IRQ",
			"LSIOS_GIA_MULTICAST_AGGR_2_AUX_AON_IOBANK_XLSIOS_GPIO3_IRQ",
			"LSIOS_GIA_MULTICAST_AGGR_2_AUX_AON_IOBANK_XLSIOS_PWM_0_IRQ",
			"LSIOS_GIA_MULTICAST_AGGR_2_AUX_AON_IOBANK_XLSIOS_PWM_1_IRQ",
			"LSIOS_GIA_MULTICAST_AGGR_2_AUX_AON_IOBANK_XLSIOS_VSYNC1_IRQ",
			"LSIOS_GIA_MULTICAST_AGGR_2_AUX_AON_IOBANK_XLSIOS_VSYNC2_IRQ",
			"LSIOS_GIA_MULTICAST_AGGR_2_AUX_AON_IOBANK_XLSIOS_VSYNC3_IRQ";
	};

	lsios_multicast_aggr_3_test: lsios_multicast_aggr_3_test {
		compatible = "google,gia-test";
		power-domains = <&sswrp_lsio_s_pd>;
		interrupt-parent = <&lsios_multicast_aggr_3>;
		interrupts =
			<LSIOS_GIA_MULTICAST_AGGR_3_AUX_AON_IOBANK_XLSIOS_VSYNC4_IRQ>,
			<LSIOS_GIA_MULTICAST_AGGR_3_AUX_AON_IOBANK_XLSIOS_VSYNC6_IRQ>,
			<LSIOS_GIA_MULTICAST_AGGR_3_AUX_AON_IOBANK_XLSIOS_VSYNC7_IRQ>,
			<LSIOS_GIA_MULTICAST_AGGR_3_AUX_AON_IOBANK_XLSIOS_PWM_2_IRQ>,
			<LSIOS_GIA_MULTICAST_AGGR_3_AUX_AON_IOBANK_XLSIOS_GPIO4_IRQ>,
			<LSIOS_GIA_MULTICAST_AGGR_3_AUX_AON_IOBANK_XLSIOS_GPIO5_IRQ>,
			<LSIOS_GIA_MULTICAST_AGGR_3_AUX_AON_IOBANK_XLSIOS_GPIO6_IRQ>,
			<LSIOS_GIA_MULTICAST_AGGR_3_AUX_AON_IOBANK_XLSIOS_GPIO7_IRQ>,
			<LSIOS_GIA_MULTICAST_AGGR_3_AUX_AON_IOBANK_XLSIOS_GPIO8_IRQ>,
			<LSIOS_GIA_MULTICAST_AGGR_3_AUX_AON_IOBANK_XLSIOS_GPIO9_IRQ>,
			<LSIOS_GIA_MULTICAST_AGGR_3_AUX_AON_IOBANK_XLSIOS_GPIO10_IRQ>,
			<LSIOS_GIA_MULTICAST_AGGR_3_AUX_AON_IOBANK_XLSIOS_GPIO11_IRQ>,
			<LSIOS_GIA_MULTICAST_AGGR_3_AUX_AON_IOBANK_XLSIOS_MCLK0_IRQ>,
			<LSIOS_GIA_MULTICAST_AGGR_3_AUX_AON_IOBANK_XLSIOS_GPIO12_IRQ>,
			<LSIOS_GIA_MULTICAST_AGGR_3_AUX_AON_IOBANK_XLSIOS_GPIO13_IRQ>,
			<LSIOS_GIA_MULTICAST_AGGR_3_AUX_AON_IOBANK_XLSIOS_GPIO14_IRQ>,
			<LSIOS_GIA_MULTICAST_AGGR_3_AUX_AON_IOBANK_XLSIOS_GPIO15_IRQ>,
			<LSIOS_GIA_MULTICAST_AGGR_3_AUX_AON_IOBANK_XLSIOS_VSYNC0_IRQ>,
			<LSIOS_GIA_MULTICAST_AGGR_3_AUX_AON_IOBANK_XLSIOS_I23C4_SCL_IRQ>,
			<LSIOS_GIA_MULTICAST_AGGR_3_AUX_AON_IOBANK_XLSIOS_I23C4_SDA_IRQ>,
			<LSIOS_GIA_MULTICAST_AGGR_3_AUX_AON_IOBANK_XLSIOS_VSYNC5_IRQ>,
			<LSIOS_GIA_MULTICAST_AGGR_3_AUX_AON_IOBANK_XLSIOS_SPIU1_SCLK_RTSN_IRQ>,
			<LSIOS_GIA_MULTICAST_AGGR_3_AUX_AON_IOBANK_XLSIOS_SPIU1_MOSI_TXD_IRQ>,
			<LSIOS_GIA_MULTICAST_AGGR_3_AUX_AON_IOBANK_XLSIOS_SPIU1_MISO_RXD_IRQ>,
			<LSIOS_GIA_MULTICAST_AGGR_3_AUX_AON_IOBANK_XLSIOS_SPIU1_CSN_CTSN_IRQ>,
			<LSIOS_GIA_MULTICAST_AGGR_3_AUX_AON_IOBANK_XLSIOS_SPIU2_SCLK_RTSN_IRQ>,
			<LSIOS_GIA_MULTICAST_AGGR_3_AUX_AON_IOBANK_XLSIOS_SPIU2_MOSI_TXD_IRQ>,
			<LSIOS_GIA_MULTICAST_AGGR_3_AUX_AON_IOBANK_XLSIOS_SPIU2_MISO_RXD_IRQ>,
			<LSIOS_GIA_MULTICAST_AGGR_3_AUX_AON_IOBANK_XLSIOS_SPIU2_CSN_CTSN_IRQ>,
			<LSIOS_GIA_MULTICAST_AGGR_3_AUX_AON_IOBANK_XLSIOS_SPIU3_SCLK_RTSN_IRQ>,
			<LSIOS_GIA_MULTICAST_AGGR_3_AUX_AON_IOBANK_XLSIOS_SPIU3_MOSI_TXD_IRQ>,
			<LSIOS_GIA_MULTICAST_AGGR_3_AUX_AON_IOBANK_XLSIOS_SPIU3_MISO_RXD_IRQ>;
		interrupt-names =
			"LSIOS_GIA_MULTICAST_AGGR_3_AUX_AON_IOBANK_XLSIOS_VSYNC4_IRQ",
			"LSIOS_GIA_MULTICAST_AGGR_3_AUX_AON_IOBANK_XLSIOS_VSYNC6_IRQ",
			"LSIOS_GIA_MULTICAST_AGGR_3_AUX_AON_IOBANK_XLSIOS_VSYNC7_IRQ",
			"LSIOS_GIA_MULTICAST_AGGR_3_AUX_AON_IOBANK_XLSIOS_PWM_2_IRQ",
			"LSIOS_GIA_MULTICAST_AGGR_3_AUX_AON_IOBANK_XLSIOS_GPIO4_IRQ",
			"LSIOS_GIA_MULTICAST_AGGR_3_AUX_AON_IOBANK_XLSIOS_GPIO5_IRQ",
			"LSIOS_GIA_MULTICAST_AGGR_3_AUX_AON_IOBANK_XLSIOS_GPIO6_IRQ",
			"LSIOS_GIA_MULTICAST_AGGR_3_AUX_AON_IOBANK_XLSIOS_GPIO7_IRQ",
			"LSIOS_GIA_MULTICAST_AGGR_3_AUX_AON_IOBANK_XLSIOS_GPIO8_IRQ",
			"LSIOS_GIA_MULTICAST_AGGR_3_AUX_AON_IOBANK_XLSIOS_GPIO9_IRQ",
			"LSIOS_GIA_MULTICAST_AGGR_3_AUX_AON_IOBANK_XLSIOS_GPIO10_IRQ",
			"LSIOS_GIA_MULTICAST_AGGR_3_AUX_AON_IOBANK_XLSIOS_GPIO11_IRQ",
			"LSIOS_GIA_MULTICAST_AGGR_3_AUX_AON_IOBANK_XLSIOS_MCLK0_IRQ",
			"LSIOS_GIA_MULTICAST_AGGR_3_AUX_AON_IOBANK_XLSIOS_GPIO12_IRQ",
			"LSIOS_GIA_MULTICAST_AGGR_3_AUX_AON_IOBANK_XLSIOS_GPIO13_IRQ",
			"LSIOS_GIA_MULTICAST_AGGR_3_AUX_AON_IOBANK_XLSIOS_GPIO14_IRQ",
			"LSIOS_GIA_MULTICAST_AGGR_3_AUX_AON_IOBANK_XLSIOS_GPIO15_IRQ",
			"LSIOS_GIA_MULTICAST_AGGR_3_AUX_AON_IOBANK_XLSIOS_VSYNC0_IRQ",
			"LSIOS_GIA_MULTICAST_AGGR_3_AUX_AON_IOBANK_XLSIOS_I23C4_SCL_IRQ",
			"LSIOS_GIA_MULTICAST_AGGR_3_AUX_AON_IOBANK_XLSIOS_I23C4_SDA_IRQ",
			"LSIOS_GIA_MULTICAST_AGGR_3_AUX_AON_IOBANK_XLSIOS_VSYNC5_IRQ",
			"LSIOS_GIA_MULTICAST_AGGR_3_AUX_AON_IOBANK_XLSIOS_SPIU1_SCLK_RTSN_IRQ",
			"LSIOS_GIA_MULTICAST_AGGR_3_AUX_AON_IOBANK_XLSIOS_SPIU1_MOSI_TXD_IRQ",
			"LSIOS_GIA_MULTICAST_AGGR_3_AUX_AON_IOBANK_XLSIOS_SPIU1_MISO_RXD_IRQ",
			"LSIOS_GIA_MULTICAST_AGGR_3_AUX_AON_IOBANK_XLSIOS_SPIU1_CSN_CTSN_IRQ",
			"LSIOS_GIA_MULTICAST_AGGR_3_AUX_AON_IOBANK_XLSIOS_SPIU2_SCLK_RTSN_IRQ",
			"LSIOS_GIA_MULTICAST_AGGR_3_AUX_AON_IOBANK_XLSIOS_SPIU2_MOSI_TXD_IRQ",
			"LSIOS_GIA_MULTICAST_AGGR_3_AUX_AON_IOBANK_XLSIOS_SPIU2_MISO_RXD_IRQ",
			"LSIOS_GIA_MULTICAST_AGGR_3_AUX_AON_IOBANK_XLSIOS_SPIU2_CSN_CTSN_IRQ",
			"LSIOS_GIA_MULTICAST_AGGR_3_AUX_AON_IOBANK_XLSIOS_SPIU3_SCLK_RTSN_IRQ",
			"LSIOS_GIA_MULTICAST_AGGR_3_AUX_AON_IOBANK_XLSIOS_SPIU3_MOSI_TXD_IRQ",
			"LSIOS_GIA_MULTICAST_AGGR_3_AUX_AON_IOBANK_XLSIOS_SPIU3_MISO_RXD_IRQ";
	};

	lsios_multicast_aggr_4_test: lsios_multicast_aggr_4_test {
		compatible = "google,gia-test";
		power-domains = <&sswrp_lsio_s_pd>;
		interrupt-parent = <&lsios_multicast_aggr_4>;
		interrupts =
			<LSIOS_GIA_MULTICAST_AGGR_4_AUX_AON_IOBANK_XLSIOS_SPIU3_CSN_CTSN_IRQ>,
			<LSIOS_GIA_MULTICAST_AGGR_4_AUX_AON_IOBANK_XLSIOS_GPIO17_IRQ>,
			<LSIOS_GIA_MULTICAST_AGGR_4_AUX_AON_IOBANK_XLSIOS_GPIO18_IRQ>,
			<31>;
		interrupt-names =
			"LSIOS_GIA_MULTICAST_AGGR_4_AUX_AON_IOBANK_XLSIOS_SPIU3_CSN_CTSN_IRQ",
			"LSIOS_GIA_MULTICAST_AGGR_4_AUX_AON_IOBANK_XLSIOS_GPIO17_IRQ",
			"LSIOS_GIA_MULTICAST_AGGR_4_AUX_AON_IOBANK_XLSIOS_GPIO18_IRQ",
			"TEST_LINE_31";
	};

	pcie_multicast_aggr_3_test: pcie_multicast_aggr_3_test {
		compatible = "google,gia-test";
		power-domains = <&sswrp_pcie_pd>;
		interrupt-parent = <&pcie_multicast_aggr_3>;
		interrupts =
			<PCIE_GIA_MULTICAST_AGGR_3_TOP_WRAPPER_TOP_PCIE0_PCIE_INT_0>,
			<PCIE_GIA_MULTICAST_AGGR_3_TOP_WRAPPER_TOP_PCIE0_MSI_CTRL_INT>,
			<PCIE_GIA_MULTICAST_AGGR_3_TOP_WRAPPER_TOP_PCIE0_LEGACY_INTA>,
			<PCIE_GIA_MULTICAST_AGGR_3_TOP_WRAPPER_TOP_PCIE0_LEGACY_INTB>,
			<PCIE_GIA_MULTICAST_AGGR_3_TOP_WRAPPER_TOP_PCIE0_LEGACY_INTC>,
			<PCIE_GIA_MULTICAST_AGGR_3_TOP_WRAPPER_TOP_PCIE0_LEGACY_INTD>,
			<PCIE_GIA_MULTICAST_AGGR_3_TOP_WRAPPER_TOP_PCIE0_EDMA_INT_0>,
			<PCIE_GIA_MULTICAST_AGGR_3_TOP_WRAPPER_TOP_PCIE0_EDMA_INT_1>,
			<PCIE_GIA_MULTICAST_AGGR_3_TOP_WRAPPER_TOP_PCIE0_EDMA_INT_2>,
			<PCIE_GIA_MULTICAST_AGGR_3_TOP_WRAPPER_TOP_PCIE0_EDMA_INT_3>,
			<PCIE_GIA_MULTICAST_AGGR_3_TOP_WRAPPER_TOP_PCIE0_USP_EQ_REDO_EXECUTED_INT>,
			<PCIE_GIA_MULTICAST_AGGR_3_TOP_WRAPPER_TOP_PCIE0_RADM_CPL_TIMEOUT_INT>,
			<PCIE_GIA_MULTICAST_AGGR_3_TOP_WRAPPER_TOP_PCIE0_LTSSM_INT>,
			<PCIE_GIA_MULTICAST_AGGR_3_TOP_WRAPPER_TOP_PCIE1_PCIE_INT_0>,
			<PCIE_GIA_MULTICAST_AGGR_3_TOP_WRAPPER_TOP_PCIE1_MSI_CTRL_INT>,
			<PCIE_GIA_MULTICAST_AGGR_3_TOP_WRAPPER_TOP_PCIE1_LEGACY_INTA>,
			<PCIE_GIA_MULTICAST_AGGR_3_TOP_WRAPPER_TOP_PCIE1_LEGACY_INTB>,
			<PCIE_GIA_MULTICAST_AGGR_3_TOP_WRAPPER_TOP_PCIE1_LEGACY_INTC>,
			<PCIE_GIA_MULTICAST_AGGR_3_TOP_WRAPPER_TOP_PCIE1_LEGACY_INTD>,
			<PCIE_GIA_MULTICAST_AGGR_3_TOP_WRAPPER_TOP_PCIE1_EDMA_INT_0>,
			<PCIE_GIA_MULTICAST_AGGR_3_TOP_WRAPPER_TOP_PCIE1_EDMA_INT_1>,
			<PCIE_GIA_MULTICAST_AGGR_3_TOP_WRAPPER_TOP_PCIE1_EDMA_INT_2>,
			<PCIE_GIA_MULTICAST_AGGR_3_TOP_WRAPPER_TOP_PCIE1_EDMA_INT_3>,
			<PCIE_GIA_MULTICAST_AGGR_3_TOP_WRAPPER_TOP_PCIE1_USP_EQ_REDO_EXECUTED_INT>,
			<PCIE_GIA_MULTICAST_AGGR_3_TOP_WRAPPER_TOP_PCIE1_RADM_CPL_TIMEOUT_INT>,
			<PCIE_GIA_MULTICAST_AGGR_3_TOP_WRAPPER_TOP_PCIE1_LTSSM_INT>,
			<PCIE_GIA_MULTICAST_AGGR_3_AUX_AON_LPCM_RFW_NS_INTR>,
			<PCIE_GIA_MULTICAST_AGGR_3_AUX_XFW_WRAPPER_RFW_AUX_NS_INTR>,
			<PCIE_GIA_MULTICAST_AGGR_3_AUX_XFW_WRAPPER_RFW_NOA_NS_INTR>,
			<PCIE_GIA_MULTICAST_AGGR_3_AUX_AXIM_ACCESS_CNTL_MFW_NS_INTR>,
			<PCIE_GIA_MULTICAST_AGGR_3_AUX_SLV_MFW_NS_INTR>,
			<PCIE_GIA_MULTICAST_AGGR_3_AUX_XFW_WRAPPER_MFW_NS_INTR>;
		interrupt-names =
			"PCIE_GIA_MULTICAST_AGGR_3_TOP_WRAPPER_TOP_PCIE0_PCIE_INT_0",
			"PCIE_GIA_MULTICAST_AGGR_3_TOP_WRAPPER_TOP_PCIE0_MSI_CTRL_INT",
			"PCIE_GIA_MULTICAST_AGGR_3_TOP_WRAPPER_TOP_PCIE0_LEGACY_INTA",
			"PCIE_GIA_MULTICAST_AGGR_3_TOP_WRAPPER_TOP_PCIE0_LEGACY_INTB",
			"PCIE_GIA_MULTICAST_AGGR_3_TOP_WRAPPER_TOP_PCIE0_LEGACY_INTC",
			"PCIE_GIA_MULTICAST_AGGR_3_TOP_WRAPPER_TOP_PCIE0_LEGACY_INTD",
			"PCIE_GIA_MULTICAST_AGGR_3_TOP_WRAPPER_TOP_PCIE0_EDMA_INT_0",
			"PCIE_GIA_MULTICAST_AGGR_3_TOP_WRAPPER_TOP_PCIE0_EDMA_INT_1",
			"PCIE_GIA_MULTICAST_AGGR_3_TOP_WRAPPER_TOP_PCIE0_EDMA_INT_2",
			"PCIE_GIA_MULTICAST_AGGR_3_TOP_WRAPPER_TOP_PCIE0_EDMA_INT_3",
			"PCIE_GIA_MULTICAST_AGGR_3_TOP_WRAPPER_TOP_PCIE0_USP_EQ_REDO_EXECUTED_INT",
			"PCIE_GIA_MULTICAST_AGGR_3_TOP_WRAPPER_TOP_PCIE0_RADM_CPL_TIMEOUT_INT",
			"PCIE_GIA_MULTICAST_AGGR_3_TOP_WRAPPER_TOP_PCIE0_LTSSM_INT",
			"PCIE_GIA_MULTICAST_AGGR_3_TOP_WRAPPER_TOP_PCIE1_PCIE_INT_0",
			"PCIE_GIA_MULTICAST_AGGR_3_TOP_WRAPPER_TOP_PCIE1_MSI_CTRL_INT",
			"PCIE_GIA_MULTICAST_AGGR_3_TOP_WRAPPER_TOP_PCIE1_LEGACY_INTA",
			"PCIE_GIA_MULTICAST_AGGR_3_TOP_WRAPPER_TOP_PCIE1_LEGACY_INTB",
			"PCIE_GIA_MULTICAST_AGGR_3_TOP_WRAPPER_TOP_PCIE1_LEGACY_INTC",
			"PCIE_GIA_MULTICAST_AGGR_3_TOP_WRAPPER_TOP_PCIE1_LEGACY_INTD",
			"PCIE_GIA_MULTICAST_AGGR_3_TOP_WRAPPER_TOP_PCIE1_EDMA_INT_0",
			"PCIE_GIA_MULTICAST_AGGR_3_TOP_WRAPPER_TOP_PCIE1_EDMA_INT_1",
			"PCIE_GIA_MULTICAST_AGGR_3_TOP_WRAPPER_TOP_PCIE1_EDMA_INT_2",
			"PCIE_GIA_MULTICAST_AGGR_3_TOP_WRAPPER_TOP_PCIE1_EDMA_INT_3",
			"PCIE_GIA_MULTICAST_AGGR_3_TOP_WRAPPER_TOP_PCIE1_USP_EQ_REDO_EXECUTED_INT",
			"PCIE_GIA_MULTICAST_AGGR_3_TOP_WRAPPER_TOP_PCIE1_RADM_CPL_TIMEOUT_INT",
			"PCIE_GIA_MULTICAST_AGGR_3_TOP_WRAPPER_TOP_PCIE1_LTSSM_INT",
			"PCIE_GIA_MULTICAST_AGGR_3_AUX_AON_LPCM_RFW_NS_INTR",
			"PCIE_GIA_MULTICAST_AGGR_3_AUX_XFW_WRAPPER_RFW_AUX_NS_INTR",
			"PCIE_GIA_MULTICAST_AGGR_3_AUX_XFW_WRAPPER_RFW_NOA_NS_INTR",
			"PCIE_GIA_MULTICAST_AGGR_3_AUX_AXIM_ACCESS_CNTL_MFW_NS_INTR",
			"PCIE_GIA_MULTICAST_AGGR_3_AUX_SLV_MFW_NS_INTR",
			"PCIE_GIA_MULTICAST_AGGR_3_AUX_XFW_WRAPPER_MFW_NS_INTR";
	};

	pcie_multicast_aggr_5_test: pcie_multicast_aggr_5_test {
		compatible = "google,gia-test";
		power-domains = <&sswrp_pcie_pd>;
		interrupt-parent = <&pcie_multicast_aggr_5>;
		interrupts =
			<PCIE_GIA_MULTICAST_AGGR_5_AUX_AON_GP_SS_CSR_INST_SPARE_INTR_LEVEL_SPARE_INTR_R_0>,
			<PCIE_GIA_MULTICAST_AGGR_5_AUX_AON_GP_SS_CSR_INST_SPARE_INTR_LEVEL_SPARE_INTR_R_1>,
			<PCIE_GIA_MULTICAST_AGGR_5_AUX_AON_GP_SS_CSR_INST_SPARE_INTR_LEVEL_SPARE_INTR_R_2>,
			<PCIE_GIA_MULTICAST_AGGR_5_AUX_AON_GP_SS_CSR_INST_SPARE_INTR_LEVEL_SPARE_INTR_R_3>,
			<PCIE_GIA_MULTICAST_AGGR_5_AUX_AON_GP_SS_CSR_INST_SPARE_INTR_LEVEL_SPARE_INTR_R_4>,
			<PCIE_GIA_MULTICAST_AGGR_5_AUX_AON_GP_SS_CSR_INST_SPARE_INTR_LEVEL_SPARE_INTR_R_5>,
			<PCIE_GIA_MULTICAST_AGGR_5_AUX_AON_GP_SS_CSR_INST_SPARE_INTR_LEVEL_SPARE_INTR_R_6>,
			<PCIE_GIA_MULTICAST_AGGR_5_AUX_AON_GP_SS_CSR_INST_SPARE_INTR_LEVEL_SPARE_INTR_R_7>,
			<PCIE_GIA_MULTICAST_AGGR_5_AUX_BK_XPCIE_PCIE0_CLKREQN0_IRQ>,
			<PCIE_GIA_MULTICAST_AGGR_5_AUX_BK_XPCIE_PCIE0_PERSTN0_IRQ>,
			<PCIE_GIA_MULTICAST_AGGR_5_AUX_BK_XPCIE_PCIE0_CLKREQN1_IRQ>,
			<PCIE_GIA_MULTICAST_AGGR_5_AUX_BK_XPCIE_PCIE0_PERSTN1_IRQ>,
			<PCIE_GIA_MULTICAST_AGGR_5_AUX_DPA_DPA_DMA_IRQ_0>,
			<PCIE_GIA_MULTICAST_AGGR_5_AUX_DPA_DPA_DMA_IRQ_1>,
			<PCIE_GIA_MULTICAST_AGGR_5_AUX_DPA_DPA_DMA_IRQ_2>,
			<PCIE_GIA_MULTICAST_AGGR_5_AUX_DPA_DPA_DMA_IRQ_3>,
			<PCIE_GIA_MULTICAST_AGGR_5_AUX_DPA_DPA_DMA_IRQ_ABORT>,
			<31>;
		interrupt-names =
			"PCIE_GIA_MULTICAST_AGGR_5_AUX_AON_GP_SS_CSR_INST_SPARE_INTR_LEVEL_SPARE_INTR_R_0",
			"PCIE_GIA_MULTICAST_AGGR_5_AUX_AON_GP_SS_CSR_INST_SPARE_INTR_LEVEL_SPARE_INTR_R_1",
			"PCIE_GIA_MULTICAST_AGGR_5_AUX_AON_GP_SS_CSR_INST_SPARE_INTR_LEVEL_SPARE_INTR_R_2",
			"PCIE_GIA_MULTICAST_AGGR_5_AUX_AON_GP_SS_CSR_INST_SPARE_INTR_LEVEL_SPARE_INTR_R_3",
			"PCIE_GIA_MULTICAST_AGGR_5_AUX_AON_GP_SS_CSR_INST_SPARE_INTR_LEVEL_SPARE_INTR_R_4",
			"PCIE_GIA_MULTICAST_AGGR_5_AUX_AON_GP_SS_CSR_INST_SPARE_INTR_LEVEL_SPARE_INTR_R_5",
			"PCIE_GIA_MULTICAST_AGGR_5_AUX_AON_GP_SS_CSR_INST_SPARE_INTR_LEVEL_SPARE_INTR_R_6",
			"PCIE_GIA_MULTICAST_AGGR_5_AUX_AON_GP_SS_CSR_INST_SPARE_INTR_LEVEL_SPARE_INTR_R_7",
			"PCIE_GIA_MULTICAST_AGGR_5_AUX_BK_XPCIE_PCIE0_CLKREQN0_IRQ",
			"PCIE_GIA_MULTICAST_AGGR_5_AUX_BK_XPCIE_PCIE0_PERSTN0_IRQ",
			"PCIE_GIA_MULTICAST_AGGR_5_AUX_BK_XPCIE_PCIE0_CLKREQN1_IRQ",
			"PCIE_GIA_MULTICAST_AGGR_5_AUX_BK_XPCIE_PCIE0_PERSTN1_IRQ",
			"PCIE_GIA_MULTICAST_AGGR_5_AUX_DPA_DPA_DMA_IRQ_0",
			"PCIE_GIA_MULTICAST_AGGR_5_AUX_DPA_DPA_DMA_IRQ_1",
			"PCIE_GIA_MULTICAST_AGGR_5_AUX_DPA_DPA_DMA_IRQ_2",
			"PCIE_GIA_MULTICAST_AGGR_5_AUX_DPA_DPA_DMA_IRQ_3",
			"PCIE_GIA_MULTICAST_AGGR_5_AUX_DPA_DPA_DMA_IRQ_ABORT",
			"TEST_LINE_31";
	};

	pcie_pulse_aggr_2_test: pcie_pulse_aggr_2_test {
		compatible = "google,gia-test";
		power-domains = <&sswrp_pcie_pd>;
		interrupt-parent = <&pcie_pulse_aggr_2>;
		interrupts =
			<PCIE_GIA_PULSE_AGGR_2_TOP_WRAPPER_TOP_PCIE0_RADM_CORRECTABLE_ERR_INT>,
			<PCIE_GIA_PULSE_AGGR_2_TOP_WRAPPER_TOP_PCIE0_RADM_FATAL_ERR_INT>,
			<PCIE_GIA_PULSE_AGGR_2_TOP_WRAPPER_TOP_PCIE0_RADM_NONFATAL_ERR_INT>,
			<PCIE_GIA_PULSE_AGGR_2_TOP_WRAPPER_TOP_PCIE0_TRGT_CPL_TIMEOUT_INT>,
			<PCIE_GIA_PULSE_AGGR_2_TOP_WRAPPER_TOP_PCIE0_SMLH_REQ_RST_NOT_INT>,
			<PCIE_GIA_PULSE_AGGR_2_TOP_WRAPPER_TOP_PCIE1_RADM_CORRECTABLE_ERR_INT>,
			<PCIE_GIA_PULSE_AGGR_2_TOP_WRAPPER_TOP_PCIE1_RADM_FATAL_ERR_INT>,
			<PCIE_GIA_PULSE_AGGR_2_TOP_WRAPPER_TOP_PCIE1_RADM_NONFATAL_ERR_INT>,
			<PCIE_GIA_PULSE_AGGR_2_TOP_WRAPPER_TOP_PCIE1_TRGT_CPL_TIMEOUT_INT>,
			<PCIE_GIA_PULSE_AGGR_2_TOP_WRAPPER_TOP_PCIE1_SMLH_REQ_RST_NOT_INT>,
			<PCIE_GIA_PULSE_AGGR_2_AUX_GSPAN_PCIE0_INITIATOR_ICD_ERR_DSCGT>,
			<PCIE_GIA_PULSE_AGGR_2_AUX_AOSS_INITIATOR_ICD_ERR_DSCGT>,
			<PCIE_GIA_PULSE_AGGR_2_AUX_GSPAN_ATB_INITIATOR_ICD_ERR_DSCGT>,
			<PCIE_GIA_PULSE_AGGR_2_AUX_CTL_PALNE_AGG19_IWL_TX_ERR>,
			<PCIE_GIA_PULSE_AGGR_2_AUX_GSPAN_ILINK_ENDPOINT_RX_ERR>,
			<PCIE_GIA_PULSE_AGGR_2_AUX_AXIM_ACCESS_CNTL_TBU_TBU_RAS_FHI>,
			<PCIE_GIA_PULSE_AGGR_2_AUX_AXIM_ACCESS_CNTL_TBU_TBU_RAS_ERI>,
			<PCIE_GIA_PULSE_AGGR_2_AUX_AXIM_ACCESS_CNTL_TBU_TBU_RAS_CRI>,
			<PCIE_GIA_PULSE_AGGR_2_AUX_AXIM_ACCESS_CNTL_TBU_TBU_PMU_IRPT>,
			<PCIE_GIA_PULSE_AGGR_2_AUX_GSL_AND_PCIE0_RADM_CPL_TIMEOUT_INT_OUT_0>,
			<PCIE_GIA_PULSE_AGGR_2_AUX_GSL_AND_PCIE1_RADM_CPL_TIMEOUT_INT_OUT_0>,
			<PCIE_GIA_PULSE_AGGR_2_AUX_AON_GP_SS_CSR_INST_SPARE_INTR_PULSE_SPARE_INTR_R_2>,
			<PCIE_GIA_PULSE_AGGR_2_AUX_AON_GP_SS_CSR_INST_SPARE_INTR_PULSE_SPARE_INTR_R_3>,
			<PCIE_GIA_PULSE_AGGR_2_AUX_AON_GP_SS_CSR_INST_SPARE_INTR_PULSE_SPARE_INTR_R_4>,
			<PCIE_GIA_PULSE_AGGR_2_AUX_AON_GP_SS_CSR_INST_SPARE_INTR_PULSE_SPARE_INTR_R_5>,
			<PCIE_GIA_PULSE_AGGR_2_AUX_AON_GP_SS_CSR_INST_SPARE_INTR_PULSE_SPARE_INTR_R_6>,
			<PCIE_GIA_PULSE_AGGR_2_AUX_AON_GP_SS_CSR_INST_SPARE_INTR_PULSE_SPARE_INTR_R_7>,
			<31>;
		interrupt-names =
			"PCIE_GIA_PULSE_AGGR_2_TOP_WRAPPER_TOP_PCIE0_RADM_CORRECTABLE_ERR_INT",
			"PCIE_GIA_PULSE_AGGR_2_TOP_WRAPPER_TOP_PCIE0_RADM_FATAL_ERR_INT",
			"PCIE_GIA_PULSE_AGGR_2_TOP_WRAPPER_TOP_PCIE0_RADM_NONFATAL_ERR_INT",
			"PCIE_GIA_PULSE_AGGR_2_TOP_WRAPPER_TOP_PCIE0_TRGT_CPL_TIMEOUT_INT",
			"PCIE_GIA_PULSE_AGGR_2_TOP_WRAPPER_TOP_PCIE0_SMLH_REQ_RST_NOT_INT",
			"PCIE_GIA_PULSE_AGGR_2_TOP_WRAPPER_TOP_PCIE1_RADM_CORRECTABLE_ERR_INT",
			"PCIE_GIA_PULSE_AGGR_2_TOP_WRAPPER_TOP_PCIE1_RADM_FATAL_ERR_INT",
			"PCIE_GIA_PULSE_AGGR_2_TOP_WRAPPER_TOP_PCIE1_RADM_NONFATAL_ERR_INT",
			"PCIE_GIA_PULSE_AGGR_2_TOP_WRAPPER_TOP_PCIE1_TRGT_CPL_TIMEOUT_INT",
			"PCIE_GIA_PULSE_AGGR_2_TOP_WRAPPER_TOP_PCIE1_SMLH_REQ_RST_NOT_INT",
			"PCIE_GIA_PULSE_AGGR_2_AUX_GSPAN_PCIE0_INITIATOR_ICD_ERR_DSCGT",
			"PCIE_GIA_PULSE_AGGR_2_AUX_AOSS_INITIATOR_ICD_ERR_DSCGT",
			"PCIE_GIA_PULSE_AGGR_2_AUX_GSPAN_ATB_INITIATOR_ICD_ERR_DSCGT",
			"PCIE_GIA_PULSE_AGGR_2_AUX_CTL_PALNE_AGG19_IWL_TX_ERR",
			"PCIE_GIA_PULSE_AGGR_2_AUX_GSPAN_ILINK_ENDPOINT_RX_ERR",
			"PCIE_GIA_PULSE_AGGR_2_AUX_AXIM_ACCESS_CNTL_TBU_TBU_RAS_FHI",
			"PCIE_GIA_PULSE_AGGR_2_AUX_AXIM_ACCESS_CNTL_TBU_TBU_RAS_ERI",
			"PCIE_GIA_PULSE_AGGR_2_AUX_AXIM_ACCESS_CNTL_TBU_TBU_RAS_CRI",
			"PCIE_GIA_PULSE_AGGR_2_AUX_AXIM_ACCESS_CNTL_TBU_TBU_PMU_IRPT",
			"PCIE_GIA_PULSE_AGGR_2_AUX_GSL_AND_PCIE0_RADM_CPL_TIMEOUT_INT_OUT_0",
			"PCIE_GIA_PULSE_AGGR_2_AUX_GSL_AND_PCIE1_RADM_CPL_TIMEOUT_INT_OUT_0",
			"PCIE_GIA_PULSE_AGGR_2_AUX_AON_GP_SS_CSR_INST_SPARE_INTR_PULSE_SPARE_INTR_R_2",
			"PCIE_GIA_PULSE_AGGR_2_AUX_AON_GP_SS_CSR_INST_SPARE_INTR_PULSE_SPARE_INTR_R_3",
			"PCIE_GIA_PULSE_AGGR_2_AUX_AON_GP_SS_CSR_INST_SPARE_INTR_PULSE_SPARE_INTR_R_4",
			"PCIE_GIA_PULSE_AGGR_2_AUX_AON_GP_SS_CSR_INST_SPARE_INTR_PULSE_SPARE_INTR_R_5",
			"PCIE_GIA_PULSE_AGGR_2_AUX_AON_GP_SS_CSR_INST_SPARE_INTR_PULSE_SPARE_INTR_R_6",
			"PCIE_GIA_PULSE_AGGR_2_AUX_AON_GP_SS_CSR_INST_SPARE_INTR_PULSE_SPARE_INTR_R_7",
			"TEST_LINE_31";
	};

	pcie_level_aggr_1_test: pcie_level_aggr_1_test {
		compatible = "google,gia-test";
		power-domains = <&sswrp_pcie_pd>;
		interrupt-parent = <&pcie_level_aggr_1>;
		interrupts =
			<PCIE_GIA_LEVEL_AGGR_1_AUX_GIA_PULSE_AGGR_INTR_2>,
			<PCIE_GIA_LEVEL_AGGR_1_AUX_GIA_MULTICAST_AGGR_INTR_4>,
			<PCIE_GIA_LEVEL_AGGR_1_AUX_GIA_PULSE_AGGR_INTR_3>,
			<PCIE_GIA_LEVEL_AGGR_1_AUX_GIA_MULTICAST_AGGR_INTR_5>,
			<PCIE_GIA_LEVEL_AGGR_1_AUX_GIA_MULTICAST_AGGR_INTR_3>,
			<31>;
		interrupt-names =
			"PCIE_GIA_LEVEL_AGGR_1_AUX_GIA_PULSE_AGGR_INTR_2",
			"PCIE_GIA_LEVEL_AGGR_1_AUX_GIA_MULTICAST_AGGR_INTR_4",
			"PCIE_GIA_LEVEL_AGGR_1_AUX_GIA_PULSE_AGGR_INTR_3",
			"PCIE_GIA_LEVEL_AGGR_1_AUX_GIA_MULTICAST_AGGR_INTR_5",
			"PCIE_GIA_LEVEL_AGGR_1_AUX_GIA_MULTICAST_AGGR_INTR_3",
			"TEST_LINE_31";
	};

	tpu_level_aggr_0_test: tpu_level_aggr_0_test {
		compatible = "google,gia-test";
		power-domains = <&sswrp_tpu_pd>;
		interrupt-parent = <&tpu_level_aggr_0>;
		interrupts =
			<TPU_GIA_LEVEL_AGGR_0_AUX_AON_GIA_PULSE_AGGR_INTR_0>,
			<TPU_GIA_LEVEL_AGGR_0_AUX_AON_GIA_MULTICAST_AGGR_INTR_0>,
			<31>;
		interrupt-names =
			"TPU_GIA_LEVEL_AGGR_0_AUX_AON_GIA_PULSE_AGGR_INTR_0",
			"TPU_GIA_LEVEL_AGGR_0_AUX_AON_GIA_MULTICAST_AGGR_INTR_0",
			"TEST_LINE_31";
	};

	tpu_pulse_aggr_0_test: tpu_pulse_aggr_0_test {
		compatible = "google,gia-test";
		power-domains = <&sswrp_tpu_pd>;
		interrupt-parent = <&tpu_pulse_aggr_0>;
		interrupts =
			<TPU_GIA_PULSE_AGGR_0_AUX_LOGIC_SMMU_WRAPPER_TBU0_RAS_FHI>,
			<TPU_GIA_PULSE_AGGR_0_AUX_LOGIC_SMMU_WRAPPER_TBU0_RAS_ERI>,
			<TPU_GIA_PULSE_AGGR_0_AUX_LOGIC_SMMU_WRAPPER_TBU0_RAS_CRI>,
			<TPU_GIA_PULSE_AGGR_0_AUX_LOGIC_SMMU_WRAPPER_TBU0_PMU_IRPT>,
			<TPU_GIA_PULSE_AGGR_0_AUX_LOGIC_SMMU_WRAPPER_TBU1_RAS_FHI>,
			<TPU_GIA_PULSE_AGGR_0_AUX_LOGIC_SMMU_WRAPPER_TBU1_RAS_ERI>,
			<TPU_GIA_PULSE_AGGR_0_AUX_LOGIC_SMMU_WRAPPER_TBU1_RAS_CRI>,
			<TPU_GIA_PULSE_AGGR_0_AUX_LOGIC_SMMU_WRAPPER_TBU1_PMU_IRPT>,
			<TPU_GIA_PULSE_AGGR_0_AUX_LOGIC_SMMU_WRAPPER_TCU_RAS_FHI>,
			<TPU_GIA_PULSE_AGGR_0_AUX_LOGIC_SMMU_WRAPPER_TCU_RAS_ERI>,
			<TPU_GIA_PULSE_AGGR_0_AUX_LOGIC_SMMU_WRAPPER_TCU_RAS_CRI>,
			<TPU_GIA_PULSE_AGGR_0_AUX_LOGIC_SMMU_WRAPPER_TCU_PMU_IRPT>,
			<TPU_GIA_PULSE_AGGR_0_AUX_LOGIC_SMMU_WRAPPER_TCU_PRI_Q_IRPT_NS>,
			<TPU_GIA_PULSE_AGGR_0_AUX_LOGIC_SMMU_WRAPPER_TCU_GLOBAL_IRPT_NS>,
			<TPU_GIA_PULSE_AGGR_0_AUX_LOGIC_SMMU_WRAPPER_TCU_CMD_SYNC_IRPT_NS>,
			<TPU_GIA_PULSE_AGGR_0_AUX_LOGIC_SMMU_WRAPPER_TCU_EVENT_Q_IRPT_NS>,
			<TPU_GIA_PULSE_AGGR_0_AUX_MAIN_GSPAN_ACE5_LITE_INITIATOR0_ICD_ERR_DSCGT>,
			<TPU_GIA_PULSE_AGGR_0_AUX_MAIN_GSPAN_ACE5_LITE_INITIATOR1_ICD_ERR_DSCGT>,
			<TPU_GIA_PULSE_AGGR_0_AUX_TCU_GSPAN_ACE5_LITE_INITIATOR_ICD_ERR_DSCGT>,
			<TPU_GIA_PULSE_AGGR_0_AUX_TRACE_GSPAN_ATB_INITIATOR_ICD_ERR_DSCGT>,
			<31>;
		interrupt-names =
			"TPU_GIA_PULSE_AGGR_0_AUX_LOGIC_SMMU_WRAPPER_TBU0_RAS_FHI",
			"TPU_GIA_PULSE_AGGR_0_AUX_LOGIC_SMMU_WRAPPER_TBU0_RAS_ERI",
			"TPU_GIA_PULSE_AGGR_0_AUX_LOGIC_SMMU_WRAPPER_TBU0_RAS_CRI",
			"TPU_GIA_PULSE_AGGR_0_AUX_LOGIC_SMMU_WRAPPER_TBU0_PMU_IRPT",
			"TPU_GIA_PULSE_AGGR_0_AUX_LOGIC_SMMU_WRAPPER_TBU1_RAS_FHI",
			"TPU_GIA_PULSE_AGGR_0_AUX_LOGIC_SMMU_WRAPPER_TBU1_RAS_ERI",
			"TPU_GIA_PULSE_AGGR_0_AUX_LOGIC_SMMU_WRAPPER_TBU1_RAS_CRI",
			"TPU_GIA_PULSE_AGGR_0_AUX_LOGIC_SMMU_WRAPPER_TBU1_PMU_IRPT",
			"TPU_GIA_PULSE_AGGR_0_AUX_LOGIC_SMMU_WRAPPER_TCU_RAS_FHI",
			"TPU_GIA_PULSE_AGGR_0_AUX_LOGIC_SMMU_WRAPPER_TCU_RAS_ERI",
			"TPU_GIA_PULSE_AGGR_0_AUX_LOGIC_SMMU_WRAPPER_TCU_RAS_CRI",
			"TPU_GIA_PULSE_AGGR_0_AUX_LOGIC_SMMU_WRAPPER_TCU_PMU_IRPT",
			"TPU_GIA_PULSE_AGGR_0_AUX_LOGIC_SMMU_WRAPPER_TCU_PRI_Q_IRPT_NS",
			"TPU_GIA_PULSE_AGGR_0_AUX_LOGIC_SMMU_WRAPPER_TCU_GLOBAL_IRPT_NS",
			"TPU_GIA_PULSE_AGGR_0_AUX_LOGIC_SMMU_WRAPPER_TCU_CMD_SYNC_IRPT_NS",
			"TPU_GIA_PULSE_AGGR_0_AUX_LOGIC_SMMU_WRAPPER_TCU_EVENT_Q_IRPT_NS",
			"TPU_GIA_PULSE_AGGR_0_AUX_MAIN_GSPAN_ACE5_LITE_INITIATOR0_ICD_ERR_DSCGT",
			"TPU_GIA_PULSE_AGGR_0_AUX_MAIN_GSPAN_ACE5_LITE_INITIATOR1_ICD_ERR_DSCGT",
			"TPU_GIA_PULSE_AGGR_0_AUX_TCU_GSPAN_ACE5_LITE_INITIATOR_ICD_ERR_DSCGT",
			"TPU_GIA_PULSE_AGGR_0_AUX_TRACE_GSPAN_ATB_INITIATOR_ICD_ERR_DSCGT",
			"TEST_LINE_31";
	};

};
